[part 1 of 2: packages /VehicleProject to /Cluster]
AUTOSAR XML (schema 00048)
package /VehicleProject
  system System
package /NM
  nm config NmConfig: can-nm-cluster-coupling=coupled-cluster=[ATOM_CANFD_Matrix_CH_V600_202502_CAN, TC37X_VCU_CAN00_CAN, TC37X_VCU_CAN01_CAN, TC37X_VCU_CAN03_CAN, TC37X_VCU_CAN12_CAN]
    5 x can nm cluster, all with nm-msg-cycle-time=0.5, nm-network-timeout=2, nm-repeat-message-time=1.5, nm-user-data-length=6, nm-wait-bus-sleep-time=2:
      ATOM_CANFD_Matrix_CH_V600_202502_CAN: communication-cluster=ATOM_CANFD_Matrix_CH_V600_202502, nm-channel-id=4
        7 x can nm node, all with nm-node-id=28, nm-msg-cycle-offset=0, nm-msg-reduced-time=0.32, nm-range-config={lower-can-id=1280, upper-can-id=1407}:
          ACU: nm-if-ecu=ACU_CAN, nm-passive-mode-enabled=true
          ADCU_CH: nm-if-ecu=ADCU_CH_CAN, nm-passive-mode-enabled=true, rx-nm-pdu=NM_VCU_oATOM_CANFD_Matrix_CH_V600_202502
          AVAS: nm-if-ecu=AVAS_CAN, nm-passive-mode-enabled=true
          CGW_CH: nm-if-ecu=CGW_CH_CAN, rx-nm-pdu=NM_VCU_oATOM_CANFD_Matrix_CH_V600_202502, tx-nm-pdu=NM_CGW_oATOM_CANFD_Matrix_CH_V600_202502
          EPS: nm-if-ecu=EPS_CAN, nm-passive-mode-enabled=true
          IBS_CH: nm-if-ecu=IBS_CH_CAN, nm-passive-mode-enabled=true
          VCU: controller=CT_ATOM_CANFD_Matrix_CH_V600_202502, nm-if-ecu=VCU_CAN, rx-nm-pdu=NM_CGW_oATOM_CANFD_Matrix_CH_V600_202502, tx-nm-pdu=NM_VCU_oATOM_CANFD_Matrix_CH_V600_202502
      TC37X_VCU_CAN00_CAN: communication-cluster=TC37X_VCU_CAN00, nm-channel-id=0
        can nm node GWM: nm-if-ecu=GWM_CAN, nm-node-id=28, rx-nm-pdu=VCU_Tx_51Ch_NM_oTC37X_VCU_CAN00, tx-nm-pdu=VCU_Rx_500h_NM_oTC37X_VCU_CAN00, nm-msg-cycle-offset=0, nm-msg-reduced-time=0.32, nm-range-config={lower-can-id=1024, upper-can-id=1151}
        can nm node Tester: nm-if-ecu=Tester_CAN, nm-node-id=28, nm-passive-mode-enabled=true, nm-msg-cycle-offset=0, nm-msg-reduced-time=0.32, nm-range-config={lower-can-id=1024, upper-can-id=1151}
        can nm node VCU: controller=CT_TC37X_VCU_CAN00, nm-if-ecu=VCU_CAN, nm-node-id=28, rx-nm-pdu=VCU_Rx_500h_NM_oTC37X_VCU_CAN00, tx-nm-pdu=VCU_Tx_51Ch_NM_oTC37X_VCU_CAN00, nm-msg-cycle-offset=0, nm-msg-reduced-time=0.32, nm-range-config={lower-can-id=1024, upper-can-id=1151}
      TC37X_VCU_CAN01_CAN: communication-cluster=TC37X_VCU_CAN01, nm-channel-id=1
        can nm node GWM: nm-if-ecu=GWM_CAN, nm-node-id=28, rx-nm-pdu=VCU_Tx_51Ch_NM_oTC37X_VCU_CAN01, tx-nm-pdu=VCU_Rx_500h_NM_oTC37X_VCU_CAN01, nm-msg-cycle-offset=0, nm-msg-reduced-time=0.32, nm-range-config={lower-can-id=1024, upper-can-id=1151}
        can nm node Tester: nm-if-ecu=Tester_CAN, nm-node-id=28, nm-passive-mode-enabled=true, nm-msg-cycle-offset=0, nm-msg-reduced-time=0.32, nm-range-config={lower-can-id=1024, upper-can-id=1151}
        can nm node VCU: controller=CT_TC37X_VCU_CAN01, nm-if-ecu=VCU_CAN, nm-node-id=28, rx-nm-pdu=VCU_Rx_500h_NM_oTC37X_VCU_CAN01, tx-nm-pdu=VCU_Tx_51Ch_NM_oTC37X_VCU_CAN01, nm-msg-cycle-offset=0, nm-msg-reduced-time=0.32, nm-range-config={lower-can-id=1024, upper-can-id=1151}
      TC37X_VCU_CAN03_CAN: communication-cluster=TC37X_VCU_CAN03, nm-channel-id=3
        can nm node GWM: nm-if-ecu=GWM_CAN, nm-node-id=28, rx-nm-pdu=VCU_Tx_51Ch_NM_oTC37X_VCU_CAN03, tx-nm-pdu=VCU_Rx_500h_NM_oTC37X_VCU_CAN03, nm-msg-cycle-offset=0, nm-msg-reduced-time=0.32, nm-range-config={lower-can-id=1024, upper-can-id=1151}
        can nm node Tester: nm-if-ecu=Tester_CAN, nm-node-id=28, nm-passive-mode-enabled=true, nm-msg-cycle-offset=0, nm-msg-reduced-time=0.32, nm-range-config={lower-can-id=1024, upper-can-id=1151}
        can nm node VCU: controller=CT_TC37X_VCU_CAN03, nm-if-ecu=VCU_CAN, nm-node-id=28, rx-nm-pdu=VCU_Rx_500h_NM_oTC37X_VCU_CAN03, tx-nm-pdu=VCU_Tx_51Ch_NM_oTC37X_VCU_CAN03, nm-msg-cycle-offset=0, nm-msg-reduced-time=0.32, nm-range-config={lower-can-id=1024, upper-can-id=1151}
      TC37X_VCU_CAN12_CAN: communication-cluster=TC37X_VCU_CAN12, nm-channel-id=2
        can nm node GWM: nm-if-ecu=GWM_CAN, nm-node-id=28, rx-nm-pdu=VCU_Tx_51Ch_NM_oTC37X_VCU_CAN12, tx-nm-pdu=VCU_Rx_500h_NM_oTC37X_VCU_CAN12, nm-msg-cycle-offset=0, nm-msg-reduced-time=0.32, nm-range-config={lower-can-id=1024, upper-can-id=1151}
        can nm node Tester: nm-if-ecu=Tester_CAN, nm-node-id=28, nm-passive-mode-enabled=true, nm-msg-cycle-offset=0, nm-msg-reduced-time=0.32, nm-range-config={lower-can-id=1024, upper-can-id=1151}
        can nm node VCU: controller=CT_TC37X_VCU_CAN12, nm-if-ecu=VCU_CAN, nm-node-id=28, rx-nm-pdu=VCU_Rx_500h_NM_oTC37X_VCU_CAN12, tx-nm-pdu=VCU_Tx_51Ch_NM_oTC37X_VCU_CAN12, nm-msg-cycle-offset=0, nm-msg-reduced-time=0.32, nm-range-config={lower-can-id=1024, upper-can-id=1151}
    nm-if-ecus:
      9 x nm ecu, all with nm-node-id-enabled=true, nm-user-data-enabled=true:
        ACU_CAN: nm-passive-mode-enabled=true
        ADCU_CH_CAN: nm-passive-mode-enabled=true
        AVAS_CAN: nm-passive-mode-enabled=true
        CGW_CH_CAN
        EPS_CAN: nm-passive-mode-enabled=true
        GWM_CAN
        IBS_CH_CAN: nm-passive-mode-enabled=true
        Tester_CAN: nm-passive-mode-enabled=true
        VCU_CAN: ecu-instance=VCU
package /TP
  can tp config ATOM_CANFD_Matrix_CH_V600_202502_CAN: communication-cluster=ATOM_CANFD_Matrix_CH_V600_202502, can-tp-ecu{cycle-time-main-function=0.005, ecu-instance=VCU}
    can tp node TN_VCU: connector=CN_ATOM_CANFD_Matrix_CH_V600_202502
  can tp config TC37X_VCU_CAN00_CAN: communication-cluster=TC37X_VCU_CAN00, can-tp-ecu{cycle-time-main-function=0.005, ecu-instance=VCU}
    can tp channel TPCH: channel-id=0, channel-mode=FULL-DUPLEX-MODE
    can-tp-connection addressing-format=STANDARD, can-tp-channel=TPCH, data-pdu=Vcu_Uds_Func_Request_Tp_oTC37X_VCU_CAN00, receiver=TC37X_VCU_CAN00_CAN/TN_VCU, ta-type=FUNCTIONAL, tp-sdu=Vcu_Uds_Func_Request_oTC37X_VCU_CAN00, transmitter=TN_Tester:
      ident Vcu_Uds_Func_Request_oTN_Tester
    can-tp-connection addressing-format=STANDARD, can-tp-channel=TPCH, data-pdu=Vcu_Uds_Phy_Request_Tp_oTC37X_VCU_CAN00, flow-control-pdu=Vcu_Uds_Response_Tp_oTC37X_VCU_CAN00, receiver=TC37X_VCU_CAN00_CAN/TN_VCU, ta-type=PHYSICAL, tp-sdu=Vcu_Uds_Phy_Request_oTC37X_VCU_CAN00, transmitter=TN_Tester:
      ident Vcu_Uds_Phy_Request_oTN_VCU
    can-tp-connection addressing-format=STANDARD, can-tp-channel=TPCH, data-pdu=Vcu_Uds_Response_Tp_oTC37X_VCU_CAN00, flow-control-pdu=Vcu_Uds_Phy_Request_Tp_oTC37X_VCU_CAN00, receiver=TN_Tester, ta-type=PHYSICAL, tp-sdu=Vcu_Uds_Response_oTC37X_VCU_CAN00, transmitter=TC37X_VCU_CAN00_CAN/TN_VCU:
      ident Vcu_Uds_Response_oTN_VCU
    can tp node TN_Tester
    can tp node TN_VCU: connector=CN_TC37X_VCU_CAN00
  lin tp config LIN00: communication-cluster=LIN00
    8 x tp address:
      TA_0x005B: tp-address=91
      TA_0x0062: tp-address=98
      TA_0x0063: tp-address=99
      TA_0x0064: tp-address=100
      TA_0x0065: tp-address=101
      TA_0x0074: tp-address=116
      TA_0x0075: tp-address=117
      TA_0x007E: tp-address=126
    tp-connections:
      data-pdu=MasterReq_Tp_oLIN00, lin-tp-n-sdu=MasterReq_oLIN00, multicast=LIN00/TA_0x007E, receiver=[TN_0x005B_HVCH, TN_0x0062_ERV, TN_0x0063_EXV_1, TN_0x0064_EXV_2, TN_0x0065_SVA, TN_0x0074_PMP_1, TN_0x0075_PMP_2], transmitter=LIN00/TN_Master
      data-pdu=SlaveResp_Tp_oLIN00, flow-control=MasterReq_Tp_oLIN00, lin-tp-n-sdu=SlaveResp_HVCH_oLIN00, receiver=LIN00/TN_Master, transmitter=TN_0x005B_HVCH
      data-pdu=SlaveResp_Tp_oLIN00, flow-control=MasterReq_Tp_oLIN00, lin-tp-n-sdu=SlaveResp_ERV_oLIN00, receiver=LIN00/TN_Master, transmitter=TN_0x0062_ERV
      data-pdu=SlaveResp_Tp_oLIN00, flow-control=MasterReq_Tp_oLIN00, lin-tp-n-sdu=SlaveResp_EXV_1_oLIN00, receiver=LIN00/TN_Master, transmitter=TN_0x0063_EXV_1
      data-pdu=SlaveResp_Tp_oLIN00, flow-control=MasterReq_Tp_oLIN00, lin-tp-n-sdu=SlaveResp_EXV_2_oLIN00, receiver=LIN00/TN_Master, transmitter=TN_0x0064_EXV_2
      data-pdu=SlaveResp_Tp_oLIN00, flow-control=MasterReq_Tp_oLIN00, lin-tp-n-sdu=SlaveResp_SVA_oLIN00, receiver=LIN00/TN_Master, transmitter=TN_0x0065_SVA
      data-pdu=SlaveResp_Tp_oLIN00, flow-control=MasterReq_Tp_oLIN00, lin-tp-n-sdu=SlaveResp_PMP_1_oLIN00, receiver=LIN00/TN_Master, transmitter=TN_0x0074_PMP_1
      data-pdu=SlaveResp_Tp_oLIN00, flow-control=MasterReq_Tp_oLIN00, lin-tp-n-sdu=SlaveResp_PMP_2_oLIN00, receiver=LIN00/TN_Master, transmitter=TN_0x0075_PMP_2
      data-pdu=MasterReq_Tp_oLIN00, flow-control=SlaveResp_Tp_oLIN00, lin-tp-n-sdu=MasterReq_HVCH_oLIN00, receiver=TN_0x005B_HVCH, transmitter=LIN00/TN_Master
      data-pdu=MasterReq_Tp_oLIN00, flow-control=SlaveResp_Tp_oLIN00, lin-tp-n-sdu=MasterReq_ERV_oLIN00, receiver=TN_0x0062_ERV, transmitter=LIN00/TN_Master
      data-pdu=MasterReq_Tp_oLIN00, flow-control=SlaveResp_Tp_oLIN00, lin-tp-n-sdu=MasterReq_EXV_1_oLIN00, receiver=TN_0x0063_EXV_1, transmitter=LIN00/TN_Master
      data-pdu=MasterReq_Tp_oLIN00, flow-control=SlaveResp_Tp_oLIN00, lin-tp-n-sdu=MasterReq_EXV_2_oLIN00, receiver=TN_0x0064_EXV_2, transmitter=LIN00/TN_Master
      data-pdu=MasterReq_Tp_oLIN00, flow-control=SlaveResp_Tp_oLIN00, lin-tp-n-sdu=MasterReq_SVA_oLIN00, receiver=TN_0x0065_SVA, transmitter=LIN00/TN_Master
      data-pdu=MasterReq_Tp_oLIN00, flow-control=SlaveResp_Tp_oLIN00, lin-tp-n-sdu=MasterReq_PMP_1_oLIN00, receiver=TN_0x0074_PMP_1, transmitter=LIN00/TN_Master
      data-pdu=MasterReq_Tp_oLIN00, flow-control=SlaveResp_Tp_oLIN00, lin-tp-n-sdu=MasterReq_PMP_2_oLIN00, receiver=TN_0x0075_PMP_2, transmitter=LIN00/TN_Master
    8 x lin tp node:
      TN_0x005B_HVCH: tp-address=TA_0x005B
      TN_0x0062_ERV: tp-address=TA_0x0062
      TN_0x0063_EXV_1: tp-address=TA_0x0063
      TN_0x0064_EXV_2: tp-address=TA_0x0064
      TN_0x0065_SVA: tp-address=TA_0x0065
      TN_0x0074_PMP_1: tp-address=TA_0x0074
      TN_0x0075_PMP_2: tp-address=TA_0x0075
      TN_Master: connector=CN_LIN00
  lin tp config LIN01: communication-cluster=LIN01
    tp address TA_0x0052: tp-address=82
    tp address TA_0x007E: tp-address=126
    tp-connections:
      data-pdu=MasterReq_Tp_oLIN01, lin-tp-n-sdu=MasterReq_oLIN01, multicast=LIN01/TA_0x007E, receiver=TN_0x0052_GWM, transmitter=LIN01/TN_Master
      data-pdu=SlaveResp_Tp_oLIN01, flow-control=MasterReq_Tp_oLIN01, lin-tp-n-sdu=SlaveResp_GWM_oLIN01, receiver=LIN01/TN_Master, transmitter=TN_0x0052_GWM
      data-pdu=MasterReq_Tp_oLIN01, flow-control=SlaveResp_Tp_oLIN01, lin-tp-n-sdu=MasterReq_GWM_oLIN01, receiver=TN_0x0052_GWM, transmitter=LIN01/TN_Master
    lin tp node TN_0x0052_GWM: tp-address=TA_0x0052
    lin tp node TN_Master: connector=CN_LIN01
package /Cluster
  5 x can cluster, all with protocol-name=CAN:
    ATOM_CANFD_Matrix_CH_V600_202502  # ATOM_CANFD_Matrix_CH_V6.0.0_20250507 | Revision:V1.0, Revision:V1.0.1, Revision:V1.0.1, Revision:V1.0.1, Revision:V1.0.1, Revision:V1.0.2, Revision:V1.0.2, Revision:V1.0.2, Revision:V1.0.2, Revision:V1.0.2, Revision:V1.0.2, Revision:V1.0.2, Revision:V1.0.2, Revision:V1.0.2, Revision:V1.0.2, Revision:V1.0.2, Revision:V1.0.2, Revision:V1.0.2, Revision:V1.0.2, Revision:V1.0.2, Revision:V1.0.2, Revision:V1.0.2, Revision:V1.0.2, Revision:V1.0.2, Revision:V1.1, Revision:V1.1, Revision:V1.1, Revision:V1.1, Revision:V1.1, Revision:V1.1, Revision:V1.1, Revision:V1.1, Revision:V1.1, Revision:V1.1, Revision:V1.1, Revision:V1.1, Revision:V1.1, Revision:V1.1, Revision:V1.1, Revision:V1.1, Revision:V1.1, Revision:V1.1, Revision:V1.1, Revision:V1.1, Revision:V1.1, Revision:V1.1, Revision:V1.2, Revision:V0.1.3, Revision:V0.1.3, Revision:V0.1.3, Revision:V0.1.3, Revision:V0.1.3, Revision:V0.1.3, Revision:V0.1.3, Revision:V0.1.3, Revision:V0.1.3, Revision:V0.1.3, Revision:V0.1.3, Revision:V0.1.3, Revision:
      can physical channel CHNL: comm-connectors=CN_ATOM_CANFD_Matrix_CH_V600_202502
        frame ACU_01_oATOM_CANFD_Matrix_CH_V600_202502: id 0xF5, to VCU, frame-length=8, can-addressing-mode=STANDARD, can-frame-rx-behavior=ANY, can-frame-tx-behavior=CAN-FD
          pdu ACU_01_oATOM_CANFD_Matrix_CH_V600_202502: length=8, minimum-delay=0, transmission-mode-false-timing=cyclic-timing={time-offset=0, time-period=0.02}, transmission-mode-true-timing=cyclic-timing={time-offset=0, time-period=0.02}, unused-bit-pattern=0
            signal Checksum_0F5_oACU_01_oATOM_CANFD_Matrix_CH_V600_202502: start 7, 8 bit, big-endian, i-signal-type=PRIMITIVE, init-value=0, base-type=uint8, compu-method=CM_Checksum_0F5, data-constr=DC_Checksum_0F5, transfer-property=PENDING, to VCU  # Checksum signal for frame
            signal MessageCounter_0F5_oACU_01_oATOM_CANFD_Matrix_CH_V600_202502: start 11, 4 bit, big-endian, i-signal-type=PRIMITIVE, init-value=0, base-type=uint8, compu-method=CM_MessageCounter_0F5, data-constr=DC_MessageCounter_0F5, transfer-property=PENDING, to VCU  # Message counter signal for frame
            signal ACU_YawRate_oACU_01_oATOM_CANFD_Matrix_CH_V600_202502: start 23, 16 bit, big-endian, i-signal-type=PRIMITIVE, init-value=30000, base-type=uint16, compu-method=CM_ACU_YawRate, data-constr=DC_ACU_YawRate, unit=U_degreesYs, transfer-property=PENDING, to VCU  # Yaw rate (clockwise is negative, counterclockwise is positive)
            signal ACU_YawRateStatus_oACU_01_oATOM_CANFD_Matrix_CH_V600_202502: start 39, 2 bit, big-endian, i-signal-type=PRIMITIVE, init-value=0, base-type=uint8, compu-method=CM_ACU_YawRateStatus, data-constr=DC_ACU_YawRateStatus, transfer-property=PENDING, to VCU  # Yaw rate status
            mapping SG_ACU_01_SigGroup: i-signal-group=SG_ACU_01_SigGroup_oACU_01_oATOM_CANFD_Matrix_CH_V600_202502, transfer-property=PENDING
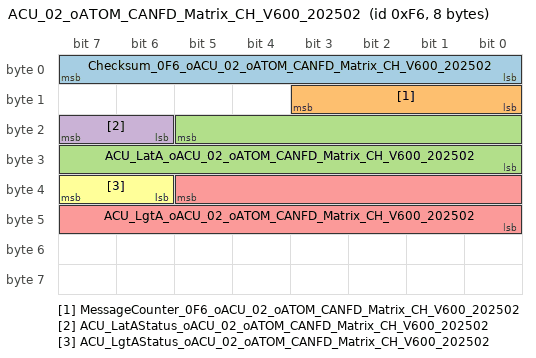
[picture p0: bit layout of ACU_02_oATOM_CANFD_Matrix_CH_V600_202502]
        frame ACU_02_oATOM_CANFD_Matrix_CH_V600_202502: id 0xF6, to VCU, frame-length=8, can-addressing-mode=STANDARD, can-frame-rx-behavior=ANY, can-frame-tx-behavior=CAN-FD
          pdu ACU_02_oATOM_CANFD_Matrix_CH_V600_202502: length=8, minimum-delay=0, transmission-mode-false-timing=cyclic-timing={time-offset=0, time-period=0.02}, transmission-mode-true-timing=cyclic-timing={time-offset=0, time-period=0.02}, unused-bit-pattern=0
            signal Checksum_0F6_oACU_02_oATOM_CANFD_Matrix_CH_V600_202502: start 7, 8 bit, big-endian, i-signal-type=PRIMITIVE, init-value=0, base-type=uint8, compu-method=CM_Checksum_0F6, data-constr=DC_Checksum_0F6, transfer-property=PENDING, to VCU  # Checksum signal for frame
            signal MessageCounter_0F6_oACU_02_oATOM_CANFD_Matrix_CH_V600_202502: start 11, 4 bit, big-endian, i-signal-type=PRIMITIVE, init-value=0, base-type=uint8, compu-method=CM_MessageCounter_0F6, data-constr=DC_MessageCounter_0F6, transfer-property=PENDING, to VCU  # Message counter signal for frame
            signal ACU_LatA_oACU_02_oATOM_CANFD_Matrix_CH_V600_202502: start 21, 14 bit, big-endian, i-signal-type=PRIMITIVE, init-value=4905, base-type=uint16, compu-method=CM_ACU_LatA, data-constr=DC_ACU_LatA, unit=U_mYsX2, transfer-property=PENDING, to VCU  # Lateral acceleration(From the driver's perspective, from left to right is the positive direction of lateral acceleration)
            signal ACU_LatAStatus_oACU_02_oATOM_CANFD_Matrix_CH_V600_202502: start 23, 2 bit, big-endian, i-signal-type=PRIMITIVE, init-value=0, base-type=uint8, compu-method=CM_ACU_LatAStatus, data-constr=DC_ACU_LatAStatus, transfer-property=PENDING, to VCU  # Lateral acceleration status
            signal ACU_LgtA_oACU_02_oATOM_CANFD_Matrix_CH_V600_202502: start 37, 14 bit, big-endian, i-signal-type=PRIMITIVE, init-value=4905, base-type=uint16, compu-method=CM_ACU_LgtA, data-constr=DC_ACU_LgtA, unit=U_mYsX2, transfer-property=PENDING, to VCU  # Longitudinal acceleration(The forward direction of the vehicle is the positive direction of the longitudinal acceleration)
            signal ACU_LgtAStatus_oACU_02_oATOM_CANFD_Matrix_CH_V600_202502: start 39, 2 bit, big-endian, i-signal-type=PRIMITIVE, init-value=0, base-type=uint8, compu-method=CM_ACU_LgtAStatus, data-constr=DC_ACU_LgtAStatus, transfer-property=PENDING, to VCU  # Longitudinal acceleration status
            mapping SG_ACU_02_SigGroup: i-signal-group=SG_ACU_02_SigGroup_oACU_02_oATOM_CANFD_Matrix_CH_V600_202502, transfer-property=PENDING
        frame ACU_info_oATOM_CANFD_Matrix_CH_V600_202502: id 0x97, to VCU, frame-length=8, can-addressing-mode=STANDARD, can-frame-rx-behavior=ANY, can-frame-tx-behavior=CAN-FD
          pdu ACU_info_oATOM_CANFD_Matrix_CH_V600_202502: length=8, minimum-delay=0, transmission-mode-false-timing=cyclic-timing={time-offset=0, time-period=0.02}, transmission-mode-true-timing=cyclic-timing={time-offset=0, time-period=0.02}, unused-bit-pattern=0
            signal Checksum_097_oACU_info_oATOM_CANFD_Matrix_CH_V600_202502: start 7, 8 bit, big-endian, i-signal-type=PRIMITIVE, init-value=0, base-type=uint8, compu-method=CM_Checksum_097, data-constr=DC_Checksum_097, transfer-property=PENDING, to VCU  # Checksum signal for frame
            signal MessageCounter_097_oACU_info_oATOM_CANFD_Matrix_CH_V600_202502: start 11, 4 bit, big-endian, i-signal-type=PRIMITIVE, init-value=0, base-type=uint8, compu-method=CM_MessageCounter_097, data-constr=DC_MessageCounter_097, transfer-property=PENDING, to VCU  # Message counter signal for frame
            signal ACU_CrashOutputStsValid_oACU_info_oATOM_CANFD_Matrix_CH_V600_202502: start 16, 1 bit, big-endian, i-signal-type=PRIMITIVE, init-value=1, base-type=boolean, compu-method=CM_ACU_CrashOutputStsValid, data-constr=DC_ACU_CrashOutputStsValid, transfer-property=PENDING, to VCU  # Collision signal effective indication
            signal ACU_CrashOutputSts_oACU_info_oATOM_CANFD_Matrix_CH_V600_202502: start 23, 5 bit, big-endian, i-signal-type=PRIMITIVE, init-value=0, base-type=uint8, compu-method=CM_ACU_CrashOutputSts, data-constr=DC_ACU_CrashOutputSts, transfer-property=PENDING, to VCU  # Crash Output Status
            signal ACU_PassengerSts_oACU_info_oATOM_CANFD_Matrix_CH_V600_202502: start 25, 1 bit, big-endian, i-signal-type=PRIMITIVE, init-value=0, base-type=boolean, compu-method=CM_ACU_PassengerSts, data-constr=DC_ACU_PassengerSts, transfer-property=PENDING, to VCU  # Passenger seat occupied state
            signal ACU_PassengerSeatBeltStsValid_oACU_info_oATOM_CANFD_Matrix_CH_V600_202502: start 26, 1 bit, big-endian, i-signal-type=PRIMITIVE, init-value=0, base-type=boolean, compu-method=CM_ACU_PassengerSeatBeltStsValid, data-constr=DC_ACU_PassengerSeatBeltStsValid, transfer-property=PENDING, to VCU  # Passenger seat belt status invalid signal
            signal ACU_PassengerSeatBeltSts_oACU_info_oATOM_CANFD_Matrix_CH_V600_202502: start 27, 1 bit, big-endian, i-signal-type=PRIMITIVE, init-value=0, base-type=boolean, compu-method=CM_ACU_PassengerSeatBeltSts, data-constr=DC_ACU_PassengerSeatBeltSts, transfer-property=PENDING, to VCU  # Passenger seat belt status
            signal ACU_DriverSeatBeltStsValid_oACU_info_oATOM_CANFD_Matrix_CH_V600_202502: start 30, 1 bit, big-endian, i-signal-type=PRIMITIVE, init-value=0, base-type=boolean, compu-method=CM_ACU_DriverSeatBeltStsValid, data-constr=DC_ACU_DriverSeatBeltStsValid, transfer-property=PENDING, to VCU  # Driver seat belt state invalid
            signal ACU_DriverSeatBeltSts_oACU_info_oATOM_CANFD_Matrix_CH_V600_202502: start 31, 1 bit, big-endian, i-signal-type=PRIMITIVE, init-value=0, base-type=boolean, compu-method=CM_ACU_DriverSeatBeltSts, data-constr=DC_ACU_DriverSeatBeltSts, transfer-property=PENDING, to VCU  # Driver seat belt status
            signal ACU_SecondLeftSts_oACU_info_oATOM_CANFD_Matrix_CH_V600_202502: start 37, 1 bit, big-endian, i-signal-type=PRIMITIVE, init-value=0, base-type=boolean, compu-method=CM_ACU_SecondLeftSts, data-constr=DC_ACU_SecondLeftSts, transfer-property=PENDING, to VCU  # The left seat of the second row is occupied
            signal ACU_RLSeatBeltStatusValid_oACU_info_oATOM_CANFD_Matrix_CH_V600_202502: start 38, 1 bit, big-endian, i-signal-type=PRIMITIVE, init-value=0, base-type=boolean, compu-method=CM_ACU_RLSeatBeltStatusValid, data-constr=DC_ACU_RLSeatBeltStatusValid, transfer-property=PENDING, to VCU  # Second row seat belt status on the left is valid
            signal ACU_SecondLeftSeatBeltSts_oACU_info_oATOM_CANFD_Matrix_CH_V600_202502: start 39, 1 bit, big-endian, i-signal-type=PRIMITIVE, init-value=0, base-type=boolean, compu-method=CM_ACU_SecondLeftSeatBeltSts, data-constr=DC_ACU_SecondLeftSeatBeltSts, transfer-property=PENDING, to VCU  # Second row left seat belt condition
            signal ACU_SecondRightSts_oACU_info_oATOM_CANFD_Matrix_CH_V600_202502: start 53, 1 bit, big-endian, i-signal-type=PRIMITIVE, init-value=0, base-type=boolean, compu-method=CM_ACU_SecondRightSts, data-constr=DC_ACU_SecondRightSts, transfer-property=PENDING, to VCU  # The right seat of the second row is occupied
            signal ACU_RRSeatBeltStatusValid_oACU_info_oATOM_CANFD_Matrix_CH_V600_202502: start 54, 1 bit, big-endian, i-signal-type=PRIMITIVE, init-value=0, base-type=boolean, compu-method=CM_ACU_RRSeatBeltStatusValid, data-constr=DC_ACU_RRSeatBeltStatusValid, transfer-property=PENDING, to VCU  # Second row seat belt status on the lright is valid
            signal ACU_SecondRightSeatBeltSts_oACU_info_oATOM_CANFD_Matrix_CH_V600_202502: start 55, 1 bit, big-endian, i-signal-type=PRIMITIVE, init-value=0, base-type=boolean, compu-method=CM_ACU_SecondRightSeatBeltSts, data-constr=DC_ACU_SecondRightSeatBeltSts, transfer-property=PENDING, to VCU  # Second row right seat belt status
            signal ACU_WarningLampSts_oACU_info_oATOM_CANFD_Matrix_CH_V600_202502: start 57, 2 bit, big-endian, i-signal-type=PRIMITIVE, init-value=0, base-type=uint8, compu-method=CM_ACU_WarningLampSts, data-constr=DC_ACU_WarningLampSts, transfer-property=PENDING, to VCU  # WarningLampStatus
            signal ACU_PassengerWarningLampSts_oACU_info_oATOM_CANFD_Matrix_CH_V600_202502: start 59, 2 bit, big-endian, i-signal-type=PRIMITIVE, init-value=0, base-type=uint8, compu-method=CM_ACU_PassengerWarningLampSts, data-constr=DC_ACU_PassengerWarningLampSts, transfer-property=PENDING, to VCU  # Passenger Warning Lamp Status
            signal ACU_DriverWarningLampSts_oACU_info_oATOM_CANFD_Matrix_CH_V600_202502: start 61, 2 bit, big-endian, i-signal-type=PRIMITIVE, init-value=0, base-type=uint8, compu-method=CM_ACU_DriverWarningLampSts, data-constr=DC_ACU_DriverWarningLampSts, transfer-property=PENDING, to VCU  # Driver Warning Lamp Status
            signal ACU_PassengerAirbagSts_oACU_info_oATOM_CANFD_Matrix_CH_V600_202502: start 63, 2 bit, big-endian, i-signal-type=PRIMITIVE, init-value=0, base-type=uint8, compu-method=CM_ACU_PassengerAirbagSts, data-constr=DC_ACU_PassengerAirbagSts, transfer-property=PENDING, to VCU  # Passenger Airbag Status, closed or not
            mapping SG_ACU_info_SigGroup: i-signal-group=SG_ACU_info_SigGroup_oACU_info_oATOM_CANFD_Matrix_CH_V600_202502, transfer-property=PENDING
        frame ADCU_ACC_02_oATOM_CANFD_Matrix_CH_V600_202502: id 0xE0, to VCU, frame-length=8, can-addressing-mode=STANDARD, can-frame-rx-behavior=ANY, can-frame-tx-behavior=CAN-FD
          pdu ADCU_ACC_02_oATOM_CANFD_Matrix_CH_V600_202502: length=8, minimum-delay=0, transmission-mode-false-timing=cyclic-timing={time-offset=0, time-period=0.02}, transmission-mode-true-timing=cyclic-timing={time-offset=0, time-period=0.02}, unused-bit-pattern=0
            signal Checksum_0E0_oADCU_ACC_02_oATOM_CANFD_Matrix_CH_V600_202502: start 7, 8 bit, big-endian, i-signal-type=PRIMITIVE, init-value=0, base-type=uint8, compu-method=CM_Checksum_0E0, data-constr=DC_Checksum_0E0, transfer-property=PENDING, to VCU  # Checksum signal for frame
            signal MessageCounter_0E0_oADCU_ACC_02_oATOM_CANFD_Matrix_CH_V600_202502: start 11, 4 bit, big-endian, i-signal-type=PRIMITIVE, init-value=0, base-type=uint8, compu-method=CM_MessageCounter_0E0, data-constr=DC_MessageCounter_0E0, transfer-property=PENDING, to VCU  # Message counter signal for frame
            signal ADCU_ACCDA_HandsOFF_Warning_oADCU_ACC_02_oATOM_CANFD_Matrix_CH_V600_202502: start 18, 3 bit, big-endian, i-signal-type=PRIMITIVE, init-value=0, base-type=uint8, compu-method=CM_ADCU_ACCDA_HandsOFF_Warning, data-constr=DC_ADCU_ACCDA_HandsOFF_Warning, transfer-property=PENDING, to VCU  # ACC/DA Hands off warning
            signal ADCU_ACC_Mode_oADCU_ACC_02_oATOM_CANFD_Matrix_CH_V600_202502: start 21, 3 bit, big-endian, i-signal-type=PRIMITIVE, init-value=0, base-type=uint8, compu-method=CM_ADCU_ACC_Mode, data-constr=DC_ADCU_ACC_Mode, transfer-property=PENDING, to VCU  # ACC mode for system state
            signal ADCU_ACCDA_SYS_Failure_oADCU_ACC_02_oATOM_CANFD_Matrix_CH_V600_202502: start 23, 2 bit, big-endian, i-signal-type=PRIMITIVE, init-value=0, base-type=uint8, compu-method=CM_ADCU_ACCDA_SYS_Failure, data-constr=DC_ADCU_ACCDA_SYS_Failure, transfer-property=PENDING, to VCU  # ACC/DA system failure state If this signal is set to anything other than 0, the IBS shall ignore any requests from ACC
            mapping SG_ADCU_ACC_02_SigGroup: i-signal-group=SG_ADCU_ACC_02_SigGroup_oADCU_ACC_02_oATOM_CANFD_Matrix_CH_V600_202502, transfer-property=PENDING
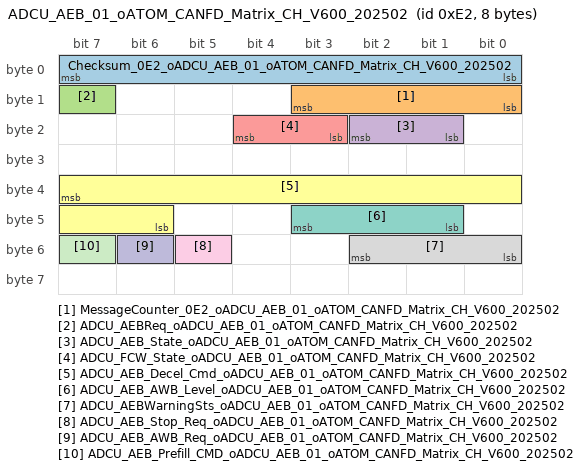
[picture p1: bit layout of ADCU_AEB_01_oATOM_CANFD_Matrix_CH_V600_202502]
        frame ADCU_AEB_01_oATOM_CANFD_Matrix_CH_V600_202502: id 0xE2, to VCU, frame-length=8, can-addressing-mode=STANDARD, can-frame-rx-behavior=ANY, can-frame-tx-behavior=CAN-FD
          pdu ADCU_AEB_01_oATOM_CANFD_Matrix_CH_V600_202502: length=8, minimum-delay=0, transmission-mode-false-timing=cyclic-timing={time-offset=0, time-period=0.02}, transmission-mode-true-timing=cyclic-timing={time-offset=0, time-period=0.02}, unused-bit-pattern=0
            signal Checksum_0E2_oADCU_AEB_01_oATOM_CANFD_Matrix_CH_V600_202502: start 7, 8 bit, big-endian, i-signal-type=PRIMITIVE, init-value=0, base-type=uint8, compu-method=CM_Checksum_0E2, data-constr=DC_Checksum_0E2, transfer-property=PENDING, to VCU  # Checksum signal for frame
            signal MessageCounter_0E2_oADCU_AEB_01_oATOM_CANFD_Matrix_CH_V600_202502: start 11, 4 bit, big-endian, i-signal-type=PRIMITIVE, init-value=0, base-type=uint8, compu-method=CM_MessageCounter_0E2, data-constr=DC_MessageCounter_0E2, transfer-property=PENDING, to VCU  # Message counter signal for frame
            signal ADCU_AEBReq_oADCU_AEB_01_oATOM_CANFD_Matrix_CH_V600_202502: start 15, 1 bit, big-endian, i-signal-type=PRIMITIVE, init-value=0, base-type=boolean, compu-method=CM_ADCU_AEBReq, data-constr=DC_ADCU_AEBReq, transfer-property=PENDING, to VCU  # A control requeset flag for AEB
            signal ADCU_AEB_State_oADCU_AEB_01_oATOM_CANFD_Matrix_CH_V600_202502: start 18, 2 bit, big-endian, i-signal-type=PRIMITIVE, init-value=0, base-type=uint8, compu-method=CM_ADCU_AEB_State, data-constr=DC_ADCU_AEB_State, transfer-property=PENDING, to VCU  # This signal describes the state AEB Function.
            signal ADCU_FCW_State_oADCU_AEB_01_oATOM_CANFD_Matrix_CH_V600_202502: start 20, 2 bit, big-endian, i-signal-type=PRIMITIVE, init-value=0, base-type=uint8, compu-method=CM_ADCU_FCW_State, data-constr=DC_ADCU_FCW_State, transfer-property=PENDING, to VCU  # This signal describes the state FCW Function.
            signal ADCU_AEB_Decel_Cmd_oADCU_AEB_01_oATOM_CANFD_Matrix_CH_V600_202502: start 39, 10 bit, big-endian, i-signal-type=PRIMITIVE, init-value=0, base-type=sint16, compu-method=CM_ADCU_AEB_Decel_Cmd, data-constr=DC_ADCU_AEB_Decel_Cmd, unit=U_mYsX2, transfer-property=PENDING, to VCU  # Depending on the driving situation, ADCU gives IBS the AEB deceleration command. IBS maintains the deceleration.
            signal ADCU_AEB_AWB_Level_oADCU_AEB_01_oATOM_CANFD_Matrix_CH_V600_202502: start 43, 3 bit, big-endian, i-signal-type=PRIMITIVE, init-value=0, base-type=uint8, compu-method=CM_ADCU_AEB_AWB_Level, data-constr=DC_ADCU_AEB_AWB_Level, transfer-property=PENDING, to VCU  # AWB level
            signal ADCU_AEBWarningSts_oADCU_AEB_01_oATOM_CANFD_Matrix_CH_V600_202502: start 50, 3 bit, big-endian, i-signal-type=PRIMITIVE, init-value=0, base-type=uint8, compu-method=CM_ADCU_AEBWarningSts, data-constr=DC_ADCU_AEBWarningSts, transfer-property=PENDING, to VCU  # PEBSWarning,include PreWarning and emergency Warning.
            signal ADCU_AEB_Stop_Req_oADCU_AEB_01_oATOM_CANFD_Matrix_CH_V600_202502: start 53, 1 bit, big-endian, i-signal-type=PRIMITIVE, init-value=0, base-type=boolean, compu-method=CM_ADCU_AEB_Stop_Req, data-constr=DC_ADCU_AEB_Stop_Req, transfer-property=PENDING, to VCU  # A control request flag for vehicle stop. AEB expects vehicle to be controlled to a complete stop and hold its state by ESC.
            signal ADCU_AEB_AWB_Req_oADCU_AEB_01_oATOM_CANFD_Matrix_CH_V600_202502: start 54, 1 bit, big-endian, i-signal-type=PRIMITIVE, init-value=0, base-type=boolean, compu-method=CM_ADCU_AEB_AWB_Req, data-constr=DC_ADCU_AEB_AWB_Req, transfer-property=PENDING, to VCU  # This signal means command to activate AWB
            signal ADCU_AEB_Prefill_CMD_oADCU_AEB_01_oATOM_CANFD_Matrix_CH_V600_202502: start 55, 1 bit, big-endian, i-signal-type=PRIMITIVE, init-value=0, base-type=boolean, compu-method=CM_ADCU_AEB_Prefill_CMD, data-constr=DC_ADCU_AEB_Prefill_CMD, transfer-property=PENDING, to VCU  # This signal means command to activate pre-fill
            mapping SG_ADCU_AEB_01_SigGroup: i-signal-group=SG_ADCU_AEB_01_SigGroup_oADCU_AEB_01_oATOM_CANFD_Matrix_CH_V600_202502, transfer-property=PENDING
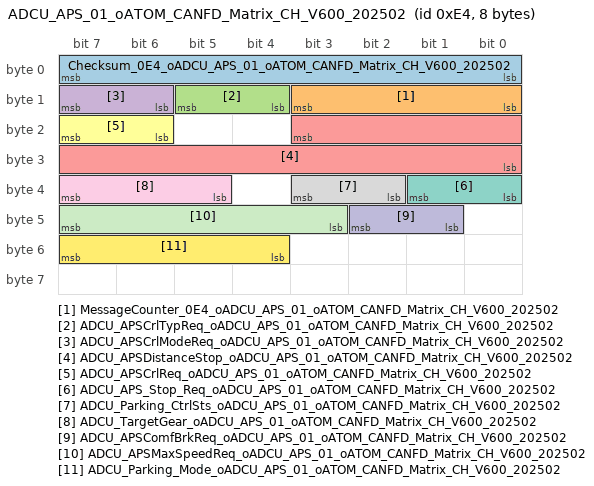
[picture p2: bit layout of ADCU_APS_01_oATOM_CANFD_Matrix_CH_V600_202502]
        frame ADCU_APS_01_oATOM_CANFD_Matrix_CH_V600_202502: id 0xE4, to VCU, frame-length=8, can-addressing-mode=STANDARD, can-frame-rx-behavior=ANY, can-frame-tx-behavior=CAN-FD
          pdu ADCU_APS_01_oATOM_CANFD_Matrix_CH_V600_202502: length=8, minimum-delay=0, transmission-mode-false-timing=cyclic-timing={time-offset=0, time-period=0.02}, transmission-mode-true-timing=cyclic-timing={time-offset=0, time-period=0.02}, unused-bit-pattern=0
            signal Checksum_0E4_oADCU_APS_01_oATOM_CANFD_Matrix_CH_V600_202502: start 7, 8 bit, big-endian, i-signal-type=PRIMITIVE, init-value=0, base-type=uint8, compu-method=CM_Checksum_0E4, data-constr=DC_Checksum_0E4, transfer-property=PENDING, to VCU  # Checksum signal for frame
            signal MessageCounter_0E4_oADCU_APS_01_oATOM_CANFD_Matrix_CH_V600_202502: start 11, 4 bit, big-endian, i-signal-type=PRIMITIVE, init-value=0, base-type=uint8, compu-method=CM_MessageCounter_0E4, data-constr=DC_MessageCounter_0E4, transfer-property=PENDING, to VCU  # Message counter signal for frame
            signal ADCU_APSCrlTypReq_oADCU_APS_01_oATOM_CANFD_Matrix_CH_V600_202502: start 13, 2 bit, big-endian, i-signal-type=PRIMITIVE, init-value=0, base-type=uint8, compu-method=CM_ADCU_APSCrlTypReq, data-constr=DC_ADCU_APSCrlTypReq, transfer-property=PENDING, to VCU  # Request comfort or emergency brake
            signal ADCU_APSCrlModeReq_oADCU_APS_01_oATOM_CANFD_Matrix_CH_V600_202502: start 15, 2 bit, big-endian, i-signal-type=PRIMITIVE, init-value=0, base-type=uint8, compu-method=CM_ADCU_APSCrlModeReq, data-constr=DC_ADCU_APSCrlModeReq, transfer-property=PENDING, to VCU  # Request Low Speed Maneuvering Control Mode (PAS (full/semi auto) or RC)
            signal ADCU_APSDistanceStop_oADCU_APS_01_oATOM_CANFD_Matrix_CH_V600_202502: start 19, 12 bit, big-endian, i-signal-type=PRIMITIVE, init-value=0, base-type=uint16, compu-method=CM_ADCU_APSDistanceStop, data-constr=DC_ADCU_APSDistanceStop, unit=U_cm, transfer-property=PENDING, to VCU  # Stopdistance request
            signal ADCU_APSCrlReq_oADCU_APS_01_oATOM_CANFD_Matrix_CH_V600_202502: start 23, 2 bit, big-endian, i-signal-type=PRIMITIVE, init-value=0, base-type=uint8, compu-method=CM_ADCU_APSCrlReq, data-constr=DC_ADCU_APSCrlReq, transfer-property=PENDING, to VCU  # Request Maneuvering dynamic control function (Driving or Low Speed Maneuvering)
            signal ADCU_APS_Stop_Req_oADCU_APS_01_oATOM_CANFD_Matrix_CH_V600_202502: start 33, 2 bit, big-endian, i-signal-type=PRIMITIVE, init-value=0, base-type=uint8, compu-method=CM_ADCU_APS_Stop_Req, data-constr=DC_ADCU_APS_Stop_Req, transfer-property=PENDING, to VCU  # Request complete stop and hold its state by IBS
            signal ADCU_Parking_CtrlSts_oADCU_APS_01_oATOM_CANFD_Matrix_CH_V600_202502: start 35, 2 bit, big-endian, i-signal-type=PRIMITIVE, init-value=0, base-type=uint8, compu-method=CM_ADCU_Parking_CtrlSts, data-constr=DC_ADCU_Parking_CtrlSts, transfer-property=PENDING, to VCU  # Parking indicator light status
            signal ADCU_TargetGear_oADCU_APS_01_oATOM_CANFD_Matrix_CH_V600_202502: start 39, 3 bit, big-endian, i-signal-type=PRIMITIVE, init-value=0, base-type=uint8, compu-method=CM_ADCU_TargetGear, data-constr=DC_ADCU_TargetGear, transfer-property=PENDING, to VCU  # Shift request signal
            signal ADCU_APSComfBrkReq_oADCU_APS_01_oATOM_CANFD_Matrix_CH_V600_202502: start 42, 2 bit, big-endian, i-signal-type=PRIMITIVE, init-value=0, base-type=uint8, compu-method=CM_ADCU_APSComfBrkReq, data-constr=DC_ADCU_APSComfBrkReq, transfer-property=PENDING, to VCU  # BrakeMode Request
            signal ADCU_APSMaxSpeedReq_oADCU_APS_01_oATOM_CANFD_Matrix_CH_V600_202502: start 47, 5 bit, big-endian, i-signal-type=PRIMITIVE, init-value=0, base-type=uint8, compu-method=CM_ADCU_APSMaxSpeedReq, data-constr=DC_ADCU_APSMaxSpeedReq, unit=U_kmYh, transfer-property=PENDING, to VCU  # V Max request
            signal ADCU_Parking_Mode_oADCU_APS_01_oATOM_CANFD_Matrix_CH_V600_202502: start 55, 4 bit, big-endian, i-signal-type=PRIMITIVE, init-value=0, base-type=uint8, compu-method=CM_ADCU_Parking_Mode, data-constr=DC_ADCU_Parking_Mode, transfer-property=PENDING, to VCU  # APS function status.
            mapping SG_ADCU_APS_01_SigGroup: i-signal-group=SG_ADCU_APS_01_SigGroup_oADCU_APS_01_oATOM_CANFD_Matrix_CH_V600_202502, transfer-property=PENDING
        frame ADCU_APS_02_oATOM_CANFD_Matrix_CH_V600_202502: id 0x20D, to VCU, frame-length=8, can-addressing-mode=STANDARD, can-frame-rx-behavior=ANY, can-frame-tx-behavior=CAN-FD
          pdu ADCU_APS_02_oATOM_CANFD_Matrix_CH_V600_202502: length=8, minimum-delay=0, transmission-mode-false-timing=cyclic-timing={time-offset=0, time-period=0.1}, transmission-mode-true-timing=cyclic-timing={time-offset=0, time-period=0.1}, unused-bit-pattern=0
            signal ADCU_RemoteParkingMode_oADCU_APS_02_oATOM_CANFD_Matrix_CH_V600_202502: start 23, 4 bit, big-endian, i-signal-type=PRIMITIVE, init-value=0, base-type=uint8, compu-method=CM_ADCU_RemoteParkingMode, data-constr=DC_ADCU_RemoteParkingMode, transfer-property=PENDING, to VCU  # Remote parking function status
            mapping SG_ADCU_APS_02_SigGroup: i-signal-group=SG_ADCU_APS_02_SigGroup_oADCU_APS_02_oATOM_CANFD_Matrix_CH_V600_202502, transfer-property=PENDING
        frame ADCU_DA_oATOM_CANFD_Matrix_CH_V600_202502: id 0xE6, to VCU, frame-length=8, can-addressing-mode=STANDARD, can-frame-rx-behavior=ANY, can-frame-tx-behavior=CAN-FD
          pdu ADCU_DA_oATOM_CANFD_Matrix_CH_V600_202502: length=8, minimum-delay=0, transmission-mode-false-timing=cyclic-timing={time-offset=0, time-period=0.1}, transmission-mode-true-timing=cyclic-timing={time-offset=0, time-period=0.1}, unused-bit-pattern=0
            signal Checksum_0E6_oADCU_DA_oATOM_CANFD_Matrix_CH_V600_202502: start 7, 8 bit, big-endian, i-signal-type=PRIMITIVE, init-value=0, base-type=uint8, compu-method=CM_Checksum_0E6, data-constr=DC_Checksum_0E6, transfer-property=PENDING, to VCU  # Checksum signal for frame
            signal MessageCounter_0E6_oADCU_DA_oATOM_CANFD_Matrix_CH_V600_202502: start 11, 4 bit, big-endian, i-signal-type=PRIMITIVE, init-value=0, base-type=uint8, compu-method=CM_MessageCounter_0E6, data-constr=DC_MessageCounter_0E6, transfer-property=PENDING, to VCU  # Message counter signal for frame
            signal ADCU_DA_Mode_oADCU_DA_oATOM_CANFD_Matrix_CH_V600_202502: start 23, 3 bit, big-endian, i-signal-type=PRIMITIVE, init-value=0, base-type=uint8, compu-method=CM_ADCU_DA_Mode, data-constr=DC_ADCU_DA_Mode, transfer-property=PENDING, to VCU  # DA mode for system state
            mapping SG_ADCU_DA_SigGroup: i-signal-group=SG_ADCU_DA_SigGroup_oADCU_DA_oATOM_CANFD_Matrix_CH_V600_202502, transfer-property=PENDING
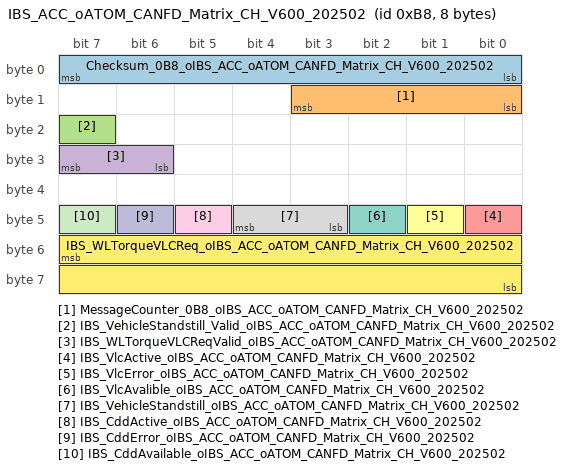
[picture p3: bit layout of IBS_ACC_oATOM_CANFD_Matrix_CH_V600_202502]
        frame IBS_ACC_oATOM_CANFD_Matrix_CH_V600_202502: id 0xB8, to VCU, frame-length=8, can-addressing-mode=STANDARD, can-frame-rx-behavior=ANY, can-frame-tx-behavior=CAN-FD
          pdu IBS_ACC_oATOM_CANFD_Matrix_CH_V600_202502: length=8, minimum-delay=0, transmission-mode-false-timing=cyclic-timing={time-offset=0, time-period=0.02}, transmission-mode-true-timing=cyclic-timing={time-offset=0, time-period=0.02}, unused-bit-pattern=0
            signal Checksum_0B8_oIBS_ACC_oATOM_CANFD_Matrix_CH_V600_202502: start 7, 8 bit, big-endian, i-signal-type=PRIMITIVE, init-value=0, base-type=uint8, compu-method=CM_Checksum_0B8, data-constr=DC_Checksum_0B8, transfer-property=PENDING, to VCU  # Checksum signal for frame
            signal MessageCounter_0B8_oIBS_ACC_oATOM_CANFD_Matrix_CH_V600_202502: start 11, 4 bit, big-endian, i-signal-type=PRIMITIVE, init-value=0, base-type=uint8, compu-method=CM_MessageCounter_0B8, data-constr=DC_MessageCounter_0B8, transfer-property=PENDING, to VCU  # Message counter signal for frame
            signal IBS_VehicleStandstill_Valid_oIBS_ACC_oATOM_CANFD_Matrix_CH_V600_202502: start 23, 1 bit, big-endian, i-signal-type=PRIMITIVE, init-value=0, base-type=boolean, compu-method=CM_IBS_VehicleStandstill_Valid, data-constr=DC_IBS_VehicleStandstill_Valid, transfer-property=PENDING, to VCU  # Validity of indicating signal IBS_vehiclestill
            signal IBS_WLTorqueVLCReqValid_oIBS_ACC_oATOM_CANFD_Matrix_CH_V600_202502: start 31, 2 bit, big-endian, i-signal-type=PRIMITIVE, init-value=0, base-type=uint8, compu-method=CM_IBS_WLTorqueVLCReqValid, data-constr=DC_IBS_WLTorqueVLCReqValid, transfer-property=PENDING, to VCU  # VLC Wheel Torque Request Valid
            signal IBS_VlcActive_oIBS_ACC_oATOM_CANFD_Matrix_CH_V600_202502: start 40, 1 bit, big-endian, i-signal-type=PRIMITIVE, init-value=0, base-type=boolean, compu-method=CM_IBS_VlcActive, data-constr=DC_IBS_VlcActive, transfer-property=PENDING, to VCU  # Indicates VLC is active or not.
            signal IBS_VlcError_oIBS_ACC_oATOM_CANFD_Matrix_CH_V600_202502: start 41, 1 bit, big-endian, i-signal-type=PRIMITIVE, init-value=0, base-type=boolean, compu-method=CM_IBS_VlcError, data-constr=DC_IBS_VlcError, transfer-property=PENDING, to VCU  # Indicate the failure status of VLC.
            signal IBS_VlcAvalible_oIBS_ACC_oATOM_CANFD_Matrix_CH_V600_202502: start 42, 1 bit, big-endian, i-signal-type=PRIMITIVE, init-value=0, base-type=boolean, compu-method=CM_IBS_VlcAvalible, data-constr=DC_IBS_VlcAvalible, transfer-property=PENDING, to VCU  # Indicating whether VLC is basically ready for activation or not. It could be combined with VLCFail.
            signal IBS_VehicleStandstill_oIBS_ACC_oATOM_CANFD_Matrix_CH_V600_202502: start 44, 2 bit, big-endian, i-signal-type=PRIMITIVE, init-value=0, base-type=uint8, compu-method=CM_IBS_VehicleStandstill, data-constr=DC_IBS_VehicleStandstill, transfer-property=PENDING, to VCU  # Indicating whether the vehicle is standstill or not Cannot be set until standstill is surely reached.
            signal IBS_CddActive_oIBS_ACC_oATOM_CANFD_Matrix_CH_V600_202502: start 45, 1 bit, big-endian, i-signal-type=PRIMITIVE, init-value=0, base-type=boolean, compu-method=CM_IBS_CddActive, data-constr=DC_IBS_CddActive, transfer-property=PENDING, to VCU  # Indicate CDD is active or not.
            signal IBS_CddError_oIBS_ACC_oATOM_CANFD_Matrix_CH_V600_202502: start 46, 1 bit, big-endian, i-signal-type=PRIMITIVE, init-value=0, base-type=boolean, compu-method=CM_IBS_CddError, data-constr=DC_IBS_CddError, transfer-property=PENDING, to VCU  # Indicate the failure status of CDD
            signal IBS_CddAvailable_oIBS_ACC_oATOM_CANFD_Matrix_CH_V600_202502: start 47, 1 bit, big-endian, i-signal-type=PRIMITIVE, init-value=0, base-type=boolean, compu-method=CM_IBS_CddAvailable, data-constr=DC_IBS_CddAvailable, transfer-property=PENDING, to VCU  # Indicate CDD is available or not.
            signal IBS_WLTorqueVLCReq_oIBS_ACC_oATOM_CANFD_Matrix_CH_V600_202502: start 55, 16 bit, big-endian, i-signal-type=PRIMITIVE, init-value=0, base-type=sint16, compu-method=CM_IBS_WLTorqueVLCReq, data-constr=DC_IBS_WLTorqueVLCReq, unit=U_Nm, transfer-property=PENDING, to VCU  # VLC Wheel Torque Request
            mapping SG_IBS_ACC_SigGroup: i-signal-group=SG_IBS_ACC_SigGroup_oIBS_ACC_oATOM_CANFD_Matrix_CH_V600_202502, transfer-property=PENDING
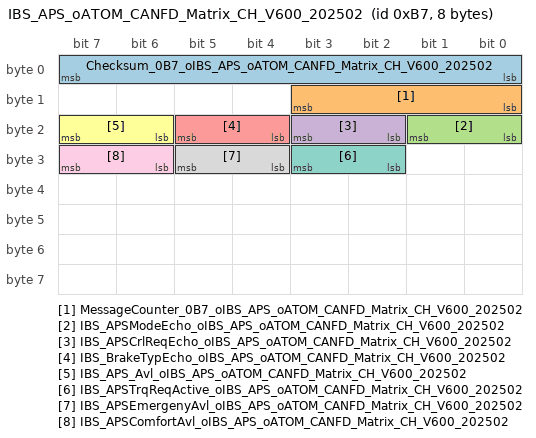
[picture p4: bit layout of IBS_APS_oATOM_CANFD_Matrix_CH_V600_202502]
        frame IBS_APS_oATOM_CANFD_Matrix_CH_V600_202502: id 0xB7, to VCU, frame-length=8, can-addressing-mode=STANDARD, can-frame-rx-behavior=ANY, can-frame-tx-behavior=CAN-FD
          pdu IBS_APS_oATOM_CANFD_Matrix_CH_V600_202502: length=8, minimum-delay=0, transmission-mode-false-timing=cyclic-timing={time-offset=0, time-period=0.02}, transmission-mode-true-timing=cyclic-timing={time-offset=0, time-period=0.02}, unused-bit-pattern=0
            signal Checksum_0B7_oIBS_APS_oATOM_CANFD_Matrix_CH_V600_202502: start 7, 8 bit, big-endian, i-signal-type=PRIMITIVE, init-value=0, base-type=uint8, compu-method=CM_Checksum_0B7, data-constr=DC_Checksum_0B7, transfer-property=PENDING, to VCU  # Checksum signal for frame
            signal MessageCounter_0B7_oIBS_APS_oATOM_CANFD_Matrix_CH_V600_202502: start 11, 4 bit, big-endian, i-signal-type=PRIMITIVE, init-value=0, base-type=uint8, compu-method=CM_MessageCounter_0B7, data-constr=DC_MessageCounter_0B7, transfer-property=PENDING, to VCU  # Message counter signal for frame
            signal IBS_APSModeEcho_oIBS_APS_oATOM_CANFD_Matrix_CH_V600_202502: start 17, 2 bit, big-endian, i-signal-type=PRIMITIVE, init-value=0, base-type=uint8, compu-method=CM_IBS_APSModeEcho, data-constr=DC_IBS_APSModeEcho, transfer-property=PENDING, to VCU  # FeedbackÂ to upper system
            signal IBS_APSCrlReqEcho_oIBS_APS_oATOM_CANFD_Matrix_CH_V600_202502: start 19, 2 bit, big-endian, i-signal-type=PRIMITIVE, init-value=0, base-type=uint8, compu-method=CM_IBS_APSCrlReqEcho, data-constr=DC_IBS_APSCrlReqEcho, transfer-property=PENDING, to VCU  # Feedback control status to upper system
            signal IBS_BrakeTypEcho_oIBS_APS_oATOM_CANFD_Matrix_CH_V600_202502: start 21, 2 bit, big-endian, i-signal-type=PRIMITIVE, init-value=0, base-type=uint8, compu-method=CM_IBS_BrakeTypEcho, data-constr=DC_IBS_BrakeTypEcho, transfer-property=PENDING, to VCU  # Feedback Comfort or emergency to upper system
            signal IBS_APS_Avl_oIBS_APS_oATOM_CANFD_Matrix_CH_V600_202502: start 23, 2 bit, big-endian, i-signal-type=PRIMITIVE, init-value=0, base-type=uint8, compu-method=CM_IBS_APS_Avl, data-constr=DC_IBS_APS_Avl, transfer-property=PENDING, to VCU  # Indicate the function availability
            signal IBS_APSTrqReqActive_oIBS_APS_oATOM_CANFD_Matrix_CH_V600_202502: start 27, 2 bit, big-endian, i-signal-type=PRIMITIVE, init-value=0, base-type=uint8, compu-method=CM_IBS_APSTrqReqActive, data-constr=DC_IBS_APSTrqReqActive, transfer-property=PENDING, to VCU  # APS function activation flag bit
            signal IBS_APSEmergenyAvl_oIBS_APS_oATOM_CANFD_Matrix_CH_V600_202502: start 29, 2 bit, big-endian, i-signal-type=PRIMITIVE, init-value=0, base-type=uint8, compu-method=CM_IBS_APSEmergenyAvl, data-constr=DC_IBS_APSEmergenyAvl, transfer-property=PENDING, to VCU  # Feedback ofÂ APS Emergency Availability
            signal IBS_APSComfortAvl_oIBS_APS_oATOM_CANFD_Matrix_CH_V600_202502: start 31, 2 bit, big-endian, i-signal-type=PRIMITIVE, init-value=0, base-type=uint8, compu-method=CM_IBS_APSComfortAvl, data-constr=DC_IBS_APSComfortAvl, transfer-property=PENDING, to VCU  # Feedback of APS Comfort Availability
            mapping SG_IBS_APS_SigGroup: i-signal-group=SG_IBS_APS_SigGroup_oIBS_APS_oATOM_CANFD_Matrix_CH_V600_202502, transfer-property=PENDING
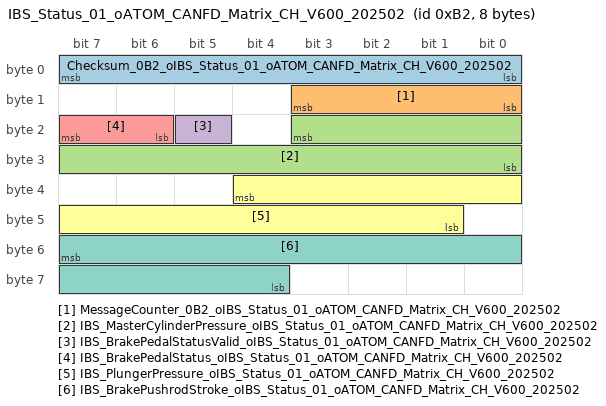
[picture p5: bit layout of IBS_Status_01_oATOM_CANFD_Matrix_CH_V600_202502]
        frame IBS_Status_01_oATOM_CANFD_Matrix_CH_V600_202502: id 0xB2, to VCU, frame-length=8, can-addressing-mode=STANDARD, can-frame-rx-behavior=ANY, can-frame-tx-behavior=CAN-FD
          pdu IBS_Status_01_oATOM_CANFD_Matrix_CH_V600_202502: length=8, minimum-delay=0, transmission-mode-false-timing=cyclic-timing={time-offset=0, time-period=0.02}, transmission-mode-true-timing=cyclic-timing={time-offset=0, time-period=0.02}, unused-bit-pattern=0
            signal Checksum_0B2_oIBS_Status_01_oATOM_CANFD_Matrix_CH_V600_202502: start 7, 8 bit, big-endian, i-signal-type=PRIMITIVE, init-value=0, base-type=uint8, compu-method=CM_Checksum_0B2, data-constr=DC_Checksum_0B2, transfer-property=PENDING, to VCU  # Checksum signal for frame
            signal MessageCounter_0B2_oIBS_Status_01_oATOM_CANFD_Matrix_CH_V600_202502: start 11, 4 bit, big-endian, i-signal-type=PRIMITIVE, init-value=0, base-type=uint8, compu-method=CM_MessageCounter_0B2, data-constr=DC_MessageCounter_0B2, transfer-property=PENDING, to VCU  # Message counter signal for frame
            signal IBS_MasterCylinderPressure_oIBS_Status_01_oATOM_CANFD_Matrix_CH_V600_202502: start 19, 12 bit, big-endian, i-signal-type=PRIMITIVE, init-value=0, base-type=uint16, compu-method=CM_IBS_MasterCylinderPressure, data-constr=DC_IBS_MasterCylinderPressure, unit=U_BAR, transfer-property=PENDING, to VCU  # EN: Master Cylinder Pressure signal
            signal IBS_BrakePedalStatusValid_oIBS_Status_01_oATOM_CANFD_Matrix_CH_V600_202502: start 21, 1 bit, big-endian, i-signal-type=PRIMITIVE, init-value=1, base-type=boolean, compu-method=CM_IBS_BrakePedalStatusValid, data-constr=DC_IBS_BrakePedalStatusValid, transfer-property=PENDING, to VCU  # Brake Pedal Status Valid
            signal IBS_BrakePedalStatus_oIBS_Status_01_oATOM_CANFD_Matrix_CH_V600_202502: start 23, 2 bit, big-endian, i-signal-type=PRIMITIVE, init-value=0, base-type=uint8, compu-method=CM_IBS_BrakePedalStatus, data-constr=DC_IBS_BrakePedalStatus, transfer-property=PENDING, to VCU  # Brake Pedal Status
            signal IBS_PlungerPressure_oIBS_Status_01_oATOM_CANFD_Matrix_CH_V600_202502: start 36, 12 bit, big-endian, i-signal-type=PRIMITIVE, init-value=0, base-type=sint16, compu-method=CM_IBS_PlungerPressure, data-constr=DC_IBS_PlungerPressure, unit=U_BAR, transfer-property=PENDING, to VCU  # pressure of PSU
            signal IBS_BrakePushrodStroke_oIBS_Status_01_oATOM_CANFD_Matrix_CH_V600_202502: start 55, 12 bit, big-endian, i-signal-type=PRIMITIVE, init-value=0, base-type=sint16, compu-method=CM_IBS_BrakePushrodStroke, data-constr=DC_IBS_BrakePushrodStroke, unit=U_mm, transfer-property=PENDING, to VCU  # IBS pushrod stroke
            mapping SG_IBS_Status_01_SigGroup: i-signal-group=SG_IBS_Status_01_SigGroup_oIBS_Status_01_oATOM_CANFD_Matrix_CH_V600_202502, transfer-property=PENDING
        frame IBS_Status_02_oATOM_CANFD_Matrix_CH_V600_202502: id 0xB3, to VCU, frame-length=8, can-addressing-mode=STANDARD, can-frame-rx-behavior=ANY, can-frame-tx-behavior=CAN-FD
          pdu IBS_Status_02_oATOM_CANFD_Matrix_CH_V600_202502: length=8, minimum-delay=0, transmission-mode-false-timing=cyclic-timing={time-offset=0, time-period=0.02}, transmission-mode-true-timing=cyclic-timing={time-offset=0, time-period=0.02}, unused-bit-pattern=0
            signal Checksum_0B3_oIBS_Status_02_oATOM_CANFD_Matrix_CH_V600_202502: start 7, 8 bit, big-endian, i-signal-type=PRIMITIVE, init-value=0, base-type=uint8, compu-method=CM_Checksum_0B3, data-constr=DC_Checksum_0B3, transfer-property=PENDING, to VCU  # Checksum signal for frame
            signal MessageCounter_0B3_oIBS_Status_02_oATOM_CANFD_Matrix_CH_V600_202502: start 11, 4 bit, big-endian, i-signal-type=PRIMITIVE, init-value=0, base-type=uint8, compu-method=CM_MessageCounter_0B3, data-constr=DC_MessageCounter_0B3, transfer-property=PENDING, to VCU  # Message counter signal for frame
            signal IBS_EPBworkingSts_oIBS_Status_02_oATOM_CANFD_Matrix_CH_V600_202502: start 19, 3 bit, big-endian, i-signal-type=PRIMITIVE, init-value=0, base-type=uint8, compu-method=CM_IBS_EPBworkingSts, data-constr=DC_IBS_EPBworkingSts, transfer-property=PENDING, to VCU  # EN: EPB Status
            signal IBS_BrakeLightRequest_oIBS_Status_02_oATOM_CANFD_Matrix_CH_V600_202502: start 21, 2 bit, big-endian, i-signal-type=PRIMITIVE, init-value=0, base-type=uint8, compu-method=CM_IBS_BrakeLightRequest, data-constr=DC_IBS_BrakeLightRequest, transfer-property=PENDING, to VCU  # EN: IBS request to turn on the stop lamp when the active braking is triggered
            signal IBS_EPBFailureLamp_oIBS_Status_02_oATOM_CANFD_Matrix_CH_V600_202502: start 23, 2 bit, big-endian, i-signal-type=PRIMITIVE, init-value=0, base-type=uint8, compu-method=CM_IBS_EPBFailureLamp, data-constr=DC_IBS_EPBFailureLamp, transfer-property=PENDING, to VCU  # EN: EPB Failure Lamp
            signal IBS_HHCAvailable_oIBS_Status_02_oATOM_CANFD_Matrix_CH_V600_202502: start 24, 1 bit, big-endian, i-signal-type=PRIMITIVE, init-value=0, base-type=boolean, compu-method=CM_IBS_HHCAvailable, data-constr=DC_IBS_HHCAvailable, transfer-property=PENDING, to VCU  # EN: HHC Function Available
            signal IBS_HHCActive_oIBS_Status_02_oATOM_CANFD_Matrix_CH_V600_202502: start 25, 1 bit, big-endian, i-signal-type=PRIMITIVE, init-value=0, base-type=boolean, compu-method=CM_IBS_HHCActive, data-constr=DC_IBS_HHCActive, transfer-property=PENDING, to VCU  # EN: HHC Function Active
            signal IBS_AEBActive_oIBS_Status_02_oATOM_CANFD_Matrix_CH_V600_202502: start 26, 1 bit, big-endian, i-signal-type=PRIMITIVE, init-value=0, base-type=boolean, compu-method=CM_IBS_AEBActive, data-constr=DC_IBS_AEBActive, transfer-property=PENDING, to VCU  # EN: AEB Function Active
            signal IBS_HDCAvailable_oIBS_Status_02_oATOM_CANFD_Matrix_CH_V600_202502: start 27, 1 bit, big-endian, i-signal-type=PRIMITIVE, init-value=0, base-type=boolean, compu-method=CM_IBS_HDCAvailable, data-constr=DC_IBS_HDCAvailable, transfer-property=PENDING, to VCU  # EN: HDC Function Available
            signal IBS_VDCActive_oIBS_Status_02_oATOM_CANFD_Matrix_CH_V600_202502: start 30, 1 bit, big-endian, i-signal-type=PRIMITIVE, init-value=0, base-type=boolean, compu-method=CM_IBS_VDCActive, data-constr=DC_IBS_VDCActive, transfer-property=PENDING, to VCU  # EN: indicates VDC intervention active, ESP will detect other vehicle slip/slide situations, and brake individual wheels to counteract the vehicle slid
            signal IBS_TCSActive_oIBS_Status_02_oATOM_CANFD_Matrix_CH_V600_202502: start 31, 1 bit, big-endian, i-signal-type=PRIMITIVE, init-value=0, base-type=boolean, compu-method=CM_IBS_TCSActive, data-constr=DC_IBS_TCSActive, transfer-property=PENDING, to VCU  # EN: Tindicates TCS intervention active,TCS will detect spinning wheels and request torque reduction/limitation
            signal IBS_AWBAvailable_oIBS_Status_02_oATOM_CANFD_Matrix_CH_V600_202502: start 32, 1 bit, big-endian, i-signal-type=PRIMITIVE, init-value=0, base-type=boolean, compu-method=CM_IBS_AWBAvailable, data-constr=DC_IBS_AWBAvailable, transfer-property=PENDING, to VCU  # AWB is available or not
            signal IBS_AEBAvailable_oIBS_Status_02_oATOM_CANFD_Matrix_CH_V600_202502: start 33, 1 bit, big-endian, i-signal-type=PRIMITIVE, init-value=0, base-type=boolean, compu-method=CM_IBS_AEBAvailable, data-constr=DC_IBS_AEBAvailable, transfer-property=PENDING, to VCU  # Information indicating whether braking control for AEB is possible or not
            signal IBS_EPBFunctionLamp_oIBS_Status_02_oATOM_CANFD_Matrix_CH_V600_202502: start 35, 2 bit, big-endian, i-signal-type=PRIMITIVE, init-value=0, base-type=uint8, compu-method=CM_IBS_EPBFunctionLamp, data-constr=DC_IBS_EPBFunctionLamp, transfer-property=PENDING, to VCU  # EN: EPB Function Lamp
            signal IBS_AWBActive_oIBS_Status_02_oATOM_CANFD_Matrix_CH_V600_202502: start 36, 1 bit, big-endian, i-signal-type=PRIMITIVE, init-value=0, base-type=boolean, compu-method=CM_IBS_AWBActive, data-constr=DC_IBS_AWBActive, transfer-property=PENDING, to VCU  # AWB is active or not
            signal IBS_HazWarnReq_oIBS_Status_02_oATOM_CANFD_Matrix_CH_V600_202502: start 38, 2 bit, big-endian, i-signal-type=PRIMITIVE, init-value=0, base-type=uint8, compu-method=CM_IBS_HazWarnReq, data-constr=DC_IBS_HazWarnReq, transfer-property=PENDING, to VCU  # EN: Hazard warning Lamps
            signal IBS_AVHAvailable_oIBS_Status_02_oATOM_CANFD_Matrix_CH_V600_202502: start 39, 1 bit, big-endian, i-signal-type=PRIMITIVE, init-value=0, base-type=boolean, compu-method=CM_IBS_AVHAvailable, data-constr=DC_IBS_AVHAvailable, transfer-property=PENDING, to VCU  # EN: AVH Function Available
            signal IBS_EPBControllerSts_oIBS_Status_02_oATOM_CANFD_Matrix_CH_V600_202502: start 47, 2 bit, big-endian, i-signal-type=PRIMITIVE, init-value=0, base-type=uint8, compu-method=CM_IBS_EPBControllerSts, data-constr=DC_IBS_EPBControllerSts, transfer-property=PENDING, to VCU  # Primary controller switchover status of an EPB
            mapping SG_IBS_Status_02_SigGroup: i-signal-group=SG_IBS_Status_02_SigGroup_oIBS_Status_02_oATOM_CANFD_Matrix_CH_V600_202502, transfer-property=PENDING
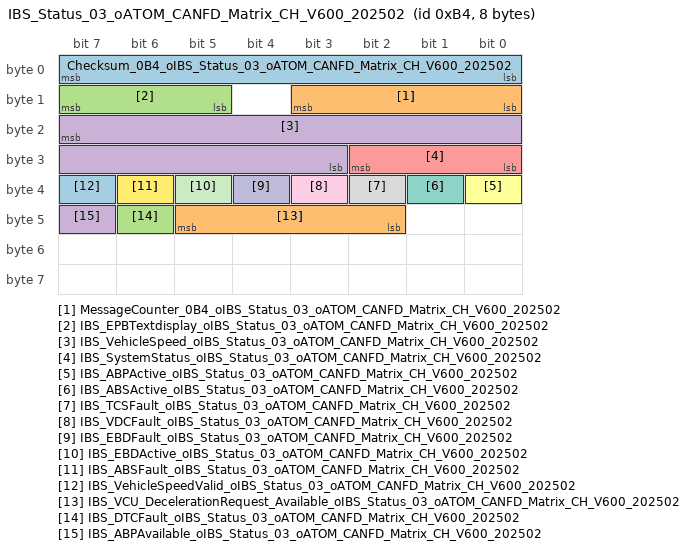
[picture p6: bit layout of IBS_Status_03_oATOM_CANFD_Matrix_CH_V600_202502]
        frame IBS_Status_03_oATOM_CANFD_Matrix_CH_V600_202502: id 0xB4, to VCU, frame-length=8, can-addressing-mode=STANDARD, can-frame-rx-behavior=ANY, can-frame-tx-behavior=CAN-FD
          pdu IBS_Status_03_oATOM_CANFD_Matrix_CH_V600_202502: length=8, minimum-delay=0, transmission-mode-false-timing=cyclic-timing={time-offset=0, time-period=0.02}, transmission-mode-true-timing=cyclic-timing={time-offset=0, time-period=0.02}, unused-bit-pattern=0
            signal Checksum_0B4_oIBS_Status_03_oATOM_CANFD_Matrix_CH_V600_202502: start 7, 8 bit, big-endian, i-signal-type=PRIMITIVE, init-value=0, base-type=uint8, compu-method=CM_Checksum_0B4, data-constr=DC_Checksum_0B4, transfer-property=PENDING, to VCU  # Checksum signal for frame
            signal MessageCounter_0B4_oIBS_Status_03_oATOM_CANFD_Matrix_CH_V600_202502: start 11, 4 bit, big-endian, i-signal-type=PRIMITIVE, init-value=0, base-type=uint8, compu-method=CM_MessageCounter_0B4, data-constr=DC_MessageCounter_0B4, transfer-property=PENDING, to VCU  # Message counter signal for frame
            signal IBS_EPBTextdisplay_oIBS_Status_03_oATOM_CANFD_Matrix_CH_V600_202502: start 15, 3 bit, big-endian, i-signal-type=PRIMITIVE, init-value=0, base-type=uint8, compu-method=CM_IBS_EPBTextdisplay, data-constr=DC_IBS_EPBTextdisplay, transfer-property=PENDING, to VCU  # EN: EPB Text display
            signal IBS_VehicleSpeed_oIBS_Status_03_oATOM_CANFD_Matrix_CH_V600_202502: start 23, 13 bit, big-endian, i-signal-type=PRIMITIVE, init-value=0, base-type=uint16, compu-method=CM_IBS_VehicleSpeed, data-constr=DC_IBS_VehicleSpeed, unit=U_kmYh, transfer-property=PENDING, to VCU  # EN: Vehicle speed
            signal IBS_SystemStatus_oIBS_Status_03_oATOM_CANFD_Matrix_CH_V600_202502: start 26, 3 bit, big-endian, i-signal-type=PRIMITIVE, init-value=0, base-type=uint8, compu-method=CM_IBS_SystemStatus, data-constr=DC_IBS_SystemStatus, transfer-property=PENDING, to VCU  # IBS System Status
            signal IBS_ABPActive_oIBS_Status_03_oATOM_CANFD_Matrix_CH_V600_202502: start 32, 1 bit, big-endian, i-signal-type=PRIMITIVE, init-value=0, base-type=boolean, compu-method=CM_IBS_ABPActive, data-constr=DC_IBS_ABPActive, transfer-property=PENDING, to VCU  # Prefill(ABP) is active or not.
            signal IBS_ABSActive_oIBS_Status_03_oATOM_CANFD_Matrix_CH_V600_202502: start 33, 1 bit, big-endian, i-signal-type=PRIMITIVE, init-value=0, base-type=boolean, compu-method=CM_IBS_ABSActive, data-constr=DC_IBS_ABSActive, transfer-property=PENDING, to VCU  # indicates ABS intervention active.
            signal IBS_TCSFault_oIBS_Status_03_oATOM_CANFD_Matrix_CH_V600_202502: start 34, 1 bit, big-endian, i-signal-type=PRIMITIVE, init-value=0, base-type=boolean, compu-method=CM_IBS_TCSFault, data-constr=DC_IBS_TCSFault, transfer-property=PENDING, to VCU  # EN: TCS status valid
            signal IBS_VDCFault_oIBS_Status_03_oATOM_CANFD_Matrix_CH_V600_202502: start 35, 1 bit, big-endian, i-signal-type=PRIMITIVE, init-value=0, base-type=boolean, compu-method=CM_IBS_VDCFault, data-constr=DC_IBS_VDCFault, transfer-property=PENDING, to VCU  # EN: VDC status valid
            signal IBS_EBDFault_oIBS_Status_03_oATOM_CANFD_Matrix_CH_V600_202502: start 36, 1 bit, big-endian, i-signal-type=PRIMITIVE, init-value=0, base-type=boolean, compu-method=CM_IBS_EBDFault, data-constr=DC_IBS_EBDFault, transfer-property=PENDING, to VCU  # ABS system has detected a heavy fault, which does not even allow a reliable electronic brake distribution and is therefore completely shut down.
            signal IBS_EBDActive_oIBS_Status_03_oATOM_CANFD_Matrix_CH_V600_202502: start 37, 1 bit, big-endian, i-signal-type=PRIMITIVE, init-value=0, base-type=boolean, compu-method=CM_IBS_EBDActive, data-constr=DC_IBS_EBDActive, transfer-property=PENDING, to VCU  # EBD Active Status
            signal IBS_ABSFault_oIBS_Status_03_oATOM_CANFD_Matrix_CH_V600_202502: start 38, 1 bit, big-endian, i-signal-type=PRIMITIVE, init-value=0, base-type=boolean, compu-method=CM_IBS_ABSFault, data-constr=DC_IBS_ABSFault, transfer-property=PENDING, to VCU  # ABS system has detected a failure which does not allow a reliable ABS regulation and is therefore switched off.
            signal IBS_VehicleSpeedValid_oIBS_Status_03_oATOM_CANFD_Matrix_CH_V600_202502: start 39, 1 bit, big-endian, i-signal-type=PRIMITIVE, init-value=0, base-type=boolean, compu-method=CM_IBS_VehicleSpeedValid, data-constr=DC_IBS_VehicleSpeedValid, transfer-property=PENDING, to VCU  # EN: Vehicle speed valid
            signal IBS_VCU_DecelerationRequest_Available_oIBS_Status_03_oATOM_CANFD_Matrix_CH_V600_202502: start 45, 4 bit, big-endian, i-signal-type=PRIMITIVE, init-value=0, base-type=uint8, compu-method=CM_IBS_VCU_DecelerationRequest_Available, data-constr=DC_IBS_VCU_DecelerationRequest_Available, transfer-property=PENDING, to VCU  # Indicates whether the VCU-related deceleration request function is available
            signal IBS_DTCFault_oIBS_Status_03_oATOM_CANFD_Matrix_CH_V600_202502: start 46, 1 bit, big-endian, i-signal-type=PRIMITIVE, init-value=0, base-type=boolean, compu-method=CM_IBS_DTCFault, data-constr=DC_IBS_DTCFault, transfer-property=PENDING, to VCU  # Drag Torque Control fault
            signal IBS_ABPAvailable_oIBS_Status_03_oATOM_CANFD_Matrix_CH_V600_202502: start 47, 1 bit, big-endian, i-signal-type=PRIMITIVE, init-value=0, base-type=boolean, compu-method=CM_IBS_ABPAvailable, data-constr=DC_IBS_ABPAvailable, transfer-property=PENDING, to VCU  # Prefill(ABP) is available or not.
            mapping SG_IBS_Status_03_SigGroup: i-signal-group=SG_IBS_Status_03_SigGroup_oIBS_Status_03_oATOM_CANFD_Matrix_CH_V600_202502, transfer-property=PENDING
        frame IBS_Status_04_oATOM_CANFD_Matrix_CH_V600_202502: id 0xBA, to VCU, frame-length=8, can-addressing-mode=STANDARD, can-frame-rx-behavior=ANY, can-frame-tx-behavior=CAN-FD
          pdu IBS_Status_04_oATOM_CANFD_Matrix_CH_V600_202502: length=8, minimum-delay=0, transmission-mode-false-timing=cyclic-timing={time-offset=0, time-period=0.02}, transmission-mode-true-timing=cyclic-timing={time-offset=0, time-period=0.02}, unused-bit-pattern=0
            signal Checksum_0BA_oIBS_Status_04_oATOM_CANFD_Matrix_CH_V600_202502: start 7, 8 bit, big-endian, i-signal-type=PRIMITIVE, init-value=0, base-type=uint8, compu-method=CM_Checksum_0BA, data-constr=DC_Checksum_0BA, transfer-property=PENDING, to VCU  # Checksum signal for frame
            signal MessageCounter_0BA_oIBS_Status_04_oATOM_CANFD_Matrix_CH_V600_202502: start 11, 4 bit, big-endian, i-signal-type=PRIMITIVE, init-value=0, base-type=uint8, compu-method=CM_MessageCounter_0BA, data-constr=DC_MessageCounter_0BA, transfer-property=PENDING, to VCU  # Message counter signal for frame
            signal IBS_DTCActive_oIBS_Status_04_oATOM_CANFD_Matrix_CH_V600_202502: start 21, 1 bit, big-endian, i-signal-type=PRIMITIVE, init-value=0, base-type=boolean, compu-method=CM_IBS_DTCActive, data-constr=DC_IBS_DTCActive, transfer-property=PENDING, to VCU  # Drag Torque Control
            signal IBS_CDPAvailable_oIBS_Status_04_oATOM_CANFD_Matrix_CH_V600_202502: start 22, 1 bit, big-endian, i-signal-type=PRIMITIVE, init-value=0, base-type=boolean, compu-method=CM_IBS_CDPAvailable, data-constr=DC_IBS_CDPAvailable, transfer-property=PENDING, to VCU  # EN: CDP Function Available
            signal IBS_CDPActive_oIBS_Status_04_oATOM_CANFD_Matrix_CH_V600_202502: start 23, 1 bit, big-endian, i-signal-type=PRIMITIVE, init-value=0, base-type=boolean, compu-method=CM_IBS_CDPActive, data-constr=DC_IBS_CDPActive, transfer-property=PENDING, to VCU  # Indicate CDP Control Active
            mapping SG_IBS_Status_04_SigGroup: i-signal-group=SG_IBS_Status_04_SigGroup_oIBS_Status_04_oATOM_CANFD_Matrix_CH_V600_202502, transfer-property=PENDING
        frame IBS_Status_06_oATOM_CANFD_Matrix_CH_V600_202502: id 0xBC, to VCU, frame-length=8, can-addressing-mode=STANDARD, can-frame-rx-behavior=ANY, can-frame-tx-behavior=CAN-FD
          pdu IBS_Status_06_oATOM_CANFD_Matrix_CH_V600_202502: length=8, minimum-delay=0, transmission-mode-false-timing=cyclic-timing={time-offset=0, time-period=0.02}, transmission-mode-true-timing=cyclic-timing={time-offset=0, time-period=0.02}, unused-bit-pattern=0
            signal Checksum_0BC_oIBS_Status_06_oATOM_CANFD_Matrix_CH_V600_202502: start 7, 8 bit, big-endian, i-signal-type=PRIMITIVE, init-value=0, base-type=uint8, compu-method=CM_Checksum_0BC, data-constr=DC_Checksum_0BC, transfer-property=PENDING, to VCU  # Checksum signal for frame
            signal MessageCounter_0BC_oIBS_Status_06_oATOM_CANFD_Matrix_CH_V600_202502: start 11, 4 bit, big-endian, i-signal-type=PRIMITIVE, init-value=0, base-type=uint8, compu-method=CM_MessageCounter_0BC, data-constr=DC_MessageCounter_0BC, transfer-property=PENDING, to VCU  # Message counter signal for frame
            signal IBS_FactoryMode_oIBS_Status_06_oATOM_CANFD_Matrix_CH_V600_202502: start 40, 1 bit, big-endian, i-signal-type=PRIMITIVE, init-value=0, base-type=boolean, compu-method=CM_IBS_FactoryMode, data-constr=DC_IBS_FactoryMode, transfer-property=PENDING, to VCU  # Factory Mode Status
            signal IBS_RollerbenchMode_oIBS_Status_06_oATOM_CANFD_Matrix_CH_V600_202502: start 41, 1 bit, big-endian, i-signal-type=PRIMITIVE, init-value=0, base-type=boolean, compu-method=CM_IBS_RollerbenchMode, data-constr=DC_IBS_RollerbenchMode, transfer-property=PENDING, to VCU  # Rollerbench Mode Status
            signal IBS_MaintenaceMode_oIBS_Status_06_oATOM_CANFD_Matrix_CH_V600_202502: start 42, 1 bit, big-endian, i-signal-type=PRIMITIVE, init-value=0, base-type=boolean, compu-method=CM_IBS_MaintenaceMode, data-constr=DC_IBS_MaintenaceMode, transfer-property=PENDING, to VCU  # Maintenace Mode Status
            signal IBS_RWUAvailable_oIBS_Status_06_oATOM_CANFD_Matrix_CH_V600_202502: start 43, 1 bit, big-endian, i-signal-type=PRIMITIVE, init-value=0, base-type=boolean, compu-method=CM_IBS_RWUAvailable, data-constr=DC_IBS_RWUAvailable, transfer-property=PENDING, to VCU  # EN: RWU Function Available
            signal IBS_RWUActive_oIBS_Status_06_oATOM_CANFD_Matrix_CH_V600_202502: start 44, 1 bit, big-endian, i-signal-type=PRIMITIVE, init-value=0, base-type=boolean, compu-method=CM_IBS_RWUActive, data-constr=DC_IBS_RWUActive, transfer-property=PENDING, to VCU  # Indicate RWU Control Active
            signal IBS_ESCOffSts_oIBS_Status_06_oATOM_CANFD_Matrix_CH_V600_202502: start 45, 1 bit, big-endian, i-signal-type=PRIMITIVE, init-value=1, base-type=boolean, compu-method=CM_IBS_ESCOffSts, data-constr=DC_IBS_ESCOffSts, transfer-property=PENDING, to VCU  # ESC OFF Status
            signal IBS_HBAActive_oIBS_Status_06_oATOM_CANFD_Matrix_CH_V600_202502: start 46, 1 bit, big-endian, i-signal-type=PRIMITIVE, init-value=0, base-type=boolean, compu-method=CM_IBS_HBAActive, data-constr=DC_IBS_HBAActive, transfer-property=PENDING, to VCU  # HBA Active Status
            signal IBS_BrakeFluidWarning_oIBS_Status_06_oATOM_CANFD_Matrix_CH_V600_202502: start 49, 2 bit, big-endian, i-signal-type=PRIMITIVE, init-value=0, base-type=uint8, compu-method=CM_IBS_BrakeFluidWarning, data-constr=DC_IBS_BrakeFluidWarning, transfer-property=PENDING, to VCU  # Brake Fluid Warning
            signal IBS_HDCSts_oIBS_Status_06_oATOM_CANFD_Matrix_CH_V600_202502: start 51, 2 bit, big-endian, i-signal-type=PRIMITIVE, init-value=0, base-type=uint8, compu-method=CM_IBS_HDCSts, data-constr=DC_IBS_HDCSts, transfer-property=PENDING, to VCU  # Indicates HDC in Active or Off
            signal IBS_ESClampdisplay_oIBS_Status_06_oATOM_CANFD_Matrix_CH_V600_202502: start 53, 2 bit, big-endian, i-signal-type=PRIMITIVE, init-value=0, base-type=uint8, compu-method=CM_IBS_ESClampdisplay, data-constr=DC_IBS_ESClampdisplay, transfer-property=PENDING, to VCU  # ESC function lamp display for IVI
            signal IBS_AVHSts_oIBS_Status_06_oATOM_CANFD_Matrix_CH_V600_202502: start 55, 2 bit, big-endian, i-signal-type=PRIMITIVE, init-value=0, base-type=uint8, compu-method=CM_IBS_AVHSts, data-constr=DC_IBS_AVHSts, transfer-property=PENDING, to VCU  # Indicates AVH in Active or Standby or Off
            signal IBS_TireWarnFrntRi_oIBS_Status_06_oATOM_CANFD_Matrix_CH_V600_202502: start 56, 1 bit, big-endian, i-signal-type=PRIMITIVE, init-value=0, base-type=boolean, compu-method=CM_IBS_TireWarnFrntRi, data-constr=DC_IBS_TireWarnFrntRi, transfer-property=PENDING, to VCU  # Alarm status at right rear
            signal IBS_TireWarnFrntLe_oIBS_Status_06_oATOM_CANFD_Matrix_CH_V600_202502: start 57, 1 bit, big-endian, i-signal-type=PRIMITIVE, init-value=0, base-type=boolean, compu-method=CM_IBS_TireWarnFrntLe, data-constr=DC_IBS_TireWarnFrntLe, transfer-property=PENDING, to VCU  # Alarm status at left front
            signal IBS_TireWarnReRi_oIBS_Status_06_oATOM_CANFD_Matrix_CH_V600_202502: start 58, 1 bit, big-endian, i-signal-type=PRIMITIVE, init-value=0, base-type=boolean, compu-method=CM_IBS_TireWarnReRi, data-constr=DC_IBS_TireWarnReRi, transfer-property=PENDING, to VCU  # Alarm status at right rear
            signal IBS_TireWarnReLe_oIBS_Status_06_oATOM_CANFD_Matrix_CH_V600_202502: start 59, 1 bit, big-endian, i-signal-type=PRIMITIVE, init-value=0, base-type=boolean, compu-method=CM_IBS_TireWarnReLe, data-constr=DC_IBS_TireWarnReLe, transfer-property=PENDING, to VCU  # Alarm status at left rear
            signal IBS_TPMS_ResetSts_oIBS_Status_06_oATOM_CANFD_Matrix_CH_V600_202502: start 60, 1 bit, big-endian, i-signal-type=PRIMITIVE, init-value=0, base-type=boolean, compu-method=CM_IBS_TPMS_ResetSts, data-constr=DC_IBS_TPMS_ResetSts, transfer-property=PENDING, to VCU  # Reset TPMS status
            signal IBS_TireMonSysSts_oIBS_Status_06_oATOM_CANFD_Matrix_CH_V600_202502: start 61, 1 bit, big-endian, i-signal-type=PRIMITIVE, init-value=1, base-type=boolean, compu-method=CM_IBS_TireMonSysSts, data-constr=DC_IBS_TireMonSysSts, transfer-property=PENDING, to VCU  # TMPS system status
            signal IBS_EPBFailureStatus_oIBS_Status_06_oATOM_CANFD_Matrix_CH_V600_202502: start 63, 2 bit, big-endian, i-signal-type=PRIMITIVE, init-value=0, base-type=uint8, compu-method=CM_IBS_EPBFailureStatus, data-constr=DC_IBS_EPBFailureStatus, transfer-property=PENDING, to VCU  # EPB failure status
            mapping SG_IBS_Status_06_SigGroup: i-signal-group=SG_IBS_Status_06_SigGroup_oIBS_Status_06_oATOM_CANFD_Matrix_CH_V600_202502, transfer-property=PENDING
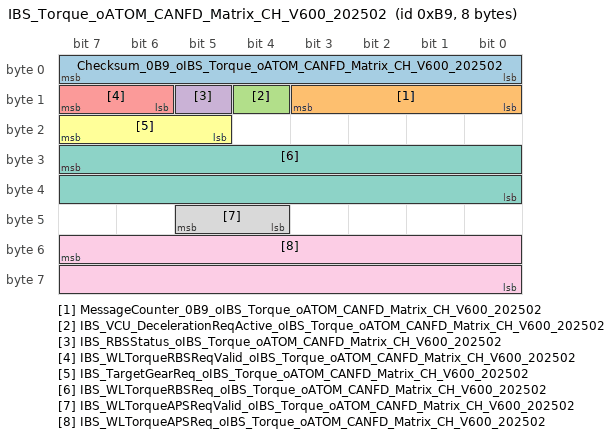
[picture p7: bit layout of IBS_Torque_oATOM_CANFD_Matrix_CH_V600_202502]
        frame IBS_Torque_oATOM_CANFD_Matrix_CH_V600_202502: id 0xB9, to VCU, frame-length=8, can-addressing-mode=STANDARD, can-frame-rx-behavior=ANY, can-frame-tx-behavior=CAN-FD
          pdu IBS_Torque_oATOM_CANFD_Matrix_CH_V600_202502: length=8, minimum-delay=0, transmission-mode-false-timing=cyclic-timing={time-offset=0, time-period=0.02}, transmission-mode-true-timing=cyclic-timing={time-offset=0, time-period=0.02}, unused-bit-pattern=0
            signal Checksum_0B9_oIBS_Torque_oATOM_CANFD_Matrix_CH_V600_202502: start 7, 8 bit, big-endian, i-signal-type=PRIMITIVE, init-value=0, base-type=uint8, compu-method=CM_Checksum_0B9, data-constr=DC_Checksum_0B9, transfer-property=PENDING, to VCU  # Checksum signal for frame
            signal MessageCounter_0B9_oIBS_Torque_oATOM_CANFD_Matrix_CH_V600_202502: start 11, 4 bit, big-endian, i-signal-type=PRIMITIVE, init-value=0, base-type=uint8, compu-method=CM_MessageCounter_0B9, data-constr=DC_MessageCounter_0B9, transfer-property=PENDING, to VCU  # Message counter signal for frame
            signal IBS_VCU_DecelerationReqActive_oIBS_Torque_oATOM_CANFD_Matrix_CH_V600_202502: start 12, 1 bit, big-endian, i-signal-type=PRIMITIVE, init-value=0, base-type=boolean, compu-method=CM_IBS_VCU_DecelerationReqActive, data-constr=DC_IBS_VCU_DecelerationReqActive, transfer-property=PENDING, to VCU  # IBS activation signal in response to VCU deceleration request
            signal IBS_RBSStatus_oIBS_Torque_oATOM_CANFD_Matrix_CH_V600_202502: start 13, 1 bit, big-endian, i-signal-type=PRIMITIVE, init-value=0, base-type=boolean, compu-method=CM_IBS_RBSStatus, data-constr=DC_IBS_RBSStatus, transfer-property=PENDING, to VCU  # EN: Energy recovery status
            signal IBS_WLTorqueRBSReqValid_oIBS_Torque_oATOM_CANFD_Matrix_CH_V600_202502: start 15, 2 bit, big-endian, i-signal-type=PRIMITIVE, init-value=0, base-type=uint8, compu-method=CM_IBS_WLTorqueRBSReqValid, data-constr=DC_IBS_WLTorqueRBSReqValid, transfer-property=PENDING, to VCU  # EN: CRBS wheel torque request valid
            signal IBS_TargetGearReq_oIBS_Torque_oATOM_CANFD_Matrix_CH_V600_202502: start 23, 3 bit, big-endian, i-signal-type=PRIMITIVE, init-value=0, base-type=uint8, compu-method=CM_IBS_TargetGearReq, data-constr=DC_IBS_TargetGearReq, transfer-property=PENDING, to VCU  # IBS fotwarded APS Gear request
            signal IBS_WLTorqueRBSReq_oIBS_Torque_oATOM_CANFD_Matrix_CH_V600_202502: start 31, 16 bit, big-endian, i-signal-type=PRIMITIVE, init-value=0, base-type=uint16, compu-method=CM_IBS_WLTorqueRBSReq, data-constr=DC_IBS_WLTorqueRBSReq, unit=U_Nm, transfer-property=PENDING, to VCU  # EN: CRBS wheel torque request
            signal IBS_WLTorqueAPSReqValid_oIBS_Torque_oATOM_CANFD_Matrix_CH_V600_202502: start 45, 2 bit, big-endian, i-signal-type=PRIMITIVE, init-value=0, base-type=uint8, compu-method=CM_IBS_WLTorqueAPSReqValid, data-constr=DC_IBS_WLTorqueAPSReqValid, transfer-property=PENDING, to VCU  # APS wheel torque request valid
            signal IBS_WLTorqueAPSReq_oIBS_Torque_oATOM_CANFD_Matrix_CH_V600_202502: start 55, 16 bit, big-endian, i-signal-type=PRIMITIVE, init-value=0, base-type=uint16, compu-method=CM_IBS_WLTorqueAPSReq, data-constr=DC_IBS_WLTorqueAPSReq, unit=U_Nm, transfer-property=PENDING, to VCU  # APS wheel torque request
            mapping SG_IBS_Torque_SigGroup: i-signal-group=SG_IBS_Torque_SigGroup_oIBS_Torque_oATOM_CANFD_Matrix_CH_V600_202502, transfer-property=PENDING
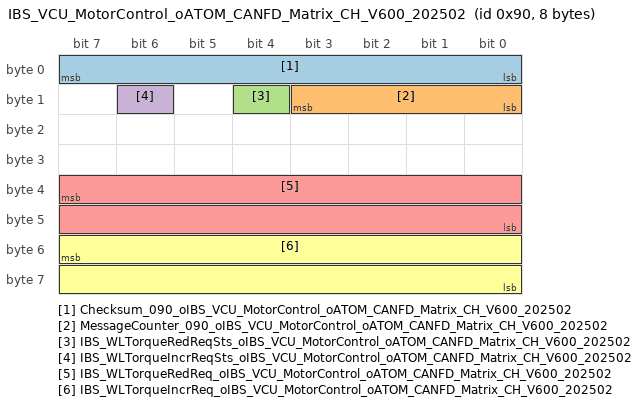
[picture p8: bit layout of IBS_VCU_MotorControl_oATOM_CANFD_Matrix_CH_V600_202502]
        frame IBS_VCU_MotorControl_oATOM_CANFD_Matrix_CH_V600_202502: id 0x90, to VCU, frame-length=8, can-addressing-mode=STANDARD, can-frame-rx-behavior=ANY, can-frame-tx-behavior=CAN-FD
          pdu IBS_VCU_MotorControl_oATOM_CANFD_Matrix_CH_V600_202502: length=8, minimum-delay=0, transmission-mode-false-timing=cyclic-timing={time-offset=0, time-period=0.01}, transmission-mode-true-timing=cyclic-timing={time-offset=0, time-period=0.01}, unused-bit-pattern=0
            signal Checksum_090_oIBS_VCU_MotorControl_oATOM_CANFD_Matrix_CH_V600_202502: start 7, 8 bit, big-endian, i-signal-type=PRIMITIVE, init-value=0, base-type=uint8, compu-method=CM_Checksum_090, data-constr=DC_Checksum_090, transfer-property=PENDING, to VCU  # Checksum signal for frame
            signal MessageCounter_090_oIBS_VCU_MotorControl_oATOM_CANFD_Matrix_CH_V600_202502: start 11, 4 bit, big-endian, i-signal-type=PRIMITIVE, init-value=0, base-type=uint8, compu-method=CM_MessageCounter_090, data-constr=DC_MessageCounter_090, transfer-property=PENDING, to VCU  # Message counter signal for frame
            signal IBS_WLTorqueRedReqSts_oIBS_VCU_MotorControl_oATOM_CANFD_Matrix_CH_V600_202502: start 12, 1 bit, big-endian, i-signal-type=PRIMITIVE, init-value=0, base-type=boolean, compu-method=CM_IBS_WLTorqueRedReqSts, data-constr=DC_IBS_WLTorqueRedReqSts, transfer-property=PENDING, to VCU  # Wheel torque reduction request status.
            signal IBS_WLTorqueIncrReqSts_oIBS_VCU_MotorControl_oATOM_CANFD_Matrix_CH_V600_202502: start 14, 1 bit, big-endian, i-signal-type=PRIMITIVE, init-value=0, base-type=boolean, compu-method=CM_IBS_WLTorqueIncrReqSts, data-constr=DC_IBS_WLTorqueIncrReqSts, transfer-property=PENDING, to VCU  # Wheel torque increase request status.
            signal IBS_WLTorqueRedReq_oIBS_VCU_MotorControl_oATOM_CANFD_Matrix_CH_V600_202502: start 39, 16 bit, big-endian, i-signal-type=PRIMITIVE, init-value=0, base-type=uint16, compu-method=CM_IBS_WLTorqueRedReq, data-constr=DC_IBS_WLTorqueRedReq, unit=U_Nm, transfer-property=PENDING, to VCU  # Wheel torque reduction request.
            signal IBS_WLTorqueIncrReq_oIBS_VCU_MotorControl_oATOM_CANFD_Matrix_CH_V600_202502: start 55, 16 bit, big-endian, i-signal-type=PRIMITIVE, init-value=0, base-type=uint16, compu-method=CM_IBS_WLTorqueIncrReq, data-constr=DC_IBS_WLTorqueIncrReq, unit=U_Nm, transfer-property=PENDING, to VCU  # Wheel torque increase request
            mapping SG_IBS_VCU_MotorControl_SigGroup: i-signal-group=SG_IBS_VCU_MotorControl_SigGroup_oIBS_VCU_MotorControl_oATOM_CANFD_Matrix_CH_V600_202502, transfer-property=PENDING
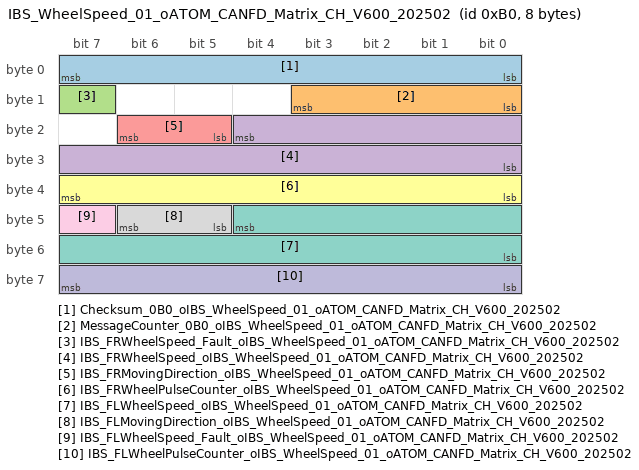
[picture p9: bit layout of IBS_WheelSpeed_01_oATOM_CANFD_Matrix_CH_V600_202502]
        frame IBS_WheelSpeed_01_oATOM_CANFD_Matrix_CH_V600_202502: id 0xB0, to VCU, frame-length=8, can-addressing-mode=STANDARD, can-frame-rx-behavior=ANY, can-frame-tx-behavior=CAN-FD
          pdu IBS_WheelSpeed_01_oATOM_CANFD_Matrix_CH_V600_202502: length=8, minimum-delay=0, transmission-mode-false-timing=cyclic-timing={time-offset=0, time-period=0.02}, transmission-mode-true-timing=cyclic-timing={time-offset=0, time-period=0.02}, unused-bit-pattern=0
            signal Checksum_0B0_oIBS_WheelSpeed_01_oATOM_CANFD_Matrix_CH_V600_202502: start 7, 8 bit, big-endian, i-signal-type=PRIMITIVE, init-value=0, base-type=uint8, compu-method=CM_Checksum_0B0, data-constr=DC_Checksum_0B0, transfer-property=PENDING, to VCU  # Checksum signal for frame
            signal MessageCounter_0B0_oIBS_WheelSpeed_01_oATOM_CANFD_Matrix_CH_V600_202502: start 11, 4 bit, big-endian, i-signal-type=PRIMITIVE, init-value=0, base-type=uint8, compu-method=CM_MessageCounter_0B0, data-constr=DC_MessageCounter_0B0, transfer-property=PENDING, to VCU  # Message counter signal for frame
            signal IBS_FRWheelSpeed_Fault_oIBS_WheelSpeed_01_oATOM_CANFD_Matrix_CH_V600_202502: start 15, 1 bit, big-endian, i-signal-type=PRIMITIVE, init-value=0, base-type=boolean, compu-method=CM_IBS_FRWheelSpeed_Fault, data-constr=DC_IBS_FRWheelSpeed_Fault, transfer-property=PENDING, to VCU  # EN: Front right wheel speed signal valid
            signal IBS_FRWheelSpeed_oIBS_WheelSpeed_01_oATOM_CANFD_Matrix_CH_V600_202502: start 20, 13 bit, big-endian, i-signal-type=PRIMITIVE, init-value=0, base-type=uint16, compu-method=CM_IBS_FRWheelSpeed, data-constr=DC_IBS_FRWheelSpeed, unit=U_kmYh, transfer-property=PENDING, to VCU  # EN: Front right wheel speed
            signal IBS_FRMovingDirection_oIBS_WheelSpeed_01_oATOM_CANFD_Matrix_CH_V600_202502: start 22, 2 bit, big-endian, i-signal-type=PRIMITIVE, init-value=0, base-type=uint8, compu-method=CM_IBS_FRMovingDirection, data-constr=DC_IBS_FRMovingDirection, transfer-property=PENDING, to VCU  # EN: Front right wheel direction
            signal IBS_FRWheelPulseCounter_oIBS_WheelSpeed_01_oATOM_CANFD_Matrix_CH_V600_202502: start 39, 8 bit, big-endian, i-signal-type=PRIMITIVE, init-value=0, base-type=uint8, compu-method=CM_IBS_FRWheelPulseCounter, data-constr=DC_IBS_FRWheelPulseCounter, transfer-property=PENDING, to VCU  # EN: Front right wheel speed pulse
            signal IBS_FLWheelSpeed_oIBS_WheelSpeed_01_oATOM_CANFD_Matrix_CH_V600_202502: start 44, 13 bit, big-endian, i-signal-type=PRIMITIVE, init-value=0, base-type=uint16, compu-method=CM_IBS_FLWheelSpeed, data-constr=DC_IBS_FLWheelSpeed, unit=U_kmYh, transfer-property=PENDING, to VCU  # EN: Front left wheel speed
            signal IBS_FLMovingDirection_oIBS_WheelSpeed_01_oATOM_CANFD_Matrix_CH_V600_202502: start 46, 2 bit, big-endian, i-signal-type=PRIMITIVE, init-value=0, base-type=uint8, compu-method=CM_IBS_FLMovingDirection, data-constr=DC_IBS_FLMovingDirection, transfer-property=PENDING, to VCU  # EN: Front left wheel direction
            signal IBS_FLWheelSpeed_Fault_oIBS_WheelSpeed_01_oATOM_CANFD_Matrix_CH_V600_202502: start 47, 1 bit, big-endian, i-signal-type=PRIMITIVE, init-value=0, base-type=boolean, compu-method=CM_IBS_FLWheelSpeed_Fault, data-constr=DC_IBS_FLWheelSpeed_Fault, transfer-property=PENDING, to VCU  # EN: Front left wheel speed signal valid
            signal IBS_FLWheelPulseCounter_oIBS_WheelSpeed_01_oATOM_CANFD_Matrix_CH_V600_202502: start 63, 8 bit, big-endian, i-signal-type=PRIMITIVE, init-value=0, base-type=uint8, compu-method=CM_IBS_FLWheelPulseCounter, data-constr=DC_IBS_FLWheelPulseCounter, transfer-property=PENDING, to VCU  # EN: Front left wheel speed pulse
            mapping SG_IBS_WheelSpeed_01_SigGroup: i-signal-group=SG_IBS_WheelSpeed_01_SigGroup_oIBS_WheelSpeed_01_oATOM_CANFD_Matrix_CH_V600_202502, transfer-property=PENDING
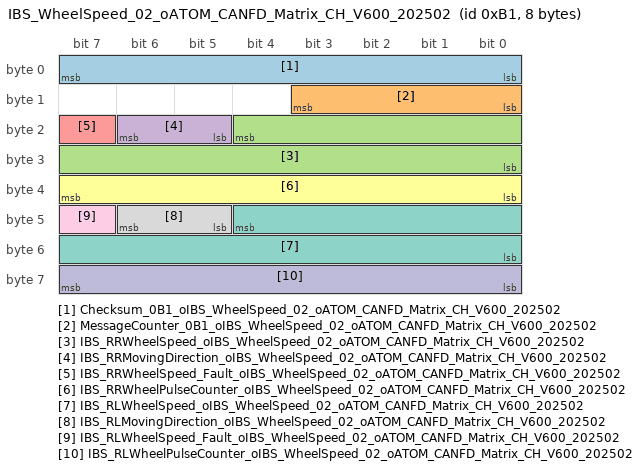
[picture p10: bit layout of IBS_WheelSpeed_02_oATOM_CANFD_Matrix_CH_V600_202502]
        frame IBS_WheelSpeed_02_oATOM_CANFD_Matrix_CH_V600_202502: id 0xB1, to VCU, frame-length=8, can-addressing-mode=STANDARD, can-frame-rx-behavior=ANY, can-frame-tx-behavior=CAN-FD
          pdu IBS_WheelSpeed_02_oATOM_CANFD_Matrix_CH_V600_202502: length=8, minimum-delay=0, transmission-mode-false-timing=cyclic-timing={time-offset=0, time-period=0.02}, transmission-mode-true-timing=cyclic-timing={time-offset=0, time-period=0.02}, unused-bit-pattern=0
            signal Checksum_0B1_oIBS_WheelSpeed_02_oATOM_CANFD_Matrix_CH_V600_202502: start 7, 8 bit, big-endian, i-signal-type=PRIMITIVE, init-value=0, base-type=uint8, compu-method=CM_Checksum_0B1, data-constr=DC_Checksum_0B1, transfer-property=PENDING, to VCU  # Checksum signal for frame
            signal MessageCounter_0B1_oIBS_WheelSpeed_02_oATOM_CANFD_Matrix_CH_V600_202502: start 11, 4 bit, big-endian, i-signal-type=PRIMITIVE, init-value=0, base-type=uint8, compu-method=CM_MessageCounter_0B1, data-constr=DC_MessageCounter_0B1, transfer-property=PENDING, to VCU  # Message counter signal for frame
            signal IBS_RRWheelSpeed_oIBS_WheelSpeed_02_oATOM_CANFD_Matrix_CH_V600_202502: start 20, 13 bit, big-endian, i-signal-type=PRIMITIVE, init-value=0, base-type=uint16, compu-method=CM_IBS_RRWheelSpeed, data-constr=DC_IBS_RRWheelSpeed, unit=U_kmYh, transfer-property=PENDING, to VCU  # EN: Rear right wheel speed
            signal IBS_RRMovingDirection_oIBS_WheelSpeed_02_oATOM_CANFD_Matrix_CH_V600_202502: start 22, 2 bit, big-endian, i-signal-type=PRIMITIVE, init-value=0, base-type=uint8, compu-method=CM_IBS_RRMovingDirection, data-constr=DC_IBS_RRMovingDirection, transfer-property=PENDING, to VCU  # EN: Rear right wheel direction
            signal IBS_RRWheelSpeed_Fault_oIBS_WheelSpeed_02_oATOM_CANFD_Matrix_CH_V600_202502: start 23, 1 bit, big-endian, i-signal-type=PRIMITIVE, init-value=0, base-type=boolean, compu-method=CM_IBS_RRWheelSpeed_Fault, data-constr=DC_IBS_RRWheelSpeed_Fault, transfer-property=PENDING, to VCU  # EN: Rear right wheel speed signal valid
            signal IBS_RRWheelPulseCounter_oIBS_WheelSpeed_02_oATOM_CANFD_Matrix_CH_V600_202502: start 39, 8 bit, big-endian, i-signal-type=PRIMITIVE, init-value=0, base-type=uint8, compu-method=CM_IBS_RRWheelPulseCounter, data-constr=DC_IBS_RRWheelPulseCounter, transfer-property=PENDING, to VCU  # EN: Rear right wheel speed pulse
            signal IBS_RLWheelSpeed_oIBS_WheelSpeed_02_oATOM_CANFD_Matrix_CH_V600_202502: start 44, 13 bit, big-endian, i-signal-type=PRIMITIVE, init-value=0, base-type=uint16, compu-method=CM_IBS_RLWheelSpeed, data-constr=DC_IBS_RLWheelSpeed, unit=U_kmYh, transfer-property=PENDING, to VCU  # EN: Rear left wheel speed
            signal IBS_RLMovingDirection_oIBS_WheelSpeed_02_oATOM_CANFD_Matrix_CH_V600_202502: start 46, 2 bit, big-endian, i-signal-type=PRIMITIVE, init-value=0, base-type=uint8, compu-method=CM_IBS_RLMovingDirection, data-constr=DC_IBS_RLMovingDirection, transfer-property=PENDING, to VCU  # EN: Rear left wheel direction
            signal IBS_RLWheelSpeed_Fault_oIBS_WheelSpeed_02_oATOM_CANFD_Matrix_CH_V600_202502: start 47, 1 bit, big-endian, i-signal-type=PRIMITIVE, init-value=0, base-type=boolean, compu-method=CM_IBS_RLWheelSpeed_Fault, data-constr=DC_IBS_RLWheelSpeed_Fault, transfer-property=PENDING, to VCU  # EN: Rear left wheel speed signal valid
            signal IBS_RLWheelPulseCounter_oIBS_WheelSpeed_02_oATOM_CANFD_Matrix_CH_V600_202502: start 63, 8 bit, big-endian, i-signal-type=PRIMITIVE, init-value=0, base-type=uint8, compu-method=CM_IBS_RLWheelPulseCounter, data-constr=DC_IBS_RLWheelPulseCounter, transfer-property=PENDING, to VCU  # EN: Rear left wheel speed pulse
            mapping SG_IBS_WheelSpeed_02_SigGroup: i-signal-group=SG_IBS_WheelSpeed_02_SigGroup_oIBS_WheelSpeed_02_oATOM_CANFD_Matrix_CH_V600_202502, transfer-property=PENDING
        frame NM_CGW_oATOM_CANFD_Matrix_CH_V600_202502: id 0x502, to VCU, frame-length=8, can-addressing-mode=STANDARD, can-frame-rx-behavior=ANY, can-frame-tx-behavior=CAN-20
          nm pdu NM_CGW_oATOM_CANFD_Matrix_CH_V600_202502: length=8, unused-bit-pattern=0
        frame NM_VCU_oATOM_CANFD_Matrix_CH_V600_202502: id 0x52C, from VCU, frame-length=8, can-addressing-mode=STANDARD, can-frame-rx-behavior=ANY, can-frame-tx-behavior=CAN-20
          nm pdu NM_VCU_oATOM_CANFD_Matrix_CH_V600_202502: length=8, unused-bit-pattern=0
        frame SGW_17_oATOM_CANFD_Matrix_CH_V600_202502: id 0x352, to VCU, frame-length=8, can-addressing-mode=STANDARD, can-frame-rx-behavior=ANY, can-frame-tx-behavior=CAN-FD
          pdu SGW_17_oATOM_CANFD_Matrix_CH_V600_202502: length=8, minimum-delay=0.02, transmission-mode-false-timing={cyclic-timing={time-offset=0, time-period=0.2}, event-controlled-timing={number-of-repetitions=3, repetition-period=0.02}}, transmission-mode-true-timing={cyclic-timing={time-offset=0, time-period=0.2}, event-controlled-timing={number-of-repetitions=3, repetition-period=0.02}}, unused-bit-pattern=0
            signal SGW_BLESystemReadyReq_oSGW_17_oATOM_CANFD_Matrix_CH_V600_202502: start 3, 2 bit, big-endian, i-signal-type=PRIMITIVE, init-value=0, base-type=uint8, compu-method=CM_SGW_BLESystemReadyReq, data-constr=DC_SGW_BLESystemReadyReq, transfer-property=TRIGGERED-ON-CHANGE, to VCU  # CBM request ready
            mapping SG_SGW_17_SigGroup: i-signal-group=SG_SGW_17_SigGroup_oSGW_17_oATOM_CANFD_Matrix_CH_V600_202502, transfer-property=PENDING
        frame VCU_02_oATOM_CANFD_Matrix_CH_V600_202502: id 0x319, from VCU, frame-length=8, can-addressing-mode=STANDARD, can-frame-rx-behavior=ANY, can-frame-tx-behavior=CAN-FD
          pdu VCU_02_oATOM_CANFD_Matrix_CH_V600_202502: length=8, minimum-delay=0, transmission-mode-false-timing=cyclic-timing={time-offset=0, time-period=0.2}, transmission-mode-true-timing=cyclic-timing={time-offset=0, time-period=0.2}, unused-bit-pattern=0
            signal VCU_BS_IBSBatSOC_oVCU_02_oATOM_CANFD_Matrix_CH_V600_202502: start 7, 8 bit, big-endian, i-signal-type=PRIMITIVE, init-value=80, base-type=uint8, compu-method=CM_VCU_BS_IBSBatSOC, data-constr=DC_VCU_BS_IBSBatSOC, unit=U_percent, transfer-property=PENDING  # LV Battery SOC
            signal VCU_BS_Current_oVCU_02_oATOM_CANFD_Matrix_CH_V600_202502: start 15, 14 bit, big-endian, i-signal-type=PRIMITIVE, init-value=0, base-type=uint16, compu-method=CM_VCU_BS_Current, data-constr=DC_VCU_BS_Current, transfer-property=PENDING  # LV Battery current(Route Lin signal ' BS_BatCrntRawVal')
            signal VCU_BS_IndicatorSts_oVCU_02_oATOM_CANFD_Matrix_CH_V600_202502: start 31, 1 bit, big-endian, i-signal-type=PRIMITIVE, init-value=0, base-type=boolean, compu-method=CM_VCU_BS_IndicatorSts, data-constr=DC_VCU_BS_IndicatorSts, transfer-property=PENDING  # Battery failure
            signal VCU_BS_LV_Batt_oVCU_02_oATOM_CANFD_Matrix_CH_V600_202502: start 47, 15 bit, big-endian, i-signal-type=PRIMITIVE, init-value=0, base-type=uint16, compu-method=CM_VCU_BS_LV_Batt, data-constr=DC_VCU_BS_LV_Batt, unit=U_V, transfer-property=PENDING  # LV Battery voltage(Route Lin signal 'BS_BatVltHIRes')
            signal VCU_WakeUpStatus_oVCU_02_oATOM_CANFD_Matrix_CH_V600_202502: start 63, 8 bit, big-endian, i-signal-type=PRIMITIVE, init-value=0, base-type=uint8, compu-method=CM_VCU_WakeUpStatus, data-constr=DC_VCU_WakeUpStatus, transfer-property=PENDING  # VCU Wake Up Status
            mapping SG_VCU_02_SigGroup: i-signal-group=SG_VCU_02_SigGroup_oVCU_02_oATOM_CANFD_Matrix_CH_V600_202502, transfer-property=PENDING
        frame VCU_03_oATOM_CANFD_Matrix_CH_V600_202502: id 0x222, from VCU, frame-length=8, can-addressing-mode=STANDARD, can-frame-rx-behavior=ANY, can-frame-tx-behavior=CAN-FD
          pdu VCU_03_oATOM_CANFD_Matrix_CH_V600_202502: length=8, minimum-delay=0, transmission-mode-false-timing=cyclic-timing={time-offset=0, time-period=0.1}, transmission-mode-true-timing=cyclic-timing={time-offset=0, time-period=0.1}, unused-bit-pattern=0
            signal VCU_DCFCCurrent_oVCU_03_oATOM_CANFD_Matrix_CH_V600_202502: start 23, 10 bit, big-endian, i-signal-type=PRIMITIVE, init-value=0, base-type=uint16, compu-method=CM_VCU_DCFCCurrent, data-constr=DC_VCU_DCFCCurrent, unit=U_A, transfer-property=PENDING  # DC charging current calculated by VCU
            signal VCU_ChargeProcessComment_oVCU_03_oATOM_CANFD_Matrix_CH_V600_202502: start 25, 2 bit, big-endian, i-signal-type=PRIMITIVE, init-value=0, base-type=uint8, compu-method=CM_VCU_ChargeProcessComment, data-constr=DC_VCU_ChargeProcessComment, transfer-property=PENDING  # Abnormal prompt in charging stage
            signal VCU_BrakeCompensateStatus_oVCU_03_oATOM_CANFD_Matrix_CH_V600_202502: start 27, 2 bit, big-endian, i-signal-type=PRIMITIVE, init-value=0, base-type=uint8, compu-method=CM_VCU_BrakeCompensateStatus, data-constr=DC_VCU_BrakeCompensateStatus, transfer-property=PENDING  # Brake compensation open state
            signal VCU_EnergyV2L_oVCU_03_oATOM_CANFD_Matrix_CH_V600_202502: start 55, 12 bit, big-endian, i-signal-type=PRIMITIVE, init-value=0, base-type=uint16, compu-method=CM_VCU_EnergyV2L, data-constr=DC_VCU_EnergyV2L, unit=U_kWh, transfer-property=PENDING  # VCU feedback discharge quantity signal
            signal VCU_MemoryChargeFault_oVCU_03_oATOM_CANFD_Matrix_CH_V600_202502: start 59, 1 bit, big-endian, i-signal-type=PRIMITIVE, init-value=0, base-type=boolean, compu-method=CM_VCU_MemoryChargeFault, data-constr=DC_VCU_MemoryChargeFault, transfer-property=PENDING  # Charging fault status of VCU memory
            mapping SG_VCU_03_SigGroup: i-signal-group=SG_VCU_03_SigGroup_oVCU_03_oATOM_CANFD_Matrix_CH_V600_202502, transfer-property=PENDING
        frame VCU_04_oATOM_CANFD_Matrix_CH_V600_202502: id 0x223, from VCU, frame-length=8, can-addressing-mode=STANDARD, can-frame-rx-behavior=ANY, can-frame-tx-behavior=CAN-FD
          pdu VCU_04_oATOM_CANFD_Matrix_CH_V600_202502: length=8, minimum-delay=0, transmission-mode-false-timing=cyclic-timing={time-offset=0, time-period=0.1}, transmission-mode-true-timing=cyclic-timing={time-offset=0, time-period=0.1}, unused-bit-pattern=0
            signal VCU_ManuallyUnlockComment_oVCU_04_oATOM_CANFD_Matrix_CH_V600_202502: start 14, 1 bit, big-endian, i-signal-type=PRIMITIVE, init-value=0, base-type=boolean, compu-method=CM_VCU_ManuallyUnlockComment, data-constr=DC_VCU_ManuallyUnlockComment, transfer-property=PENDING  # Manual unlock electronic lock reminder signal
            signal VCU_ForwardVmaxlimitStatus_oVCU_04_oATOM_CANFD_Matrix_CH_V600_202502: start 15, 1 bit, big-endian, i-signal-type=PRIMITIVE, init-value=0, base-type=boolean, compu-method=CM_VCU_ForwardVmaxlimitStatus, data-constr=DC_VCU_ForwardVmaxlimitStatus, transfer-property=PENDING  # maximum speed limit status in D gear
            mapping SG_VCU_04_SigGroup: i-signal-group=SG_VCU_04_SigGroup_oVCU_04_oATOM_CANFD_Matrix_CH_V600_202502, transfer-property=PENDING
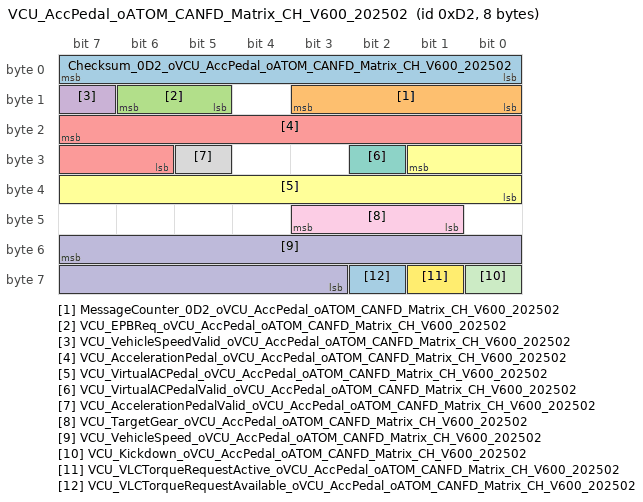
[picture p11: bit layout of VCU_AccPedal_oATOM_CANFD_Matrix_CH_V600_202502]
        frame VCU_AccPedal_oATOM_CANFD_Matrix_CH_V600_202502: id 0xD2, from VCU, frame-length=8, can-addressing-mode=STANDARD, can-frame-rx-behavior=ANY, can-frame-tx-behavior=CAN-FD
          pdu VCU_AccPedal_oATOM_CANFD_Matrix_CH_V600_202502: length=8, minimum-delay=0, transmission-mode-false-timing=cyclic-timing={time-offset=0, time-period=0.02}, transmission-mode-true-timing=cyclic-timing={time-offset=0, time-period=0.02}, unused-bit-pattern=0
            signal Checksum_0D2_oVCU_AccPedal_oATOM_CANFD_Matrix_CH_V600_202502: start 7, 8 bit, big-endian, i-signal-type=PRIMITIVE, init-value=0, base-type=uint8, compu-method=CM_Checksum_0D2, data-constr=DC_Checksum_0D2, transfer-property=PENDING  # Checksum signal for frame
            signal MessageCounter_0D2_oVCU_AccPedal_oATOM_CANFD_Matrix_CH_V600_202502: start 11, 4 bit, big-endian, i-signal-type=PRIMITIVE, init-value=0, base-type=uint8, compu-method=CM_MessageCounter_0D2, data-constr=DC_MessageCounter_0D2, transfer-property=PENDING  # Message counter signal for frame
            signal VCU_EPBReq_oVCU_AccPedal_oATOM_CANFD_Matrix_CH_V600_202502: start 14, 2 bit, big-endian, i-signal-type=PRIMITIVE, init-value=0, base-type=uint8, compu-method=CM_VCU_EPBReq, data-constr=DC_VCU_EPBReq, transfer-property=PENDING  # VCU request EPB
            signal VCU_VehicleSpeedValid_oVCU_AccPedal_oATOM_CANFD_Matrix_CH_V600_202502: start 15, 1 bit, big-endian, i-signal-type=PRIMITIVE, init-value=0, base-type=boolean, compu-method=CM_VCU_VehicleSpeedValid, data-constr=DC_VCU_VehicleSpeedValid, transfer-property=PENDING  # Speed Validity Flag
            signal VCU_AccelerationPedal_oVCU_AccPedal_oATOM_CANFD_Matrix_CH_V600_202502: start 23, 10 bit, big-endian, i-signal-type=PRIMITIVE, init-value=0, base-type=uint16, compu-method=CM_VCU_AccelerationPedal, data-constr=DC_VCU_AccelerationPedal, unit=U_percent, transfer-property=PENDING  # Acceleration Pedal percentage
            signal VCU_VirtualACPedal_oVCU_AccPedal_oATOM_CANFD_Matrix_CH_V600_202502: start 25, 10 bit, big-endian, i-signal-type=PRIMITIVE, init-value=0, base-type=uint16, compu-method=CM_VCU_VirtualACPedal, data-constr=DC_VCU_VirtualACPedal, unit=U_percent, transfer-property=PENDING  # Virtual acceleration Pedal percentage
            signal VCU_VirtualACPedalValid_oVCU_AccPedal_oATOM_CANFD_Matrix_CH_V600_202502: start 26, 1 bit, big-endian, i-signal-type=PRIMITIVE, init-value=0, base-type=boolean, compu-method=CM_VCU_VirtualACPedalValid, data-constr=DC_VCU_VirtualACPedalValid, transfer-property=PENDING  # Virtual acceleration Pedal percentage valid status
            signal VCU_AccelerationPedalValid_oVCU_AccPedal_oATOM_CANFD_Matrix_CH_V600_202502: start 29, 1 bit, big-endian, i-signal-type=PRIMITIVE, init-value=0, base-type=boolean, compu-method=CM_VCU_AccelerationPedalValid, data-constr=DC_VCU_AccelerationPedalValid, transfer-property=PENDING  # Acceleration Pedal percentage valid status
            signal VCU_TargetGear_oVCU_AccPedal_oATOM_CANFD_Matrix_CH_V600_202502: start 43, 3 bit, big-endian, i-signal-type=PRIMITIVE, init-value=0, base-type=uint8, compu-method=CM_VCU_TargetGear, data-constr=DC_VCU_TargetGear, transfer-property=PENDING  # Target Gear position
            signal VCU_VehicleSpeed_oVCU_AccPedal_oATOM_CANFD_Matrix_CH_V600_202502: start 55, 13 bit, big-endian, i-signal-type=PRIMITIVE, init-value=0, base-type=uint16, compu-method=CM_VCU_VehicleSpeed, data-constr=DC_VCU_VehicleSpeed, unit=U_kmYh, transfer-property=PENDING  # VCU calculates the output vehicle speed
            signal VCU_Kickdown_oVCU_AccPedal_oATOM_CANFD_Matrix_CH_V600_202502: start 56, 1 bit, big-endian, i-signal-type=PRIMITIVE, init-value=0, base-type=boolean, compu-method=CM_VCU_Kickdown, data-constr=DC_VCU_Kickdown, transfer-property=PENDING  # Kickdown
            signal VCU_VLCTorqueRequestActive_oVCU_AccPedal_oATOM_CANFD_Matrix_CH_V600_202502: start 57, 1 bit, big-endian, i-signal-type=PRIMITIVE, init-value=0, base-type=boolean, compu-method=CM_VCU_VLCTorqueRequestActive, data-constr=DC_VCU_VLCTorqueRequestActive, transfer-property=PENDING  # Is the VCU responding to VLC torque request function activated
            signal VCU_VLCTorqueRequestAvailable_oVCU_AccPedal_oATOM_CANFD_Matrix_CH_V600_202502: start 58, 1 bit, big-endian, i-signal-type=PRIMITIVE, init-value=0, base-type=boolean, compu-method=CM_VCU_VLCTorqueRequestAvailable, data-constr=DC_VCU_VLCTorqueRequestAvailable, transfer-property=PENDING  # Is VCU available to respond to VLC torque requests
            mapping SG_VCU_AccPedal_SigGroup: i-signal-group=SG_VCU_AccPedal_SigGroup_oVCU_AccPedal_oATOM_CANFD_Matrix_CH_V600_202502, transfer-property=PENDING
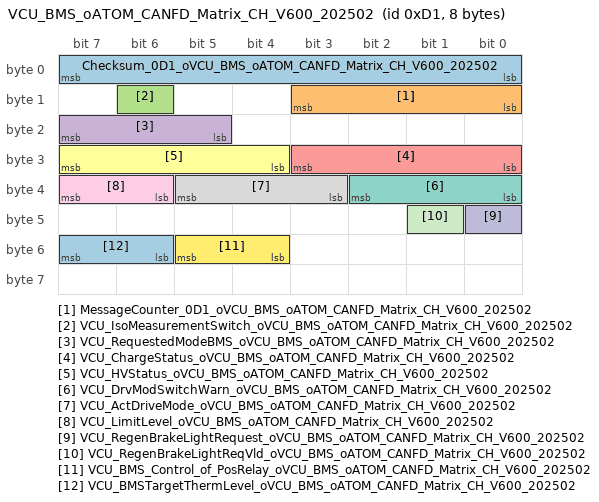
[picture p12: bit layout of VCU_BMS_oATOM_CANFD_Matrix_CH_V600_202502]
        frame VCU_BMS_oATOM_CANFD_Matrix_CH_V600_202502: id 0xD1, from VCU, frame-length=8, can-addressing-mode=STANDARD, can-frame-rx-behavior=ANY, can-frame-tx-behavior=CAN-FD
          pdu VCU_BMS_oATOM_CANFD_Matrix_CH_V600_202502: length=8, minimum-delay=0, transmission-mode-false-timing=cyclic-timing={time-offset=0, time-period=0.02}, transmission-mode-true-timing=cyclic-timing={time-offset=0, time-period=0.02}, unused-bit-pattern=0
            signal Checksum_0D1_oVCU_BMS_oATOM_CANFD_Matrix_CH_V600_202502: start 7, 8 bit, big-endian, i-signal-type=PRIMITIVE, init-value=0, base-type=uint8, compu-method=CM_Checksum_0D1, data-constr=DC_Checksum_0D1, transfer-property=PENDING  # Checksum signal for frame
            signal MessageCounter_0D1_oVCU_BMS_oATOM_CANFD_Matrix_CH_V600_202502: start 11, 4 bit, big-endian, i-signal-type=PRIMITIVE, init-value=0, base-type=uint8, compu-method=CM_MessageCounter_0D1, data-constr=DC_MessageCounter_0D1, transfer-property=PENDING  # Message counter signal for frame
            signal VCU_IsoMeasurementSwitch_oVCU_BMS_oATOM_CANFD_Matrix_CH_V600_202502: start 14, 1 bit, big-endian, i-signal-type=PRIMITIVE, init-value=1, base-type=boolean, compu-method=CM_VCU_IsoMeasurementSwitch, data-constr=DC_VCU_IsoMeasurementSwitch, transfer-property=PENDING  # Insulation detection enable instruction.
            signal VCU_RequestedModeBMS_oVCU_BMS_oATOM_CANFD_Matrix_CH_V600_202502: start 23, 3 bit, big-endian, i-signal-type=PRIMITIVE, init-value=0, base-type=uint8, compu-method=CM_VCU_RequestedModeBMS, data-constr=DC_VCU_RequestedModeBMS, transfer-property=PENDING  # Interface to request eletric energy storage target mode
            signal VCU_ChargeStatus_oVCU_BMS_oATOM_CANFD_Matrix_CH_V600_202502: start 27, 4 bit, big-endian, i-signal-type=PRIMITIVE, init-value=0, base-type=uint8, compu-method=CM_VCU_ChargeStatus, data-constr=DC_VCU_ChargeStatus, transfer-property=PENDING  # Charge state
            signal VCU_HVStatus_oVCU_BMS_oATOM_CANFD_Matrix_CH_V600_202502: start 31, 4 bit, big-endian, i-signal-type=PRIMITIVE, init-value=0, base-type=uint8, compu-method=CM_VCU_HVStatus, data-constr=DC_VCU_HVStatus, transfer-property=PENDING  # HV System state
            signal VCU_DrvModSwitchWarn_oVCU_BMS_oATOM_CANFD_Matrix_CH_V600_202502: start 34, 3 bit, big-endian, i-signal-type=PRIMITIVE, init-value=0, base-type=uint8, compu-method=CM_VCU_DrvModSwitchWarn, data-constr=DC_VCU_DrvModSwitchWarn, transfer-property=PENDING  # Warning dispaly when dirve mode swich
            signal VCU_ActDriveMode_oVCU_BMS_oATOM_CANFD_Matrix_CH_V600_202502: start 37, 3 bit, big-endian, i-signal-type=PRIMITIVE, init-value=0, base-type=uint8, compu-method=CM_VCU_ActDriveMode, data-constr=DC_VCU_ActDriveMode, transfer-property=PENDING  # Actual drive mode
            signal VCU_LimitLevel_oVCU_BMS_oATOM_CANFD_Matrix_CH_V600_202502: start 39, 2 bit, big-endian, i-signal-type=PRIMITIVE, init-value=0, base-type=uint8, compu-method=CM_VCU_LimitLevel, data-constr=DC_VCU_LimitLevel, transfer-property=PENDING  # Low-voltage energy management limit level
            signal VCU_RegenBrakeLightRequest_oVCU_BMS_oATOM_CANFD_Matrix_CH_V600_202502: start 40, 1 bit, big-endian, i-signal-type=PRIMITIVE, init-value=0, base-type=boolean, compu-method=CM_VCU_RegenBrakeLightRequest, data-constr=DC_VCU_RegenBrakeLightRequest, transfer-property=PENDING  # Request to illuminate the brake lights from the Powertrain if regen creates deceleration greater than 0.07g.
            signal VCU_RegenBrakeLightReqVld_oVCU_BMS_oATOM_CANFD_Matrix_CH_V600_202502: start 41, 1 bit, big-endian, i-signal-type=PRIMITIVE, init-value=0, base-type=boolean, compu-method=CM_VCU_RegenBrakeLightReqVld, data-constr=DC_VCU_RegenBrakeLightReqVld, transfer-property=PENDING  # Valid status of Request to illuminate the brake lights from the Powertrain
            signal VCU_BMS_Control_of_PosRelay_oVCU_BMS_oATOM_CANFD_Matrix_CH_V600_202502: start 53, 2 bit, big-endian, i-signal-type=PRIMITIVE, init-value=0, base-type=uint8, compu-method=CM_VCU_BMS_Control_of_PosRelay, data-constr=DC_VCU_BMS_Control_of_PosRelay, transfer-property=PENDING  # Request for closing positive relay
            signal VCU_BMSTargetThermLevel_oVCU_BMS_oATOM_CANFD_Matrix_CH_V600_202502: start 55, 2 bit, big-endian, i-signal-type=PRIMITIVE, init-value=0, base-type=uint8, compu-method=CM_VCU_BMSTargetThermLevel, data-constr=DC_VCU_BMSTargetThermLevel, transfer-property=PENDING  # BMS target temperature level
            mapping SG_VCU_BMS_SigGroup: i-signal-group=SG_VCU_BMS_SigGroup_oVCU_BMS_oATOM_CANFD_Matrix_CH_V600_202502, transfer-property=PENDING
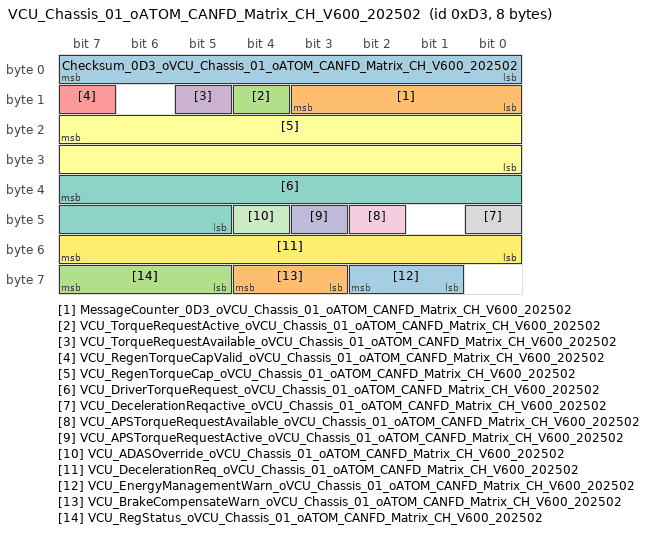
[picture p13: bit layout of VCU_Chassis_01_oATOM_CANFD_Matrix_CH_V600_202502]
        frame VCU_Chassis_01_oATOM_CANFD_Matrix_CH_V600_202502: id 0xD3, from VCU, frame-length=8, can-addressing-mode=STANDARD, can-frame-rx-behavior=ANY, can-frame-tx-behavior=CAN-FD
          pdu VCU_Chassis_01_oATOM_CANFD_Matrix_CH_V600_202502: length=8, minimum-delay=0, transmission-mode-false-timing=cyclic-timing={time-offset=0, time-period=0.02}, transmission-mode-true-timing=cyclic-timing={time-offset=0, time-period=0.02}, unused-bit-pattern=0
            signal Checksum_0D3_oVCU_Chassis_01_oATOM_CANFD_Matrix_CH_V600_202502: start 7, 8 bit, big-endian, i-signal-type=PRIMITIVE, init-value=0, base-type=uint8, compu-method=CM_Checksum_0D3, data-constr=DC_Checksum_0D3, transfer-property=PENDING  # Checksum signal for frame
            signal MessageCounter_0D3_oVCU_Chassis_01_oATOM_CANFD_Matrix_CH_V600_202502: start 11, 4 bit, big-endian, i-signal-type=PRIMITIVE, init-value=0, base-type=uint8, compu-method=CM_MessageCounter_0D3, data-constr=DC_MessageCounter_0D3, transfer-property=PENDING  # Message counter signal for frame
            signal VCU_TorqueRequestActive_oVCU_Chassis_01_oATOM_CANFD_Matrix_CH_V600_202502: start 12, 1 bit, big-endian, i-signal-type=PRIMITIVE, init-value=0, base-type=boolean, compu-method=CM_VCU_TorqueRequestActive, data-constr=DC_VCU_TorqueRequestActive, transfer-property=PENDING  # Active status of VCU in response to the external torque request
            signal VCU_TorqueRequestAvailable_oVCU_Chassis_01_oATOM_CANFD_Matrix_CH_V600_202502: start 13, 1 bit, big-endian, i-signal-type=PRIMITIVE, init-value=0, base-type=boolean, compu-method=CM_VCU_TorqueRequestAvailable, data-constr=DC_VCU_TorqueRequestAvailable, transfer-property=PENDING  # Available status of VCU in response to the external torque request
            signal VCU_RegenTorqueCapValid_oVCU_Chassis_01_oATOM_CANFD_Matrix_CH_V600_202502: start 15, 1 bit, big-endian, i-signal-type=PRIMITIVE, init-value=0, base-type=boolean, compu-method=CM_VCU_RegenTorqueCapValid, data-constr=DC_VCU_RegenTorqueCapValid, transfer-property=PENDING  # brake recovery torque cap valid
            signal VCU_RegenTorqueCap_oVCU_Chassis_01_oATOM_CANFD_Matrix_CH_V600_202502: start 23, 16 bit, big-endian, i-signal-type=PRIMITIVE, init-value=0, base-type=uint16, compu-method=CM_VCU_RegenTorqueCap, data-constr=DC_VCU_RegenTorqueCap, transfer-property=PENDING  # Maximum brake recovery torque of motor
            signal VCU_DriverTorqueRequest_oVCU_Chassis_01_oATOM_CANFD_Matrix_CH_V600_202502: start 39, 11 bit, big-endian, i-signal-type=PRIMITIVE, init-value=0, base-type=uint16, compu-method=CM_VCU_DriverTorqueRequest, data-constr=DC_VCU_DriverTorqueRequest, transfer-property=PENDING  # Driver torque request
            signal VCU_DecelerationReqactive_oVCU_Chassis_01_oATOM_CANFD_Matrix_CH_V600_202502: start 40, 1 bit, big-endian, i-signal-type=PRIMITIVE, init-value=0, base-type=boolean, compu-method=CM_VCU_DecelerationReqactive, data-constr=DC_VCU_DecelerationReqactive, transfer-property=PENDING  # Request deceleration from IBS
            signal VCU_APSTorqueRequestAvailable_oVCU_Chassis_01_oATOM_CANFD_Matrix_CH_V600_202502: start 42, 1 bit, big-endian, i-signal-type=PRIMITIVE, init-value=0, base-type=boolean, compu-method=CM_VCU_APSTorqueRequestAvailable, data-constr=DC_VCU_APSTorqueRequestAvailable, transfer-property=PENDING  # Is VCU available to respond to VLC torque requests
            signal VCU_APSTorqueRequestActive_oVCU_Chassis_01_oATOM_CANFD_Matrix_CH_V600_202502: start 43, 1 bit, big-endian, i-signal-type=PRIMITIVE, init-value=0, base-type=boolean, compu-method=CM_VCU_APSTorqueRequestActive, data-constr=DC_VCU_APSTorqueRequestActive, transfer-property=PENDING  # Is the VCU responding to VLC torque request function activated
            signal VCU_ADASOverride_oVCU_Chassis_01_oATOM_CANFD_Matrix_CH_V600_202502: start 44, 1 bit, big-endian, i-signal-type=PRIMITIVE, init-value=0, base-type=boolean, compu-method=CM_VCU_ADASOverride, data-constr=DC_VCU_ADASOverride, transfer-property=PENDING  # Override signal
            signal VCU_DecelerationReq_oVCU_Chassis_01_oATOM_CANFD_Matrix_CH_V600_202502: start 55, 8 bit, big-endian, i-signal-type=PRIMITIVE, init-value=0, base-type=uint8, compu-method=CM_VCU_DecelerationReq, data-constr=DC_VCU_DecelerationReq, unit=U_mYsX2, transfer-property=PENDING  # One-pedal VCU deceleration request
            signal VCU_EnergyManagementWarn_oVCU_Chassis_01_oATOM_CANFD_Matrix_CH_V600_202502: start 58, 2 bit, big-endian, i-signal-type=PRIMITIVE, init-value=0, base-type=uint8, compu-method=CM_VCU_EnergyManagementWarn, data-constr=DC_VCU_EnergyManagementWarn, transfer-property=PENDING  # The warning of energy management
            signal VCU_BrakeCompensateWarn_oVCU_Chassis_01_oATOM_CANFD_Matrix_CH_V600_202502: start 60, 2 bit, big-endian, i-signal-type=PRIMITIVE, init-value=0, base-type=uint8, compu-method=CM_VCU_BrakeCompensateWarn, data-constr=DC_VCU_BrakeCompensateWarn, transfer-property=PENDING  # The warning of brake compensation failure.
            signal VCU_RegStatus_oVCU_Chassis_01_oATOM_CANFD_Matrix_CH_V600_202502: start 63, 3 bit, big-endian, i-signal-type=PRIMITIVE, init-value=0, base-type=uint8, compu-method=CM_VCU_RegStatus, data-constr=DC_VCU_RegStatus, transfer-property=PENDING  # The energy recovery level
            mapping SG_VCU_Chassis_01_SigGroup: i-signal-group=SG_VCU_Chassis_01_SigGroup_oVCU_Chassis_01_oATOM_CANFD_Matrix_CH_V600_202502, transfer-property=PENDING
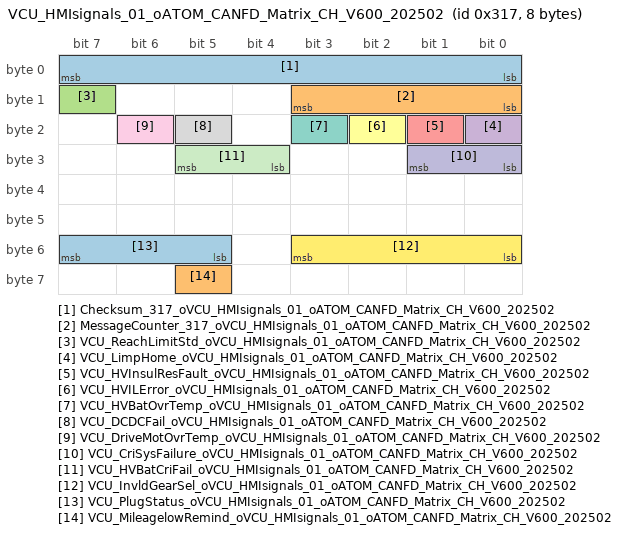
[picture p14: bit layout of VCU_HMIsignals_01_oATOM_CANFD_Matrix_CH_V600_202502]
        frame VCU_HMIsignals_01_oATOM_CANFD_Matrix_CH_V600_202502: id 0x317, from VCU, frame-length=8, can-addressing-mode=STANDARD, can-frame-rx-behavior=ANY, can-frame-tx-behavior=CAN-FD
          pdu VCU_HMIsignals_01_oATOM_CANFD_Matrix_CH_V600_202502: length=8, minimum-delay=0, transmission-mode-false-timing=cyclic-timing={time-offset=0, time-period=0.2}, transmission-mode-true-timing=cyclic-timing={time-offset=0, time-period=0.2}, unused-bit-pattern=0
            signal Checksum_317_oVCU_HMIsignals_01_oATOM_CANFD_Matrix_CH_V600_202502: start 7, 8 bit, big-endian, i-signal-type=PRIMITIVE, init-value=0, base-type=uint8, compu-method=CM_Checksum_317, data-constr=DC_Checksum_317, transfer-property=PENDING  # Checksum signal for frame
            signal MessageCounter_317_oVCU_HMIsignals_01_oATOM_CANFD_Matrix_CH_V600_202502: start 11, 4 bit, big-endian, i-signal-type=PRIMITIVE, init-value=0, base-type=uint8, compu-method=CM_MessageCounter_317, data-constr=DC_MessageCounter_317, transfer-property=PENDING  # Message counter signal for frame
            signal VCU_ReachLimitStd_oVCU_HMIsignals_01_oATOM_CANFD_Matrix_CH_V600_202502: start 15, 1 bit, big-endian, i-signal-type=PRIMITIVE, init-value=0, base-type=boolean, compu-method=CM_VCU_ReachLimitStd, data-constr=DC_VCU_ReachLimitStd, transfer-property=PENDING  # SOC reaches the limit level prompt
            signal VCU_LimpHome_oVCU_HMIsignals_01_oATOM_CANFD_Matrix_CH_V600_202502: start 16, 1 bit, big-endian, i-signal-type=PRIMITIVE, init-value=0, base-type=boolean, compu-method=CM_VCU_LimpHome, data-constr=DC_VCU_LimpHome, transfer-property=PENDING  # Limp home: GB/T 4094.2, Table 1, No. 3
            signal VCU_HVInsulResFault_oVCU_HMIsignals_01_oATOM_CANFD_Matrix_CH_V600_202502: start 17, 1 bit, big-endian, i-signal-type=PRIMITIVE, init-value=0, base-type=boolean, compu-method=CM_VCU_HVInsulResFault, data-constr=DC_VCU_HVInsulResFault, transfer-property=PENDING  # Insulation resistance/creepage distance indication: rrequired via GB/T 19836
            signal VCU_HVILError_oVCU_HMIsignals_01_oATOM_CANFD_Matrix_CH_V600_202502: start 18, 1 bit, big-endian, i-signal-type=PRIMITIVE, init-value=0, base-type=boolean, compu-method=CM_VCU_HVILError, data-constr=DC_VCU_HVILError, transfer-property=PENDING  # HVIL error (Interlock monitoring device): required via GB/T 19836
            signal VCU_HVBatOvrTemp_oVCU_HMIsignals_01_oATOM_CANFD_Matrix_CH_V600_202502: start 19, 1 bit, big-endian, i-signal-type=PRIMITIVE, init-value=0, base-type=boolean, compu-method=CM_VCU_HVBatOvrTemp, data-constr=DC_VCU_HVBatOvrTemp, transfer-property=PENDING  # HV battery over temperature indicator
            signal VCU_DCDCFail_oVCU_HMIsignals_01_oATOM_CANFD_Matrix_CH_V600_202502: start 21, 1 bit, big-endian, i-signal-type=PRIMITIVE, init-value=0, base-type=boolean, compu-method=CM_VCU_DCDCFail, data-constr=DC_VCU_DCDCFail, transfer-property=PENDING  # DCDC failure status indicator
            signal VCU_DriveMotOvrTemp_oVCU_HMIsignals_01_oATOM_CANFD_Matrix_CH_V600_202502: start 22, 1 bit, big-endian, i-signal-type=PRIMITIVE, init-value=0, base-type=boolean, compu-method=CM_VCU_DriveMotOvrTemp, data-constr=DC_VCU_DriveMotOvrTemp, transfer-property=PENDING  # Over-temp required via GB/T 19836. Additional components may be needed.
            signal VCU_CriSysFailure_oVCU_HMIsignals_01_oATOM_CANFD_Matrix_CH_V600_202502: start 25, 2 bit, big-endian, i-signal-type=PRIMITIVE, init-value=0, base-type=uint8, compu-method=CM_VCU_CriSysFailure, data-constr=DC_VCU_CriSysFailure, transfer-property=PENDING  # System failure tell-tale: GB/T 4094.2, Table 2, No. 3
            signal VCU_HVBatCriFail_oVCU_HMIsignals_01_oATOM_CANFD_Matrix_CH_V600_202502: start 29, 2 bit, big-endian, i-signal-type=PRIMITIVE, init-value=0, base-type=uint8, compu-method=CM_VCU_HVBatCriFail, data-constr=DC_VCU_HVBatCriFail, transfer-property=PENDING  # Traction battery failure: GB/T 4094.2, Table 2, No. 1
            signal VCU_InvldGearSel_oVCU_HMIsignals_01_oATOM_CANFD_Matrix_CH_V600_202502: start 51, 4 bit, big-endian, i-signal-type=PRIMITIVE, init-value=0, base-type=uint8, compu-method=CM_VCU_InvldGearSel, data-constr=DC_VCU_InvldGearSel, transfer-property=PENDING  # Invalid Gear Selection Flag
            signal VCU_PlugStatus_oVCU_HMIsignals_01_oATOM_CANFD_Matrix_CH_V600_202502: start 55, 3 bit, big-endian, i-signal-type=PRIMITIVE, init-value=0, base-type=uint8, compu-method=CM_VCU_PlugStatus, data-constr=DC_VCU_PlugStatus, transfer-property=PENDING  # Charge and discharge gun connection state
            signal VCU_MileagelowRemind_oVCU_HMIsignals_01_oATOM_CANFD_Matrix_CH_V600_202502: start 61, 1 bit, big-endian, i-signal-type=PRIMITIVE, init-value=0, base-type=boolean, compu-method=CM_VCU_MileagelowRemind, data-constr=DC_VCU_MileagelowRemind, transfer-property=PENDING  # Mileage low Reminding
            mapping SG_VCU_HMIsignals_01_SigGroup: i-signal-group=SG_VCU_HMIsignals_01_SigGroup_oVCU_HMIsignals_01_oATOM_CANFD_Matrix_CH_V600_202502, transfer-property=PENDING
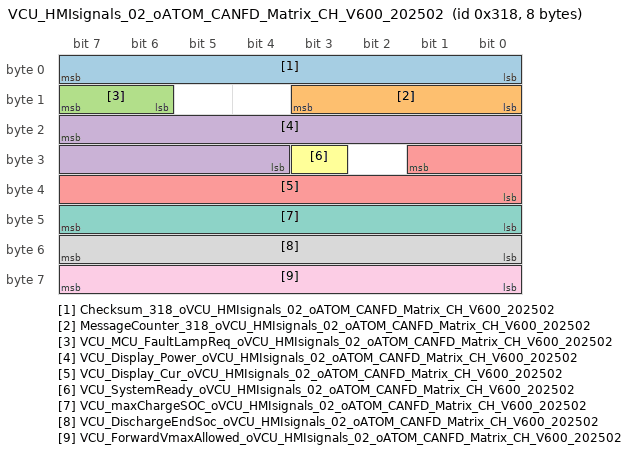
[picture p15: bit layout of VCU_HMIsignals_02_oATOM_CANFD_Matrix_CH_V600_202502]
        frame VCU_HMIsignals_02_oATOM_CANFD_Matrix_CH_V600_202502: id 0x318, from VCU, frame-length=8, can-addressing-mode=STANDARD, can-frame-rx-behavior=ANY, can-frame-tx-behavior=CAN-FD
          pdu VCU_HMIsignals_02_oATOM_CANFD_Matrix_CH_V600_202502: length=8, minimum-delay=0, transmission-mode-false-timing=cyclic-timing={time-offset=0, time-period=0.2}, transmission-mode-true-timing=cyclic-timing={time-offset=0, time-period=0.2}, unused-bit-pattern=0
            signal Checksum_318_oVCU_HMIsignals_02_oATOM_CANFD_Matrix_CH_V600_202502: start 7, 8 bit, big-endian, i-signal-type=PRIMITIVE, init-value=0, base-type=uint8, compu-method=CM_Checksum_318, data-constr=DC_Checksum_318, transfer-property=PENDING  # Checksum signal for frame
            signal MessageCounter_318_oVCU_HMIsignals_02_oATOM_CANFD_Matrix_CH_V600_202502: start 11, 4 bit, big-endian, i-signal-type=PRIMITIVE, init-value=0, base-type=uint8, compu-method=CM_MessageCounter_318, data-constr=DC_MessageCounter_318, transfer-property=PENDING  # Message counter signal for frame
            signal VCU_MCU_FaultLampReq_oVCU_HMIsignals_02_oATOM_CANFD_Matrix_CH_V600_202502: start 15, 2 bit, big-endian, i-signal-type=PRIMITIVE, init-value=0, base-type=uint8, compu-method=CM_VCU_MCU_FaultLampReq, data-constr=DC_VCU_MCU_FaultLampReq, transfer-property=PENDING  # MCU failure indicator
            signal VCU_Display_Power_oVCU_HMIsignals_02_oATOM_CANFD_Matrix_CH_V600_202502: start 23, 12 bit, big-endian, i-signal-type=PRIMITIVE, init-value=0, base-type=uint16, compu-method=CM_VCU_Display_Power, data-constr=DC_VCU_Display_Power, unit=U_kW, transfer-property=PENDING  # Charge and discharge power (display)
            signal VCU_Display_Cur_oVCU_HMIsignals_02_oATOM_CANFD_Matrix_CH_V600_202502: start 25, 10 bit, big-endian, i-signal-type=PRIMITIVE, init-value=0, base-type=uint16, compu-method=CM_VCU_Display_Cur, data-constr=DC_VCU_Display_Cur, unit=U_A, transfer-property=PENDING  # Charge and discharge current (display)
            signal VCU_SystemReady_oVCU_HMIsignals_02_oATOM_CANFD_Matrix_CH_V600_202502: start 27, 1 bit, big-endian, i-signal-type=PRIMITIVE, init-value=0, base-type=boolean, compu-method=CM_VCU_SystemReady, data-constr=DC_VCU_SystemReady, transfer-property=PENDING  # Ready lamp indicator
            signal VCU_maxChargeSOC_oVCU_HMIsignals_02_oATOM_CANFD_Matrix_CH_V600_202502: start 47, 8 bit, big-endian, i-signal-type=PRIMITIVE, init-value=255, base-type=uint8, compu-method=CM_VCU_maxChargeSOC, data-constr=DC_VCU_maxChargeSOC, transfer-property=PENDING  # Target charging level setting feedback signal
            signal VCU_DischargeEndSoc_oVCU_HMIsignals_02_oATOM_CANFD_Matrix_CH_V600_202502: start 55, 8 bit, big-endian, i-signal-type=PRIMITIVE, init-value=50, base-type=uint8, compu-method=CM_VCU_DischargeEndSoc, data-constr=DC_VCU_DischargeEndSoc, unit=U_percent, transfer-property=PENDING  # Discharge cutoff SOC
            signal VCU_ForwardVmaxAllowed_oVCU_HMIsignals_02_oATOM_CANFD_Matrix_CH_V600_202502: start 63, 8 bit, big-endian, i-signal-type=PRIMITIVE, init-value=0, base-type=uint8, compu-method=CM_VCU_ForwardVmaxAllowed, data-constr=DC_VCU_ForwardVmaxAllowed, transfer-property=PENDING  # Maximum speed setting state of D gear
            mapping SG_VCU_HMIsignals_02_SigGroup: i-signal-group=SG_VCU_HMIsignals_02_SigGroup_oVCU_HMIsignals_02_oATOM_CANFD_Matrix_CH_V600_202502, transfer-property=PENDING
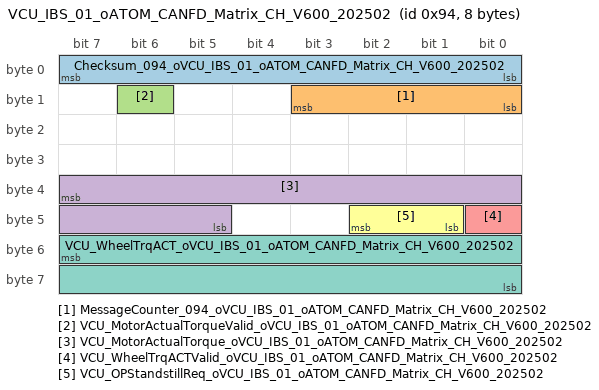
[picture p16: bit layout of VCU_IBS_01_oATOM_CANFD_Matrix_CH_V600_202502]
        frame VCU_IBS_01_oATOM_CANFD_Matrix_CH_V600_202502: id 0x94, from VCU, frame-length=8, can-addressing-mode=STANDARD, can-frame-rx-behavior=ANY, can-frame-tx-behavior=CAN-FD
          pdu VCU_IBS_01_oATOM_CANFD_Matrix_CH_V600_202502: length=8, minimum-delay=0, transmission-mode-false-timing=cyclic-timing={time-offset=0, time-period=0.01}, transmission-mode-true-timing=cyclic-timing={time-offset=0, time-period=0.01}, unused-bit-pattern=0
            signal Checksum_094_oVCU_IBS_01_oATOM_CANFD_Matrix_CH_V600_202502: start 7, 8 bit, big-endian, i-signal-type=PRIMITIVE, init-value=0, base-type=uint8, compu-method=CM_Checksum_094, data-constr=DC_Checksum_094, transfer-property=PENDING  # Checksum signal for frame
            signal MessageCounter_094_oVCU_IBS_01_oATOM_CANFD_Matrix_CH_V600_202502: start 11, 4 bit, big-endian, i-signal-type=PRIMITIVE, init-value=0, base-type=uint8, compu-method=CM_MessageCounter_094, data-constr=DC_MessageCounter_094, transfer-property=PENDING  # Message counter signal for frame
            signal VCU_MotorActualTorqueValid_oVCU_IBS_01_oATOM_CANFD_Matrix_CH_V600_202502: start 14, 1 bit, big-endian, i-signal-type=PRIMITIVE, init-value=0, base-type=boolean, compu-method=CM_VCU_MotorActualTorqueValid, data-constr=DC_VCU_MotorActualTorqueValid, transfer-property=PENDING  # the actual torque of motor valid
            signal VCU_MotorActualTorque_oVCU_IBS_01_oATOM_CANFD_Matrix_CH_V600_202502: start 39, 11 bit, big-endian, i-signal-type=PRIMITIVE, init-value=0, base-type=uint16, compu-method=CM_VCU_MotorActualTorque, data-constr=DC_VCU_MotorActualTorque, transfer-property=PENDING  # the actual torque of motor
            signal VCU_WheelTrqACTValid_oVCU_IBS_01_oATOM_CANFD_Matrix_CH_V600_202502: start 40, 1 bit, big-endian, i-signal-type=PRIMITIVE, init-value=0, base-type=boolean, compu-method=CM_VCU_WheelTrqACTValid, data-constr=DC_VCU_WheelTrqACTValid, transfer-property=PENDING  # Actual motor torque on wheel valid
            signal VCU_OPStandstillReq_oVCU_IBS_01_oATOM_CANFD_Matrix_CH_V600_202502: start 42, 2 bit, big-endian, i-signal-type=PRIMITIVE, init-value=0, base-type=uint8, compu-method=CM_VCU_OPStandstillReq, data-constr=DC_VCU_OPStandstillReq, transfer-property=PENDING  # the requirement of standstill
            signal VCU_WheelTrqACT_oVCU_IBS_01_oATOM_CANFD_Matrix_CH_V600_202502: start 55, 16 bit, big-endian, i-signal-type=PRIMITIVE, init-value=0, base-type=uint16, compu-method=CM_VCU_WheelTrqACT, data-constr=DC_VCU_WheelTrqACT, unit=U_Nm, transfer-property=PENDING  # Actual motor torque on wheel
            mapping SG_VCU_IBS_01_SigGroup: i-signal-group=SG_VCU_IBS_01_SigGroup_oVCU_IBS_01_oATOM_CANFD_Matrix_CH_V600_202502, transfer-property=PENDING
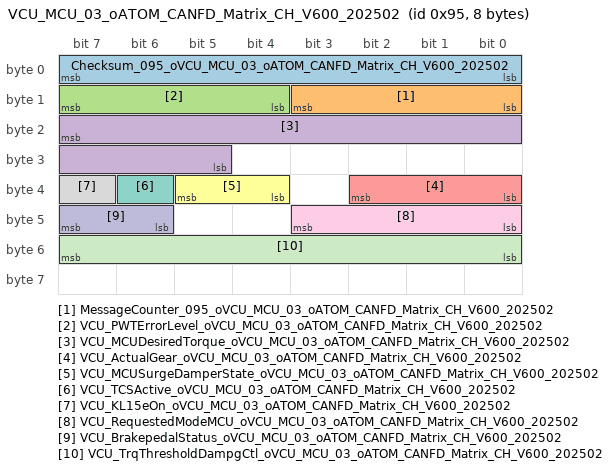
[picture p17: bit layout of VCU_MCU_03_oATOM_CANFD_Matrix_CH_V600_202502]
        frame VCU_MCU_03_oATOM_CANFD_Matrix_CH_V600_202502: id 0x95, from VCU, frame-length=8, can-addressing-mode=STANDARD, can-frame-rx-behavior=ANY, can-frame-tx-behavior=CAN-FD
          pdu VCU_MCU_03_oATOM_CANFD_Matrix_CH_V600_202502: length=8, minimum-delay=0, transmission-mode-false-timing=cyclic-timing={time-offset=0, time-period=0.01}, transmission-mode-true-timing=cyclic-timing={time-offset=0, time-period=0.01}, unused-bit-pattern=0
            signal Checksum_095_oVCU_MCU_03_oATOM_CANFD_Matrix_CH_V600_202502: start 7, 8 bit, big-endian, i-signal-type=PRIMITIVE, init-value=0, base-type=uint8, compu-method=CM_Checksum_095, data-constr=DC_Checksum_095, transfer-property=PENDING  # Checksum signal for frame
            signal MessageCounter_095_oVCU_MCU_03_oATOM_CANFD_Matrix_CH_V600_202502: start 11, 4 bit, big-endian, i-signal-type=PRIMITIVE, init-value=0, base-type=uint8, compu-method=CM_MessageCounter_095, data-constr=DC_MessageCounter_095, transfer-property=PENDING  # Message counter signal for frame
            signal VCU_PWTErrorLevel_oVCU_MCU_03_oATOM_CANFD_Matrix_CH_V600_202502: start 15, 4 bit, big-endian, i-signal-type=PRIMITIVE, init-value=0, base-type=uint8, compu-method=CM_VCU_PWTErrorLevel, data-constr=DC_VCU_PWTErrorLevel, transfer-property=PENDING  # Fault level of the power domain
            signal VCU_MCUDesiredTorque_oVCU_MCU_03_oATOM_CANFD_Matrix_CH_V600_202502: start 23, 11 bit, big-endian, i-signal-type=PRIMITIVE, init-value=0, base-type=uint16, compu-method=CM_VCU_MCUDesiredTorque, data-constr=DC_VCU_MCUDesiredTorque, unit=U_Nm, transfer-property=PENDING  # Desired torque electric machine
            signal VCU_ActualGear_oVCU_MCU_03_oATOM_CANFD_Matrix_CH_V600_202502: start 34, 3 bit, big-endian, i-signal-type=PRIMITIVE, init-value=0, base-type=uint8, compu-method=CM_VCU_ActualGear, data-constr=DC_VCU_ActualGear, transfer-property=PENDING  # The actual gear status
            signal VCU_MCUSurgeDamperState_oVCU_MCU_03_oATOM_CANFD_Matrix_CH_V600_202502: start 37, 2 bit, big-endian, i-signal-type=PRIMITIVE, init-value=0, base-type=uint8, compu-method=CM_VCU_MCUSurgeDamperState, data-constr=DC_VCU_MCUSurgeDamperState, unit=U_SED, transfer-property=PENDING  # Requested surge damper state
            signal VCU_TCSActive_oVCU_MCU_03_oATOM_CANFD_Matrix_CH_V600_202502: start 38, 1 bit, big-endian, i-signal-type=PRIMITIVE, init-value=0, base-type=boolean, compu-method=CM_VCU_TCSActive, data-constr=DC_VCU_TCSActive, transfer-property=PENDING  # EN: Tindicates TCS intervention active,TCS will detect spinning wheels and request torque reduction/limitation
            signal VCU_KL15eOn_oVCU_MCU_03_oATOM_CANFD_Matrix_CH_V600_202502: start 39, 1 bit, big-endian, i-signal-type=PRIMITIVE, init-value=0, base-type=boolean, compu-method=CM_VCU_KL15eOn, data-constr=DC_VCU_KL15eOn, transfer-property=PENDING  # the bit status of KL15e signal
            signal VCU_RequestedModeMCU_oVCU_MCU_03_oATOM_CANFD_Matrix_CH_V600_202502: start 43, 4 bit, big-endian, i-signal-type=PRIMITIVE, init-value=0, base-type=uint8, compu-method=CM_VCU_RequestedModeMCU, data-constr=DC_VCU_RequestedModeMCU, transfer-property=PENDING  # Request to the electric machine
            signal VCU_BrakepedalStatus_oVCU_MCU_03_oATOM_CANFD_Matrix_CH_V600_202502: start 47, 2 bit, big-endian, i-signal-type=PRIMITIVE, init-value=0, base-type=uint8, compu-method=CM_VCU_BrakepedalStatus, data-constr=DC_VCU_BrakepedalStatus, transfer-property=PENDING  # the break pedal status
            signal VCU_TrqThresholdDampgCtl_oVCU_MCU_03_oATOM_CANFD_Matrix_CH_V600_202502: start 55, 8 bit, big-endian, i-signal-type=PRIMITIVE, init-value=0, base-type=uint8, compu-method=CM_VCU_TrqThresholdDampgCtl, data-constr=DC_VCU_TrqThresholdDampgCtl, unit=U_Nm, transfer-property=PENDING  # Threshold torque for damping control
            mapping SG_VCU_MCU_03_SigGroup: i-signal-group=SG_VCU_MCU_03_SigGroup_oVCU_MCU_03_oATOM_CANFD_Matrix_CH_V600_202502, transfer-property=PENDING
        frame VCU_PlugInChrgInfo_oATOM_CANFD_Matrix_CH_V600_202502: id 0x391, from VCU, frame-length=8, can-addressing-mode=STANDARD, can-frame-rx-behavior=ANY, can-frame-tx-behavior=CAN-FD
          pdu VCU_PlugInChrgInfo_oATOM_CANFD_Matrix_CH_V600_202502: length=8, minimum-delay=0, transmission-mode-false-timing=cyclic-timing={time-offset=0, time-period=0.2}, transmission-mode-true-timing=cyclic-timing={time-offset=0, time-period=0.2}, unused-bit-pattern=0
            signal VCU_RemainChrgTime_oVCU_PlugInChrgInfo_oATOM_CANFD_Matrix_CH_V600_202502: start 7, 12 bit, big-endian, i-signal-type=PRIMITIVE, init-value=0, base-type=uint16, compu-method=CM_VCU_RemainChrgTime, data-constr=DC_VCU_RemainChrgTime, unit=U_min, transfer-property=PENDING  # Remaining charging time (displayed)
            signal VCU_DischargeEndReason_oVCU_PlugInChrgInfo_oATOM_CANFD_Matrix_CH_V600_202502: start 34, 2 bit, big-endian, i-signal-type=PRIMITIVE, init-value=0, base-type=uint8, compu-method=CM_VCU_DischargeEndReason, data-constr=DC_VCU_DischargeEndReason, transfer-property=PENDING  # Reason for stopping discharging
            signal VCU_ChargeEndReason_oVCU_PlugInChrgInfo_oATOM_CANFD_Matrix_CH_V600_202502: start 36, 2 bit, big-endian, i-signal-type=PRIMITIVE, init-value=0, base-type=uint8, compu-method=CM_VCU_ChargeEndReason, data-constr=DC_VCU_ChargeEndReason, transfer-property=PENDING  # Reason for stopping charging
            signal VCU_HVConnectFault_oVCU_PlugInChrgInfo_oATOM_CANFD_Matrix_CH_V600_202502: start 37, 1 bit, big-endian, i-signal-type=PRIMITIVE, init-value=0, base-type=boolean, compu-method=CM_VCU_HVConnectFault, data-constr=DC_VCU_HVConnectFault, transfer-property=PENDING  # Local high voltage failure prompt
            mapping SG_VCU_PlugInChrgInfo_SigGroup: i-signal-group=SG_VCU_PlugInChrgInfo_SigGroup_oVCU_PlugInChrgInfo_oATOM_CANFD_Matrix_CH_V600_202502, transfer-property=PENDING
    TC37X_VCU_CAN00: baudrate=500000  # VCU_CAN00
      can physical channel CHNL: comm-connectors=CN_TC37X_VCU_CAN00
        frame VCU_Rx_500h_NM_oTC37X_VCU_CAN00: id 0x500, to VCU, frame-length=8, can-addressing-mode=STANDARD
          nm pdu VCU_Rx_500h_NM_oTC37X_VCU_CAN00: length=8, unused-bit-pattern=0
        frame VCU_Tx_51Ch_NM_oTC37X_VCU_CAN00: id 0x51C, from VCU, frame-length=8, can-addressing-mode=STANDARD
          nm pdu VCU_Tx_51Ch_NM_oTC37X_VCU_CAN00: length=8, unused-bit-pattern=0
        frame Vcu_Uds_Func_Request_oTC37X_VCU_CAN00: id 0x700, to VCU, frame-length=8, can-addressing-mode=STANDARD
          n pdu Vcu_Uds_Func_Request_Tp_oTC37X_VCU_CAN00: length=8
        frame Vcu_Uds_Phy_Request_oTC37X_VCU_CAN00: id 0x701, to VCU, frame-length=8, can-addressing-mode=STANDARD
          n pdu Vcu_Uds_Phy_Request_Tp_oTC37X_VCU_CAN00: length=8
        frame Vcu_Uds_Response_oTC37X_VCU_CAN00: id 0x781, from VCU, frame-length=8, can-addressing-mode=STANDARD
          n pdu Vcu_Uds_Response_Tp_oTC37X_VCU_CAN00: length=8
        frame VcuRxMsg1_oTC37X_VCU_CAN00: id 0x200, to VCU, frame-length=8, can-addressing-mode=STANDARD
          pdu VcuRxMsg1_oTC37X_VCU_CAN00: length=8, minimum-delay=0, transmission-mode-false-timing=cyclic-timing={time-offset=0, time-period=0.5}, transmission-mode-true-timing=cyclic-timing={time-offset=0, time-period=0.5}, unused-bit-pattern=0
            signal VcuRxMsg1_Sig0_oVcuRxMsg1_oTC37X_VCU_CAN00: start 0, 16 bit, little-endian, i-signal-type=PRIMITIVE, init-value=0, base-type=sint16, compu-method=CM_VcuRxMsg1_Sig0, data-constr=DC_VcuRxMsg1_Sig0, transfer-property=PENDING, to VCU
            signal VcuRxMsg1_Sig1_oVcuRxMsg1_oTC37X_VCU_CAN00: start 16, 16 bit, little-endian, i-signal-type=PRIMITIVE, init-value=0, base-type=sint16, compu-method=CM_VcuRxMsg1_Sig1, data-constr=DC_VcuRxMsg1_Sig1, transfer-property=PENDING, to VCU
            signal VcuRxMsg1_Sig2_oVcuRxMsg1_oTC37X_VCU_CAN00: start 32, 16 bit, little-endian, i-signal-type=PRIMITIVE, init-value=0, base-type=sint16, compu-method=CM_VcuRxMsg1_Sig2, data-constr=DC_VcuRxMsg1_Sig2, transfer-property=PENDING, to VCU
            signal VcuRxMsg1_Sig3_oVcuRxMsg1_oTC37X_VCU_CAN00: start 48, 16 bit, little-endian, i-signal-type=PRIMITIVE, init-value=0, base-type=sint16, compu-method=CM_VcuRxMsg1_Sig3, data-constr=DC_VcuRxMsg1_Sig3, transfer-property=PENDING, to VCU
        frame VcuRxMsg2_oTC37X_VCU_CAN00: id 0x201, to VCU, frame-length=8, can-addressing-mode=STANDARD
          pdu VcuRxMsg2_oTC37X_VCU_CAN00: length=8, minimum-delay=0, transmission-mode-false-timing=cyclic-timing={time-offset=0, time-period=0.5}, transmission-mode-true-timing=cyclic-timing={time-offset=0, time-period=0.5}, unused-bit-pattern=0
            signal VcuRxMsg2_Sig0_oVcuRxMsg2_oTC37X_VCU_CAN00: start 0, 16 bit, little-endian, i-signal-type=PRIMITIVE, init-value=0, base-type=sint16, compu-method=CM_VcuRxMsg2_Sig0, data-constr=DC_VcuRxMsg2_Sig0, transfer-property=PENDING, to VCU
            signal VcuRxMsg2_Sig1_oVcuRxMsg2_oTC37X_VCU_CAN00: start 16, 16 bit, little-endian, i-signal-type=PRIMITIVE, init-value=0, base-type=sint16, compu-method=CM_VcuRxMsg2_Sig1, data-constr=DC_VcuRxMsg2_Sig1, transfer-property=PENDING, to VCU
            signal VcuRxMsg2_Sig2_oVcuRxMsg2_oTC37X_VCU_CAN00: start 32, 16 bit, little-endian, i-signal-type=PRIMITIVE, init-value=0, base-type=sint16, compu-method=CM_VcuRxMsg2_Sig2, data-constr=DC_VcuRxMsg2_Sig2, transfer-property=PENDING, to VCU
            signal VcuRxMsg2_Sig3_oVcuRxMsg2_oTC37X_VCU_CAN00: start 48, 16 bit, little-endian, i-signal-type=PRIMITIVE, init-value=0, base-type=sint16, compu-method=CM_VcuRxMsg2_Sig3, data-constr=DC_VcuRxMsg2_Sig3, transfer-property=PENDING, to VCU
        frame VcuTxIoMsg1_oTC37X_VCU_CAN00: id 0x104, from VCU, frame-length=8, can-addressing-mode=STANDARD
          pdu VcuTxIoMsg1_oTC37X_VCU_CAN00: length=8, minimum-delay=0, transmission-mode-false-timing=cyclic-timing={time-offset=0, time-period=0.5}, transmission-mode-true-timing=cyclic-timing={time-offset=0, time-period=0.5}, unused-bit-pattern=0
            signal EXT_A_IN1_oVcuTxIoMsg1_oTC37X_VCU_CAN00: start 0, 16 bit, little-endian, i-signal-type=PRIMITIVE, init-value=0, base-type=sint16, compu-method=CM_EXT_A_IN1, data-constr=DC_EXT_A_IN1, unit=U_C, transfer-property=PENDING
            signal EXT1_Valid_oVcuTxIoMsg1_oTC37X_VCU_CAN00: start 16, 16 bit, little-endian, i-signal-type=PRIMITIVE, init-value=0, base-type=uint16, compu-method=CM_EXT1_Valid, data-constr=DC_EXT1_Valid, transfer-property=PENDING
            signal EXT_A_IN2_oVcuTxIoMsg1_oTC37X_VCU_CAN00: start 32, 16 bit, little-endian, i-signal-type=PRIMITIVE, init-value=0, base-type=sint16, compu-method=CM_EXT_A_IN2, data-constr=DC_EXT_A_IN2, unit=U_C, transfer-property=PENDING
            signal EXT2_Valid_oVcuTxIoMsg1_oTC37X_VCU_CAN00: start 48, 16 bit, little-endian, i-signal-type=PRIMITIVE, init-value=0, base-type=uint16, compu-method=CM_EXT2_Valid, data-constr=DC_EXT2_Valid, transfer-property=PENDING
        frame VcuTxIoMsg2_oTC37X_VCU_CAN00: id 0x105, from VCU, frame-length=8, can-addressing-mode=STANDARD
          pdu VcuTxIoMsg2_oTC37X_VCU_CAN00: length=8, minimum-delay=0, transmission-mode-false-timing=cyclic-timing={time-offset=0, time-period=0.5}, transmission-mode-true-timing=cyclic-timing={time-offset=0, time-period=0.5}, unused-bit-pattern=0
            signal EXT_A_IN3_oVcuTxIoMsg2_oTC37X_VCU_CAN00: start 0, 16 bit, little-endian, i-signal-type=PRIMITIVE, init-value=0, base-type=sint16, compu-method=CM_EXT_A_IN3, data-constr=DC_EXT_A_IN3, unit=U_C, transfer-property=PENDING
            signal EXT3_Valid_oVcuTxIoMsg2_oTC37X_VCU_CAN00: start 16, 16 bit, little-endian, i-signal-type=PRIMITIVE, init-value=0, base-type=uint16, compu-method=CM_EXT3_Valid, data-constr=DC_EXT3_Valid, transfer-property=PENDING
            signal EXT_A_IN4_oVcuTxIoMsg2_oTC37X_VCU_CAN00: start 32, 16 bit, little-endian, i-signal-type=PRIMITIVE, init-value=0, base-type=sint16, compu-method=CM_EXT_A_IN4, data-constr=DC_EXT_A_IN4, unit=U_C, transfer-property=PENDING
            signal EXT4_Valid_oVcuTxIoMsg2_oTC37X_VCU_CAN00: start 48, 16 bit, little-endian, i-signal-type=PRIMITIVE, init-value=0, base-type=uint16, compu-method=CM_EXT4_Valid, data-constr=DC_EXT4_Valid, transfer-property=PENDING
        frame VcuTxIoMsg3_oTC37X_VCU_CAN00: id 0x106, from VCU, frame-length=8, can-addressing-mode=STANDARD
          pdu VcuTxIoMsg3_oTC37X_VCU_CAN00: length=8, minimum-delay=0, transmission-mode-false-timing=cyclic-timing={time-offset=0, time-period=0.5}, transmission-mode-true-timing=cyclic-timing={time-offset=0, time-period=0.5}, unused-bit-pattern=0
            signal EXT_A_IN5_oVcuTxIoMsg3_oTC37X_VCU_CAN00: start 0, 16 bit, little-endian, i-signal-type=PRIMITIVE, init-value=0, base-type=sint16, compu-method=CM_EXT_A_IN5, data-constr=DC_EXT_A_IN5, unit=U_C, transfer-property=PENDING
            signal EXT5_Valid_oVcuTxIoMsg3_oTC37X_VCU_CAN00: start 16, 16 bit, little-endian, i-signal-type=PRIMITIVE, init-value=0, base-type=uint16, compu-method=CM_EXT5_Valid, data-constr=DC_EXT5_Valid, transfer-property=PENDING
            signal EXT_A_IN6_oVcuTxIoMsg3_oTC37X_VCU_CAN00: start 32, 16 bit, little-endian, i-signal-type=PRIMITIVE, init-value=0, base-type=sint16, compu-method=CM_EXT_A_IN6, data-constr=DC_EXT_A_IN6, unit=U_C, transfer-property=PENDING
            signal EXT6_Valid_oVcuTxIoMsg3_oTC37X_VCU_CAN00: start 48, 16 bit, little-endian, i-signal-type=PRIMITIVE, init-value=0, base-type=uint16, compu-method=CM_EXT6_Valid, data-constr=DC_EXT6_Valid, transfer-property=PENDING
        frame VcuTxIoMsg4_oTC37X_VCU_CAN00: id 0x107, from VCU, frame-length=8, can-addressing-mode=STANDARD
          pdu VcuTxIoMsg4_oTC37X_VCU_CAN00: length=8, minimum-delay=0, transmission-mode-false-timing=cyclic-timing={time-offset=0, time-period=0.5}, transmission-mode-true-timing=cyclic-timing={time-offset=0, time-period=0.5}, unused-bit-pattern=0
            signal EXT_A_IN7_oVcuTxIoMsg4_oTC37X_VCU_CAN00: start 0, 16 bit, little-endian, i-signal-type=PRIMITIVE, init-value=0, base-type=sint16, compu-method=CM_EXT_A_IN7, data-constr=DC_EXT_A_IN7, unit=U_C, transfer-property=PENDING
            signal EXT7_Valid_oVcuTxIoMsg4_oTC37X_VCU_CAN00: start 16, 16 bit, little-endian, i-signal-type=PRIMITIVE, init-value=0, base-type=uint16, compu-method=CM_EXT7_Valid, data-constr=DC_EXT7_Valid, transfer-property=PENDING
            signal EXT_A_IN8_oVcuTxIoMsg4_oTC37X_VCU_CAN00: start 32, 16 bit, little-endian, i-signal-type=PRIMITIVE, init-value=0, base-type=sint16, compu-method=CM_EXT_A_IN8, data-constr=DC_EXT_A_IN8, unit=U_C, transfer-property=PENDING
            signal EXT8_Valid_oVcuTxIoMsg4_oTC37X_VCU_CAN00: start 48, 16 bit, little-endian, i-signal-type=PRIMITIVE, init-value=0, base-type=uint16, compu-method=CM_EXT8_Valid, data-constr=DC_EXT8_Valid, transfer-property=PENDING
        frame VcuTxIoMsg5_oTC37X_VCU_CAN00: id 0x108, from VCU, frame-length=8, can-addressing-mode=STANDARD
          pdu VcuTxIoMsg5_oTC37X_VCU_CAN00: length=8, minimum-delay=0, transmission-mode-false-timing=cyclic-timing={time-offset=0, time-period=0.5}, transmission-mode-true-timing=cyclic-timing={time-offset=0, time-period=0.5}, unused-bit-pattern=0
            signal EXT_A_IN9_oVcuTxIoMsg5_oTC37X_VCU_CAN00: start 0, 16 bit, little-endian, i-signal-type=PRIMITIVE, init-value=0, base-type=sint16, compu-method=CM_EXT_A_IN9, data-constr=DC_EXT_A_IN9, unit=U_C, transfer-property=PENDING
            signal EXT9_Valid_oVcuTxIoMsg5_oTC37X_VCU_CAN00: start 16, 16 bit, little-endian, i-signal-type=PRIMITIVE, init-value=0, base-type=uint16, compu-method=CM_EXT9_Valid, data-constr=DC_EXT9_Valid, transfer-property=PENDING
            signal EXT_A_IN10_oVcuTxIoMsg5_oTC37X_VCU_CAN00: start 32, 16 bit, little-endian, i-signal-type=PRIMITIVE, init-value=0, base-type=sint16, compu-method=CM_EXT_A_IN10, data-constr=DC_EXT_A_IN10, unit=U_C, transfer-property=PENDING
            signal EXT10_Valid_oVcuTxIoMsg5_oTC37X_VCU_CAN00: start 48, 16 bit, little-endian, i-signal-type=PRIMITIVE, init-value=0, base-type=uint16, compu-method=CM_EXT10_Valid, data-constr=DC_EXT10_Valid, transfer-property=PENDING
        frame VcuTxIoMsg6_oTC37X_VCU_CAN00: id 0x109, from VCU, frame-length=8, can-addressing-mode=STANDARD
          pdu VcuTxIoMsg6_oTC37X_VCU_CAN00: length=8, minimum-delay=0, transmission-mode-false-timing=cyclic-timing={time-offset=0, time-period=0.5}, transmission-mode-true-timing=cyclic-timing={time-offset=0, time-period=0.5}, unused-bit-pattern=0
            signal EXT_A_IN11_oVcuTxIoMsg6_oTC37X_VCU_CAN00: start 0, 16 bit, little-endian, i-signal-type=PRIMITIVE, init-value=0, base-type=sint16, compu-method=CM_EXT_A_IN11, data-constr=DC_EXT_A_IN11, unit=U_C, transfer-property=PENDING
            signal EXT11_Valid_oVcuTxIoMsg6_oTC37X_VCU_CAN00: start 16, 16 bit, little-endian, i-signal-type=PRIMITIVE, init-value=0, base-type=uint16, compu-method=CM_EXT11_Valid, data-constr=DC_EXT11_Valid, transfer-property=PENDING
            signal EXT_A_IN12_oVcuTxIoMsg6_oTC37X_VCU_CAN00: start 32, 16 bit, little-endian, i-signal-type=PRIMITIVE, init-value=0, base-type=sint16, compu-method=CM_EXT_A_IN12, data-constr=DC_EXT_A_IN12, unit=U_C, transfer-property=PENDING
            signal EXT12_Valid_oVcuTxIoMsg6_oTC37X_VCU_CAN00: start 48, 16 bit, little-endian, i-signal-type=PRIMITIVE, init-value=0, base-type=uint16, compu-method=CM_EXT12_Valid, data-constr=DC_EXT12_Valid, transfer-property=PENDING
        frame VcuTxIoMsg7_oTC37X_VCU_CAN00: id 0x10A, from VCU, frame-length=8, can-addressing-mode=STANDARD
          pdu VcuTxIoMsg7_oTC37X_VCU_CAN00: length=8, minimum-delay=0, transmission-mode-false-timing=cyclic-timing={time-offset=0, time-period=0.5}, transmission-mode-true-timing=cyclic-timing={time-offset=0, time-period=0.5}, unused-bit-pattern=0
            signal EXT_A_IN13_oVcuTxIoMsg7_oTC37X_VCU_CAN00: start 0, 16 bit, little-endian, i-signal-type=PRIMITIVE, init-value=0, base-type=sint16, compu-method=CM_EXT_A_IN13, data-constr=DC_EXT_A_IN13, unit=U_C, transfer-property=PENDING
            signal EXT13_Valid_oVcuTxIoMsg7_oTC37X_VCU_CAN00: start 16, 16 bit, little-endian, i-signal-type=PRIMITIVE, init-value=0, base-type=uint16, compu-method=CM_EXT13_Valid, data-constr=DC_EXT13_Valid, transfer-property=PENDING
            signal EXT_A_IN14_oVcuTxIoMsg7_oTC37X_VCU_CAN00: start 32, 16 bit, little-endian, i-signal-type=PRIMITIVE, init-value=0, base-type=sint16, compu-method=CM_EXT_A_IN14, data-constr=DC_EXT_A_IN14, unit=U_C, transfer-property=PENDING
            signal EXT14_Valid_oVcuTxIoMsg7_oTC37X_VCU_CAN00: start 48, 16 bit, little-endian, i-signal-type=PRIMITIVE, init-value=0, base-type=uint16, compu-method=CM_EXT14_Valid, data-constr=DC_EXT14_Valid, transfer-property=PENDING
        frame VcuTxIoMsg8_oTC37X_VCU_CAN00: id 0x10B, from VCU, frame-length=8, can-addressing-mode=STANDARD
          pdu VcuTxIoMsg8_oTC37X_VCU_CAN00: length=8, minimum-delay=0, transmission-mode-false-timing=cyclic-timing={time-offset=0, time-period=0.5}, transmission-mode-true-timing=cyclic-timing={time-offset=0, time-period=0.5}, unused-bit-pattern=0
            signal EXT_A_IN15_oVcuTxIoMsg8_oTC37X_VCU_CAN00: start 0, 16 bit, little-endian, i-signal-type=PRIMITIVE, init-value=0, base-type=sint16, compu-method=CM_EXT_A_IN15, data-constr=DC_EXT_A_IN15, unit=U_C, transfer-property=PENDING
            signal EXT15_Valid_oVcuTxIoMsg8_oTC37X_VCU_CAN00: start 16, 16 bit, little-endian, i-signal-type=PRIMITIVE, init-value=0, base-type=uint16, compu-method=CM_EXT15_Valid, data-constr=DC_EXT15_Valid, transfer-property=PENDING
            signal EXT_A_IN16_oVcuTxIoMsg8_oTC37X_VCU_CAN00: start 32, 16 bit, little-endian, i-signal-type=PRIMITIVE, init-value=0, base-type=sint16, compu-method=CM_EXT_A_IN16, data-constr=DC_EXT_A_IN16, unit=U_C, transfer-property=PENDING
            signal EXT16_Valid_oVcuTxIoMsg8_oTC37X_VCU_CAN00: start 48, 16 bit, little-endian, i-signal-type=PRIMITIVE, init-value=0, base-type=uint16, compu-method=CM_EXT16_Valid, data-constr=DC_EXT16_Valid, transfer-property=PENDING
        frame VcuTxMsg1_oTC37X_VCU_CAN00: id 0x100, from VCU, frame-length=8, can-addressing-mode=STANDARD
          pdu VcuTxMsg1_oTC37X_VCU_CAN00: length=8, minimum-delay=0, transmission-mode-false-timing=cyclic-timing={time-offset=0, time-period=0.5}, transmission-mode-true-timing=cyclic-timing={time-offset=0, time-period=0.5}, unused-bit-pattern=0
            signal VcuTxMsg1_Sig0_oVcuTxMsg1_oTC37X_VCU_CAN00: start 0, 16 bit, little-endian, i-signal-type=PRIMITIVE, init-value=0, base-type=sint16, compu-method=CM_VcuTxMsg1_Sig0, data-constr=DC_VcuTxMsg1_Sig0, transfer-property=PENDING
            signal VcuTxMsg1_Sig1_oVcuTxMsg1_oTC37X_VCU_CAN00: start 16, 16 bit, little-endian, i-signal-type=PRIMITIVE, init-value=0, base-type=sint16, compu-method=CM_VcuTxMsg1_Sig1, data-constr=DC_VcuTxMsg1_Sig1, transfer-property=PENDING
            signal VcuTxMsg1_Sig2_oVcuTxMsg1_oTC37X_VCU_CAN00: start 32, 16 bit, little-endian, i-signal-type=PRIMITIVE, init-value=0, base-type=sint16, compu-method=CM_VcuTxMsg1_Sig2, data-constr=DC_VcuTxMsg1_Sig2, transfer-property=PENDING
            signal VcuTxMsg1_Sig3_oVcuTxMsg1_oTC37X_VCU_CAN00: start 48, 16 bit, little-endian, i-signal-type=PRIMITIVE, init-value=0, base-type=sint16, compu-method=CM_VcuTxMsg1_Sig3, data-constr=DC_VcuTxMsg1_Sig3, transfer-property=PENDING
        frame VcuTxMsg2_oTC37X_VCU_CAN00: id 0x101, from VCU, frame-length=8, can-addressing-mode=STANDARD
          pdu VcuTxMsg2_oTC37X_VCU_CAN00: length=8, minimum-delay=0, transmission-mode-false-timing=cyclic-timing={time-offset=0, time-period=0.5}, transmission-mode-true-timing=cyclic-timing={time-offset=0, time-period=0.5}, unused-bit-pattern=0
            signal VcuTxMsg2_Sig0_oVcuTxMsg2_oTC37X_VCU_CAN00: start 0, 16 bit, little-endian, i-signal-type=PRIMITIVE, init-value=0, base-type=sint16, compu-method=CM_VcuTxMsg2_Sig0, data-constr=DC_VcuTxMsg2_Sig0, transfer-property=PENDING
            signal VcuTxMsg2_Sig1_oVcuTxMsg2_oTC37X_VCU_CAN00: start 16, 16 bit, little-endian, i-signal-type=PRIMITIVE, init-value=0, base-type=sint16, compu-method=CM_VcuTxMsg2_Sig1, data-constr=DC_VcuTxMsg2_Sig1, transfer-property=PENDING
            signal VcuTxMsg2_Sig2_oVcuTxMsg2_oTC37X_VCU_CAN00: start 32, 16 bit, little-endian, i-signal-type=PRIMITIVE, init-value=0, base-type=sint16, compu-method=CM_VcuTxMsg2_Sig2, data-constr=DC_VcuTxMsg2_Sig2, transfer-property=PENDING
            signal VcuTxMsg2_Sig3_oVcuTxMsg2_oTC37X_VCU_CAN00: start 48, 16 bit, little-endian, i-signal-type=PRIMITIVE, init-value=0, base-type=sint16, compu-method=CM_VcuTxMsg2_Sig3, data-constr=DC_VcuTxMsg2_Sig3, transfer-property=PENDING
        frame XCP_Request_oTC37X_VCU_CAN00: id 0x606, to VCU, frame-length=8, can-addressing-mode=STANDARD
          xcp pdu XCP_Request_oTC37X_VCU_CAN00: length=8
        frame XCP_Response_oTC37X_VCU_CAN00: id 0x607, from VCU, frame-length=8, can-addressing-mode=STANDARD
          xcp pdu XCP_Response_oTC37X_VCU_CAN00: length=8
        pdu triggering PT_Vcu_Uds_Func_Request: pdu=Vcu_Uds_Func_Request_oTC37X_VCU_CAN00, to VCU
        pdu triggering PT_Vcu_Uds_Phy_Request: pdu=Vcu_Uds_Phy_Request_oTC37X_VCU_CAN00, to VCU
        pdu triggering PT_Vcu_Uds_Response: pdu=Vcu_Uds_Response_oTC37X_VCU_CAN00, from VCU
    TC37X_VCU_CAN01: baudrate=500000  # VCU_CAN01
      can physical channel CHNL: comm-connectors=CN_TC37X_VCU_CAN01
        frame VCU_Rx_500h_NM_oTC37X_VCU_CAN01: id 0x500, to VCU, frame-length=8, can-addressing-mode=STANDARD
          nm pdu VCU_Rx_500h_NM_oTC37X_VCU_CAN01: length=8, unused-bit-pattern=0
        frame VCU_Tx_51Ch_NM_oTC37X_VCU_CAN01: id 0x51C, from VCU, frame-length=8, can-addressing-mode=STANDARD
          nm pdu VCU_Tx_51Ch_NM_oTC37X_VCU_CAN01: length=8, unused-bit-pattern=0
        frame VcuAdcTxG0Msg0_oTC37X_VCU_CAN01: id 0x102, from VCU, frame-length=8, can-addressing-mode=STANDARD
          pdu VcuAdcTxG0Msg0_oTC37X_VCU_CAN01: length=8, minimum-delay=0, transmission-mode-false-timing=cyclic-timing={time-offset=0, time-period=0.5}, transmission-mode-true-timing=cyclic-timing={time-offset=0, time-period=0.5}, unused-bit-pattern=0
            signal AN0_oVcuAdcTxG0Msg0_oTC37X_VCU_CAN01: start 0, 16 bit, little-endian, i-signal-type=PRIMITIVE, init-value=0, base-type=sint16, compu-method=CM_AN0, data-constr=DC_AN0, unit=U_mV, transfer-property=PENDING
            signal AN1_oVcuAdcTxG0Msg0_oTC37X_VCU_CAN01: start 16, 16 bit, little-endian, i-signal-type=PRIMITIVE, init-value=0, base-type=sint16, compu-method=CM_AN1, data-constr=DC_AN1, unit=U_mV, transfer-property=PENDING
            signal AN2_oVcuAdcTxG0Msg0_oTC37X_VCU_CAN01: start 32, 16 bit, little-endian, i-signal-type=PRIMITIVE, init-value=0, base-type=sint16, compu-method=CM_AN2, data-constr=DC_AN2, unit=U_mV, transfer-property=PENDING
            signal AN3_oVcuAdcTxG0Msg0_oTC37X_VCU_CAN01: start 48, 16 bit, little-endian, i-signal-type=PRIMITIVE, init-value=0, base-type=sint16, compu-method=CM_AN3, data-constr=DC_AN3, unit=U_mV, transfer-property=PENDING
        frame VcuAdcTxG0Msg1_oTC37X_VCU_CAN01: id 0x103, from VCU, frame-length=8, can-addressing-mode=STANDARD
          pdu VcuAdcTxG0Msg1_oTC37X_VCU_CAN01: length=8, minimum-delay=0, transmission-mode-false-timing=cyclic-timing={time-offset=0, time-period=0.5}, transmission-mode-true-timing=cyclic-timing={time-offset=0, time-period=0.5}, unused-bit-pattern=0
            signal AN4_oVcuAdcTxG0Msg1_oTC37X_VCU_CAN01: start 0, 16 bit, little-endian, i-signal-type=PRIMITIVE, init-value=0, base-type=sint16, compu-method=CM_AN4, data-constr=DC_AN4, unit=U_mV, transfer-property=PENDING
            signal AN5_oVcuAdcTxG0Msg1_oTC37X_VCU_CAN01: start 16, 16 bit, little-endian, i-signal-type=PRIMITIVE, init-value=0, base-type=sint16, compu-method=CM_AN5, data-constr=DC_AN5, unit=U_mV, transfer-property=PENDING
            signal AN6_oVcuAdcTxG0Msg1_oTC37X_VCU_CAN01: start 32, 16 bit, little-endian, i-signal-type=PRIMITIVE, init-value=0, base-type=sint16, compu-method=CM_AN6, data-constr=DC_AN6, unit=U_mV, transfer-property=PENDING
            signal AN7_oVcuAdcTxG0Msg1_oTC37X_VCU_CAN01: start 48, 16 bit, little-endian, i-signal-type=PRIMITIVE, init-value=0, base-type=sint16, compu-method=CM_AN7, data-constr=DC_AN7, unit=U_mV, transfer-property=PENDING
        frame VcuAdcTxG1Msg0_oTC37X_VCU_CAN01: id 0x104, from VCU, frame-length=8, can-addressing-mode=STANDARD
          pdu VcuAdcTxG1Msg0_oTC37X_VCU_CAN01: length=8, minimum-delay=0, transmission-mode-false-timing=cyclic-timing={time-offset=0, time-period=0.5}, transmission-mode-true-timing=cyclic-timing={time-offset=0, time-period=0.5}, unused-bit-pattern=0
            signal AN8_oVcuAdcTxG1Msg0_oTC37X_VCU_CAN01: start 0, 16 bit, little-endian, i-signal-type=PRIMITIVE, init-value=0, base-type=sint16, compu-method=CM_AN8, data-constr=DC_AN8, unit=U_mV, transfer-property=PENDING
            signal AN9_oVcuAdcTxG1Msg0_oTC37X_VCU_CAN01: start 16, 16 bit, little-endian, i-signal-type=PRIMITIVE, init-value=0, base-type=sint16, compu-method=CM_AN9, data-constr=DC_AN9, unit=U_mV, transfer-property=PENDING
            signal AN10_oVcuAdcTxG1Msg0_oTC37X_VCU_CAN01: start 32, 16 bit, little-endian, i-signal-type=PRIMITIVE, init-value=0, base-type=sint16, compu-method=CM_AN10, data-constr=DC_AN10, unit=U_mV, transfer-property=PENDING
            signal AN11_oVcuAdcTxG1Msg0_oTC37X_VCU_CAN01: start 48, 16 bit, little-endian, i-signal-type=PRIMITIVE, init-value=0, base-type=sint16, compu-method=CM_AN11, data-constr=DC_AN11, unit=U_mV, transfer-property=PENDING
        frame VcuAdcTxG1Msg1_oTC37X_VCU_CAN01: id 0x105, from VCU, frame-length=8, can-addressing-mode=STANDARD
          pdu VcuAdcTxG1Msg1_oTC37X_VCU_CAN01: length=8, minimum-delay=0, transmission-mode-false-timing=cyclic-timing={time-offset=0, time-period=0.5}, transmission-mode-true-timing=cyclic-timing={time-offset=0, time-period=0.5}, unused-bit-pattern=0
            signal AN12_oVcuAdcTxG1Msg1_oTC37X_VCU_CAN01: start 0, 16 bit, little-endian, i-signal-type=PRIMITIVE, init-value=0, base-type=sint16, compu-method=CM_AN12, data-constr=DC_AN12, unit=U_mV, transfer-property=PENDING
            signal AN13_oVcuAdcTxG1Msg1_oTC37X_VCU_CAN01: start 16, 16 bit, little-endian, i-signal-type=PRIMITIVE, init-value=0, base-type=sint16, compu-method=CM_AN13, data-constr=DC_AN13, unit=U_mV, transfer-property=PENDING
            signal AN14_oVcuAdcTxG1Msg1_oTC37X_VCU_CAN01: start 32, 16 bit, little-endian, i-signal-type=PRIMITIVE, init-value=0, base-type=sint16, compu-method=CM_AN14, data-constr=DC_AN14, unit=U_mV, transfer-property=PENDING
            signal AN15_oVcuAdcTxG1Msg1_oTC37X_VCU_CAN01: start 48, 16 bit, little-endian, i-signal-type=PRIMITIVE, init-value=0, base-type=sint16, compu-method=CM_AN15, data-constr=DC_AN15, unit=U_mV, transfer-property=PENDING
        frame VcuAdcTxG2Msg0_oTC37X_VCU_CAN01: id 0x106, from VCU, frame-length=8, can-addressing-mode=STANDARD
          pdu VcuAdcTxG2Msg0_oTC37X_VCU_CAN01: length=8, minimum-delay=0, transmission-mode-false-timing=cyclic-timing={time-offset=0, time-period=0.5}, transmission-mode-true-timing=cyclic-timing={time-offset=0, time-period=0.5}, unused-bit-pattern=0
            signal AN16_oVcuAdcTxG2Msg0_oTC37X_VCU_CAN01: start 0, 16 bit, little-endian, i-signal-type=PRIMITIVE, init-value=0, base-type=sint16, compu-method=CM_AN16, data-constr=DC_AN16, unit=U_mV, transfer-property=PENDING
            signal AN17_oVcuAdcTxG2Msg0_oTC37X_VCU_CAN01: start 16, 16 bit, little-endian, i-signal-type=PRIMITIVE, init-value=0, base-type=sint16, compu-method=CM_AN17, data-constr=DC_AN17, unit=U_mV, transfer-property=PENDING
            signal AN18_oVcuAdcTxG2Msg0_oTC37X_VCU_CAN01: start 32, 16 bit, little-endian, i-signal-type=PRIMITIVE, init-value=0, base-type=sint16, compu-method=CM_AN18, data-constr=DC_AN18, unit=U_mV, transfer-property=PENDING
            signal AN19_oVcuAdcTxG2Msg0_oTC37X_VCU_CAN01: start 48, 16 bit, little-endian, i-signal-type=PRIMITIVE, init-value=0, base-type=sint16, compu-method=CM_AN19, data-constr=DC_AN19, unit=U_mV, transfer-property=PENDING
        frame VcuAdcTxG2Msg1_oTC37X_VCU_CAN01: id 0x107, from VCU, frame-length=8, can-addressing-mode=STANDARD
          pdu VcuAdcTxG2Msg1_oTC37X_VCU_CAN01: length=8, minimum-delay=0, transmission-mode-false-timing=cyclic-timing={time-offset=0, time-period=0.5}, transmission-mode-true-timing=cyclic-timing={time-offset=0, time-period=0.5}, unused-bit-pattern=0
            signal AN20_oVcuAdcTxG2Msg1_oTC37X_VCU_CAN01: start 0, 16 bit, little-endian, i-signal-type=PRIMITIVE, init-value=0, base-type=sint16, compu-method=CM_AN20, data-constr=DC_AN20, unit=U_mV, transfer-property=PENDING
            signal AN21_oVcuAdcTxG2Msg1_oTC37X_VCU_CAN01: start 16, 16 bit, little-endian, i-signal-type=PRIMITIVE, init-value=0, base-type=sint16, compu-method=CM_AN21, data-constr=DC_AN21, unit=U_mV, transfer-property=PENDING
            signal AN22_oVcuAdcTxG2Msg1_oTC37X_VCU_CAN01: start 32, 16 bit, little-endian, i-signal-type=PRIMITIVE, init-value=0, base-type=sint16, compu-method=CM_AN22, data-constr=DC_AN22, unit=U_mV, transfer-property=PENDING
            signal AN23_oVcuAdcTxG2Msg1_oTC37X_VCU_CAN01: start 48, 16 bit, little-endian, i-signal-type=PRIMITIVE, init-value=0, base-type=sint16, compu-method=CM_AN23, data-constr=DC_AN23, unit=U_mV, transfer-property=PENDING
        frame VcuAdcTxG3Msg0_oTC37X_VCU_CAN01: id 0x108, from VCU, frame-length=8, can-addressing-mode=STANDARD
          pdu VcuAdcTxG3Msg0_oTC37X_VCU_CAN01: length=8, minimum-delay=0, transmission-mode-false-timing=cyclic-timing={time-offset=0, time-period=0.5}, transmission-mode-true-timing=cyclic-timing={time-offset=0, time-period=0.5}, unused-bit-pattern=0
            signal AN24_oVcuAdcTxG3Msg0_oTC37X_VCU_CAN01: start 0, 16 bit, little-endian, i-signal-type=PRIMITIVE, init-value=0, base-type=sint16, compu-method=CM_AN24, data-constr=DC_AN24, unit=U_mV, transfer-property=PENDING
            signal AN25_oVcuAdcTxG3Msg0_oTC37X_VCU_CAN01: start 16, 16 bit, little-endian, i-signal-type=PRIMITIVE, init-value=0, base-type=sint16, compu-method=CM_AN25, data-constr=DC_AN25, unit=U_mV, transfer-property=PENDING
            signal AN26_oVcuAdcTxG3Msg0_oTC37X_VCU_CAN01: start 32, 16 bit, little-endian, i-signal-type=PRIMITIVE, init-value=0, base-type=sint16, compu-method=CM_AN26, data-constr=DC_AN26, unit=U_mV, transfer-property=PENDING
            signal AN27_oVcuAdcTxG3Msg0_oTC37X_VCU_CAN01: start 48, 16 bit, little-endian, i-signal-type=PRIMITIVE, init-value=0, base-type=sint16, compu-method=CM_AN27, data-constr=DC_AN27, unit=U_mV, transfer-property=PENDING
        frame VcuAdcTxG3Msg1_oTC37X_VCU_CAN01: id 0x109, from VCU, frame-length=8, can-addressing-mode=STANDARD
          pdu VcuAdcTxG3Msg1_oTC37X_VCU_CAN01: length=8, minimum-delay=0, transmission-mode-false-timing=cyclic-timing={time-offset=0, time-period=0.5}, transmission-mode-true-timing=cyclic-timing={time-offset=0, time-period=0.5}, unused-bit-pattern=0
            signal AN28_oVcuAdcTxG3Msg1_oTC37X_VCU_CAN01: start 0, 16 bit, little-endian, i-signal-type=PRIMITIVE, init-value=0, base-type=sint16, compu-method=CM_AN28, data-constr=DC_AN28, unit=U_mV, transfer-property=PENDING
            signal AN29_oVcuAdcTxG3Msg1_oTC37X_VCU_CAN01: start 16, 16 bit, little-endian, i-signal-type=PRIMITIVE, init-value=0, base-type=sint16, compu-method=CM_AN29, data-constr=DC_AN29, unit=U_mV, transfer-property=PENDING
            signal AN30_oVcuAdcTxG3Msg1_oTC37X_VCU_CAN01: start 32, 16 bit, little-endian, i-signal-type=PRIMITIVE, init-value=0, base-type=sint16, compu-method=CM_AN30, data-constr=DC_AN30, unit=U_mV, transfer-property=PENDING
            signal AN31_oVcuAdcTxG3Msg1_oTC37X_VCU_CAN01: start 48, 16 bit, little-endian, i-signal-type=PRIMITIVE, init-value=0, base-type=sint16, compu-method=CM_AN31, data-constr=DC_AN31, unit=U_mV, transfer-property=PENDING
        frame VcuAdcTxG8Msg0_oTC37X_VCU_CAN01: id 0x10A, from VCU, frame-length=8, can-addressing-mode=STANDARD
          pdu VcuAdcTxG8Msg0_oTC37X_VCU_CAN01: length=8, minimum-delay=0, transmission-mode-false-timing=cyclic-timing={time-offset=0, time-period=0.5}, transmission-mode-true-timing=cyclic-timing={time-offset=0, time-period=0.5}, unused-bit-pattern=0
            signal AN32_oVcuAdcTxG8Msg0_oTC37X_VCU_CAN01: start 0, 16 bit, little-endian, i-signal-type=PRIMITIVE, init-value=0, base-type=sint16, compu-method=CM_AN32, data-constr=DC_AN32, unit=U_mV, transfer-property=PENDING
            signal AN33_oVcuAdcTxG8Msg0_oTC37X_VCU_CAN01: start 16, 16 bit, little-endian, i-signal-type=PRIMITIVE, init-value=0, base-type=sint16, compu-method=CM_AN33, data-constr=DC_AN33, unit=U_mV, transfer-property=PENDING
            signal AN34_oVcuAdcTxG8Msg0_oTC37X_VCU_CAN01: start 32, 16 bit, little-endian, i-signal-type=PRIMITIVE, init-value=0, base-type=sint16, compu-method=CM_AN34, data-constr=DC_AN34, unit=U_mV, transfer-property=PENDING
            signal AN35_oVcuAdcTxG8Msg0_oTC37X_VCU_CAN01: start 48, 16 bit, little-endian, i-signal-type=PRIMITIVE, init-value=0, base-type=sint16, compu-method=CM_AN35, data-constr=DC_AN35, unit=U_mV, transfer-property=PENDING
        frame VcuAdcTxG8Msg1_oTC37X_VCU_CAN01: id 0x10B, from VCU, frame-length=8, can-addressing-mode=STANDARD
          pdu VcuAdcTxG8Msg1_oTC37X_VCU_CAN01: length=8, minimum-delay=0, transmission-mode-false-timing=cyclic-timing={time-offset=0, time-period=0.5}, transmission-mode-true-timing=cyclic-timing={time-offset=0, time-period=0.5}, unused-bit-pattern=0
            signal AN36_oVcuAdcTxG8Msg1_oTC37X_VCU_CAN01: start 0, 16 bit, little-endian, i-signal-type=PRIMITIVE, init-value=0, base-type=sint16, compu-method=CM_AN36, data-constr=DC_AN36, unit=U_mV, transfer-property=PENDING
            signal AN37_oVcuAdcTxG8Msg1_oTC37X_VCU_CAN01: start 16, 16 bit, little-endian, i-signal-type=PRIMITIVE, init-value=0, base-type=sint16, compu-method=CM_AN37, data-constr=DC_AN37, unit=U_mV, transfer-property=PENDING
            signal AN38_oVcuAdcTxG8Msg1_oTC37X_VCU_CAN01: start 32, 16 bit, little-endian, i-signal-type=PRIMITIVE, init-value=0, base-type=sint16, compu-method=CM_AN38, data-constr=DC_AN38, unit=U_mV, transfer-property=PENDING
            signal AN39_oVcuAdcTxG8Msg1_oTC37X_VCU_CAN01: start 48, 16 bit, little-endian, i-signal-type=PRIMITIVE, init-value=0, base-type=sint16, compu-method=CM_AN39, data-constr=DC_AN39, unit=U_mV, transfer-property=PENDING
        frame VcuAdcTxG8Msg2_oTC37X_VCU_CAN01: id 0x10C, from VCU, frame-length=8, can-addressing-mode=STANDARD
          pdu VcuAdcTxG8Msg2_oTC37X_VCU_CAN01: length=8, minimum-delay=0, transmission-mode-false-timing=cyclic-timing={time-offset=0, time-period=0.5}, transmission-mode-true-timing=cyclic-timing={time-offset=0, time-period=0.5}, unused-bit-pattern=0
            signal AN40_oVcuAdcTxG8Msg2_oTC37X_VCU_CAN01: start 0, 16 bit, little-endian, i-signal-type=PRIMITIVE, init-value=0, base-type=sint16, compu-method=CM_AN40, data-constr=DC_AN40, unit=U_mV, transfer-property=PENDING
            signal AN41_oVcuAdcTxG8Msg2_oTC37X_VCU_CAN01: start 16, 16 bit, little-endian, i-signal-type=PRIMITIVE, init-value=0, base-type=sint16, compu-method=CM_AN41, data-constr=DC_AN41, unit=U_mV, transfer-property=PENDING
            signal AN42_oVcuAdcTxG8Msg2_oTC37X_VCU_CAN01: start 32, 16 bit, little-endian, i-signal-type=PRIMITIVE, init-value=0, base-type=sint16, compu-method=CM_AN42, data-constr=DC_AN42, unit=U_mV, transfer-property=PENDING
            signal AN43_oVcuAdcTxG8Msg2_oTC37X_VCU_CAN01: start 48, 16 bit, little-endian, i-signal-type=PRIMITIVE, init-value=0, base-type=sint16, compu-method=CM_AN43, data-constr=DC_AN43, unit=U_mV, transfer-property=PENDING
        frame VcuAdcTxG8Msg3_oTC37X_VCU_CAN01: id 0x10D, from VCU, frame-length=8, can-addressing-mode=STANDARD
          pdu VcuAdcTxG8Msg3_oTC37X_VCU_CAN01: length=8, minimum-delay=0, transmission-mode-false-timing=cyclic-timing={time-offset=0, time-period=0.5}, transmission-mode-true-timing=cyclic-timing={time-offset=0, time-period=0.5}, unused-bit-pattern=0
            signal AN44_oVcuAdcTxG8Msg3_oTC37X_VCU_CAN01: start 0, 16 bit, little-endian, i-signal-type=PRIMITIVE, init-value=0, base-type=sint16, compu-method=CM_AN44, data-constr=DC_AN44, unit=U_mV, transfer-property=PENDING
            signal AN45_oVcuAdcTxG8Msg3_oTC37X_VCU_CAN01: start 16, 16 bit, little-endian, i-signal-type=PRIMITIVE, init-value=0, base-type=sint16, compu-method=CM_AN45, data-constr=DC_AN45, unit=U_mV, transfer-property=PENDING
            signal AN46_oVcuAdcTxG8Msg3_oTC37X_VCU_CAN01: start 32, 16 bit, little-endian, i-signal-type=PRIMITIVE, init-value=0, base-type=sint16, compu-method=CM_AN46, data-constr=DC_AN46, unit=U_mV, transfer-property=PENDING
            signal AN47_oVcuAdcTxG8Msg3_oTC37X_VCU_CAN01: start 48, 16 bit, little-endian, i-signal-type=PRIMITIVE, init-value=0, base-type=sint16, compu-method=CM_AN47, data-constr=DC_AN47, unit=U_mV, transfer-property=PENDING
        frame VcuRxMsg3_oTC37X_VCU_CAN01: id 0x202, to VCU, frame-length=8, can-addressing-mode=STANDARD
          pdu VcuRxMsg3_oTC37X_VCU_CAN01: length=8, minimum-delay=0, transmission-mode-false-timing=cyclic-timing={time-offset=0, time-period=0.5}, transmission-mode-true-timing=cyclic-timing={time-offset=0, time-period=0.5}, unused-bit-pattern=0
            signal VcuRxMsg3_Sig0_oVcuRxMsg3_oTC37X_VCU_CAN01: start 0, 16 bit, little-endian, i-signal-type=PRIMITIVE, init-value=0, base-type=sint16, compu-method=CM_VcuRxMsg3_Sig0, data-constr=DC_VcuRxMsg3_Sig0, transfer-property=PENDING, to VCU
            signal VcuRxMsg3_Sig1_oVcuRxMsg3_oTC37X_VCU_CAN01: start 16, 16 bit, little-endian, i-signal-type=PRIMITIVE, init-value=0, base-type=sint16, compu-method=CM_VcuRxMsg3_Sig1, data-constr=DC_VcuRxMsg3_Sig1, transfer-property=PENDING, to VCU
            signal VcuRxMsg3_Sig2_oVcuRxMsg3_oTC37X_VCU_CAN01: start 32, 16 bit, little-endian, i-signal-type=PRIMITIVE, init-value=0, base-type=sint16, compu-method=CM_VcuRxMsg3_Sig2, data-constr=DC_VcuRxMsg3_Sig2, transfer-property=PENDING, to VCU
            signal VcuRxMsg3_Sig3_oVcuRxMsg3_oTC37X_VCU_CAN01: start 48, 16 bit, little-endian, i-signal-type=PRIMITIVE, init-value=0, base-type=sint16, compu-method=CM_VcuRxMsg3_Sig3, data-constr=DC_VcuRxMsg3_Sig3, transfer-property=PENDING, to VCU
        frame VcuRxMsg4_oTC37X_VCU_CAN01: id 0x203, to VCU, frame-length=8, can-addressing-mode=STANDARD
          pdu VcuRxMsg4_oTC37X_VCU_CAN01: length=8, minimum-delay=0, transmission-mode-false-timing=cyclic-timing={time-offset=0, time-period=0.5}, transmission-mode-true-timing=cyclic-timing={time-offset=0, time-period=0.5}, unused-bit-pattern=0
            signal VcuRxMsg4_Sig0_oVcuRxMsg4_oTC37X_VCU_CAN01: start 0, 16 bit, little-endian, i-signal-type=PRIMITIVE, init-value=0, base-type=sint16, compu-method=CM_VcuRxMsg4_Sig0, data-constr=DC_VcuRxMsg4_Sig0, transfer-property=PENDING, to VCU
            signal VcuRxMsg4_Sig1_oVcuRxMsg4_oTC37X_VCU_CAN01: start 16, 16 bit, little-endian, i-signal-type=PRIMITIVE, init-value=0, base-type=sint16, compu-method=CM_VcuRxMsg4_Sig1, data-constr=DC_VcuRxMsg4_Sig1, transfer-property=PENDING, to VCU
            signal VcuRxMsg4_Sig2_oVcuRxMsg4_oTC37X_VCU_CAN01: start 32, 16 bit, little-endian, i-signal-type=PRIMITIVE, init-value=0, base-type=sint16, compu-method=CM_VcuRxMsg4_Sig2, data-constr=DC_VcuRxMsg4_Sig2, transfer-property=PENDING, to VCU
            signal VcuRxMsg4_Sig3_oVcuRxMsg4_oTC37X_VCU_CAN01: start 48, 16 bit, little-endian, i-signal-type=PRIMITIVE, init-value=0, base-type=sint16, compu-method=CM_VcuRxMsg4_Sig3, data-constr=DC_VcuRxMsg4_Sig3, transfer-property=PENDING, to VCU
    TC37X_VCU_CAN03: baudrate=500000  # VCU_CAN03
      can physical channel CHNL: comm-connectors=CN_TC37X_VCU_CAN03
        frame VCU_Rx_500h_NM_oTC37X_VCU_CAN03: id 0x500, to VCU, frame-length=8, can-addressing-mode=STANDARD
          nm pdu VCU_Rx_500h_NM_oTC37X_VCU_CAN03: length=8, unused-bit-pattern=0
        frame VCU_Tx_51Ch_NM_oTC37X_VCU_CAN03: id 0x51C, from VCU, frame-length=8, can-addressing-mode=STANDARD
          nm pdu VCU_Tx_51Ch_NM_oTC37X_VCU_CAN03: length=8, unused-bit-pattern=0
        frame VcuCan03RxMsg1_oTC37X_VCU_CAN03: id 0x212, to VCU, frame-length=8, can-addressing-mode=STANDARD
          pdu VcuCan03RxMsg1_oTC37X_VCU_CAN03: length=8, minimum-delay=0, transmission-mode-false-timing=cyclic-timing={time-offset=0, time-period=0.5}, transmission-mode-true-timing=cyclic-timing={time-offset=0, time-period=0.5}, unused-bit-pattern=0
            signal VcuRxMsg3_Sig0_oVcuCan03RxMsg1_oTC37X_VCU_CAN03: start 0, 16 bit, little-endian, i-signal-type=PRIMITIVE, init-value=0, base-type=sint16, compu-method=CM_VcuRxMsg3_Sig0, data-constr=DC_VcuRxMsg3_Sig0, transfer-property=PENDING, to VCU
            signal VcuRxMsg3_Sig1_oVcuCan03RxMsg1_oTC37X_VCU_CAN03: start 16, 16 bit, little-endian, i-signal-type=PRIMITIVE, init-value=0, base-type=sint16, compu-method=CM_VcuRxMsg3_Sig1, data-constr=DC_VcuRxMsg3_Sig1, transfer-property=PENDING, to VCU
            signal VcuRxMsg3_Sig2_oVcuCan03RxMsg1_oTC37X_VCU_CAN03: start 32, 16 bit, little-endian, i-signal-type=PRIMITIVE, init-value=0, base-type=sint16, compu-method=CM_VcuRxMsg3_Sig2, data-constr=DC_VcuRxMsg3_Sig2, transfer-property=PENDING, to VCU
            signal VcuRxMsg3_Sig3_oVcuCan03RxMsg1_oTC37X_VCU_CAN03: start 48, 16 bit, little-endian, i-signal-type=PRIMITIVE, init-value=0, base-type=sint16, compu-method=CM_VcuRxMsg3_Sig3, data-constr=DC_VcuRxMsg3_Sig3, transfer-property=PENDING, to VCU
        frame VcuCan03RxMsg2_oTC37X_VCU_CAN03: id 0x213, to VCU, frame-length=8, can-addressing-mode=STANDARD
          pdu VcuCan03RxMsg2_oTC37X_VCU_CAN03: length=8, minimum-delay=0, transmission-mode-false-timing=cyclic-timing={time-offset=0, time-period=0.5}, transmission-mode-true-timing=cyclic-timing={time-offset=0, time-period=0.5}, unused-bit-pattern=0
            signal VcuRxMsg4_Sig0_oVcuCan03RxMsg2_oTC37X_VCU_CAN03: start 0, 16 bit, little-endian, i-signal-type=PRIMITIVE, init-value=0, base-type=sint16, compu-method=CM_VcuRxMsg4_Sig0, data-constr=DC_VcuRxMsg4_Sig0, transfer-property=PENDING, to VCU
            signal VcuRxMsg4_Sig1_oVcuCan03RxMsg2_oTC37X_VCU_CAN03: start 16, 16 bit, little-endian, i-signal-type=PRIMITIVE, init-value=0, base-type=sint16, compu-method=CM_VcuRxMsg4_Sig1, data-constr=DC_VcuRxMsg4_Sig1, transfer-property=PENDING, to VCU
            signal VcuRxMsg4_Sig2_oVcuCan03RxMsg2_oTC37X_VCU_CAN03: start 32, 16 bit, little-endian, i-signal-type=PRIMITIVE, init-value=0, base-type=sint16, compu-method=CM_VcuRxMsg4_Sig2, data-constr=DC_VcuRxMsg4_Sig2, transfer-property=PENDING, to VCU
            signal VcuRxMsg4_Sig3_oVcuCan03RxMsg2_oTC37X_VCU_CAN03: start 48, 16 bit, little-endian, i-signal-type=PRIMITIVE, init-value=0, base-type=sint16, compu-method=CM_VcuRxMsg4_Sig3, data-constr=DC_VcuRxMsg4_Sig3, transfer-property=PENDING, to VCU
        frame VcuCan03TxMsg1_oTC37X_VCU_CAN03: id 0x112, from VCU, frame-length=8, can-addressing-mode=STANDARD
          pdu VcuCan03TxMsg1_oTC37X_VCU_CAN03: length=8, minimum-delay=0, transmission-mode-false-timing=cyclic-timing={time-offset=0, time-period=0.5}, transmission-mode-true-timing=cyclic-timing={time-offset=0, time-period=0.5}, unused-bit-pattern=0
            signal VcuAdcTxMsg1_Sig0_oVcuCan03TxMsg1_oTC37X_VCU_CAN03: start 0, 16 bit, little-endian, i-signal-type=PRIMITIVE, init-value=0, base-type=sint16, compu-method=CM_VcuAdcTxMsg1_Sig0, data-constr=DC_VcuAdcTxMsg1_Sig0, transfer-property=PENDING
            signal VcuAdcTxMsg1_Sig1_oVcuCan03TxMsg1_oTC37X_VCU_CAN03: start 16, 16 bit, little-endian, i-signal-type=PRIMITIVE, init-value=0, base-type=sint16, compu-method=CM_VcuAdcTxMsg1_Sig1, data-constr=DC_VcuAdcTxMsg1_Sig1, transfer-property=PENDING
            signal VcuAdcTxMsg1_Sig2_oVcuCan03TxMsg1_oTC37X_VCU_CAN03: start 32, 16 bit, little-endian, i-signal-type=PRIMITIVE, init-value=0, base-type=sint16, compu-method=CM_VcuAdcTxMsg1_Sig2, data-constr=DC_VcuAdcTxMsg1_Sig2, transfer-property=PENDING
            signal VcuAdcTxMsg1_Sig3_oVcuCan03TxMsg1_oTC37X_VCU_CAN03: start 48, 16 bit, little-endian, i-signal-type=PRIMITIVE, init-value=0, base-type=sint16, compu-method=CM_VcuAdcTxMsg1_Sig3, data-constr=DC_VcuAdcTxMsg1_Sig3, transfer-property=PENDING
        frame VcuCan03TxMsg2_oTC37X_VCU_CAN03: id 0x113, from VCU, frame-length=8, can-addressing-mode=STANDARD
          pdu VcuCan03TxMsg2_oTC37X_VCU_CAN03: length=8, minimum-delay=0, transmission-mode-false-timing=cyclic-timing={time-offset=0, time-period=0.5}, transmission-mode-true-timing=cyclic-timing={time-offset=0, time-period=0.5}, unused-bit-pattern=0
            signal VcuAdcTxMsg2_Sig0_oVcuCan03TxMsg2_oTC37X_VCU_CAN03: start 0, 16 bit, little-endian, i-signal-type=PRIMITIVE, init-value=0, base-type=sint16, compu-method=CM_VcuAdcTxMsg2_Sig0, data-constr=DC_VcuAdcTxMsg2_Sig0, transfer-property=PENDING
            signal VcuAdcTxMsg2_Sig1_oVcuCan03TxMsg2_oTC37X_VCU_CAN03: start 16, 16 bit, little-endian, i-signal-type=PRIMITIVE, init-value=0, base-type=sint16, compu-method=CM_VcuAdcTxMsg2_Sig1, data-constr=DC_VcuAdcTxMsg2_Sig1, transfer-property=PENDING
            signal VcuAdcTxMsg2_Sig2_oVcuCan03TxMsg2_oTC37X_VCU_CAN03: start 32, 16 bit, little-endian, i-signal-type=PRIMITIVE, init-value=0, base-type=sint16, compu-method=CM_VcuAdcTxMsg2_Sig2, data-constr=DC_VcuAdcTxMsg2_Sig2, transfer-property=PENDING
            signal VcuAdcTxMsg2_Sig3_oVcuCan03TxMsg2_oTC37X_VCU_CAN03: start 48, 16 bit, little-endian, i-signal-type=PRIMITIVE, init-value=0, base-type=sint16, compu-method=CM_VcuAdcTxMsg2_Sig3, data-constr=DC_VcuAdcTxMsg2_Sig3, transfer-property=PENDING
    TC37X_VCU_CAN12: baudrate=500000  # VCU_CAN12
      can physical channel CHNL: comm-connectors=CN_TC37X_VCU_CAN12
        frame VCU_Rx_500h_NM_oTC37X_VCU_CAN12: id 0x500, to VCU, frame-length=8, can-addressing-mode=STANDARD
          nm pdu VCU_Rx_500h_NM_oTC37X_VCU_CAN12: length=8, unused-bit-pattern=0
        frame VCU_Tx_51Ch_NM_oTC37X_VCU_CAN12: id 0x51C, from VCU, frame-length=8, can-addressing-mode=STANDARD
          nm pdu VCU_Tx_51Ch_NM_oTC37X_VCU_CAN12: length=8, unused-bit-pattern=0
        frame VcuCan12RxMsg3_oTC37X_VCU_CAN12: id 0x33, to VCU, frame-length=8, can-addressing-mode=STANDARD
          pdu VcuCan12RxMsg3_oTC37X_VCU_CAN12: length=8, minimum-delay=0, transmission-mode-false-timing=cyclic-timing={time-offset=0, time-period=0.5}, transmission-mode-true-timing=cyclic-timing={time-offset=0, time-period=0.5}, unused-bit-pattern=0
            signal VcuCan12RxMsg3_Sig0_oVcuCan12RxMsg3_oTC37X_VCU_CAN12: start 0, 16 bit, little-endian, i-signal-type=PRIMITIVE, init-value=0, base-type=sint16, compu-method=CM_VcuCan12RxMsg3_Sig0, data-constr=DC_VcuCan12RxMsg3_Sig0, transfer-property=PENDING, to VCU
            signal VcuCan12RxMsg3_Sig1_oVcuCan12RxMsg3_oTC37X_VCU_CAN12: start 16, 16 bit, little-endian, i-signal-type=PRIMITIVE, init-value=0, base-type=sint16, compu-method=CM_VcuCan12RxMsg3_Sig1, data-constr=DC_VcuCan12RxMsg3_Sig1, transfer-property=PENDING, to VCU
            signal VcuCan12RxMsg3_Sig2_oVcuCan12RxMsg3_oTC37X_VCU_CAN12: start 32, 16 bit, little-endian, i-signal-type=PRIMITIVE, init-value=0, base-type=sint16, compu-method=CM_VcuCan12RxMsg3_Sig2, data-constr=DC_VcuCan12RxMsg3_Sig2, transfer-property=PENDING, to VCU
            signal VcuCan12RxMsg3_Sig3_oVcuCan12RxMsg3_oTC37X_VCU_CAN12: start 48, 16 bit, little-endian, i-signal-type=PRIMITIVE, init-value=0, base-type=sint16, compu-method=CM_VcuCan12RxMsg3_Sig3, data-constr=DC_VcuCan12RxMsg3_Sig3, transfer-property=PENDING, to VCU
        frame VcuCan12RxMsg4_oTC37X_VCU_CAN12: id 0x32, to VCU, frame-length=8, can-addressing-mode=STANDARD
          pdu VcuCan12RxMsg4_oTC37X_VCU_CAN12: length=8, minimum-delay=0, transmission-mode-false-timing=cyclic-timing={time-offset=0, time-period=0.5}, transmission-mode-true-timing=cyclic-timing={time-offset=0, time-period=0.5}, unused-bit-pattern=0
            signal VcuCan12RxMsg4_Sig0_oVcuCan12RxMsg4_oTC37X_VCU_CAN12: start 0, 16 bit, little-endian, i-signal-type=PRIMITIVE, init-value=0, base-type=sint16, compu-method=CM_VcuCan12RxMsg4_Sig0, data-constr=DC_VcuCan12RxMsg4_Sig0, transfer-property=PENDING, to VCU
            signal VcuCan12RxMsg4_Sig1_oVcuCan12RxMsg4_oTC37X_VCU_CAN12: start 16, 16 bit, little-endian, i-signal-type=PRIMITIVE, init-value=0, base-type=sint16, compu-method=CM_VcuCan12RxMsg4_Sig1, data-constr=DC_VcuCan12RxMsg4_Sig1, transfer-property=PENDING, to VCU
            signal VcuCan12RxMsg4_Sig2_oVcuCan12RxMsg4_oTC37X_VCU_CAN12: start 32, 16 bit, little-endian, i-signal-type=PRIMITIVE, init-value=0, base-type=sint16, compu-method=CM_VcuCan12RxMsg4_Sig2, data-constr=DC_VcuCan12RxMsg4_Sig2, transfer-property=PENDING, to VCU
            signal VcuCan12RxMsg4_Sig3_oVcuCan12RxMsg4_oTC37X_VCU_CAN12: start 48, 16 bit, little-endian, i-signal-type=PRIMITIVE, init-value=0, base-type=sint16, compu-method=CM_VcuCan12RxMsg4_Sig3, data-constr=DC_VcuCan12RxMsg4_Sig3, transfer-property=PENDING, to VCU
        frame VcuCan12TxMsg1_oTC37X_VCU_CAN12: id 0x35, from VCU, frame-length=8, can-addressing-mode=STANDARD
          pdu VcuCan12TxMsg1_oTC37X_VCU_CAN12: length=8, minimum-delay=0, transmission-mode-false-timing=cyclic-timing={time-offset=0, time-period=0.5}, transmission-mode-true-timing=cyclic-timing={time-offset=0, time-period=0.5}, unused-bit-pattern=0
            signal VcuCan12TxMsg1_Sig0_oVcuCan12TxMsg1_oTC37X_VCU_CAN12: start 0, 16 bit, little-endian, i-signal-type=PRIMITIVE, init-value=0, base-type=sint16, compu-method=CM_VcuCan12TxMsg1_Sig0, data-constr=DC_VcuCan12TxMsg1_Sig0, transfer-property=PENDING
            signal VcuCan12TxMsg1_Sig1_oVcuCan12TxMsg1_oTC37X_VCU_CAN12: start 16, 16 bit, little-endian, i-signal-type=PRIMITIVE, init-value=0, base-type=sint16, compu-method=CM_VcuCan12TxMsg1_Sig1, data-constr=DC_VcuCan12TxMsg1_Sig1, transfer-property=PENDING
            signal VcuCan12TxMsg1_Sig2_oVcuCan12TxMsg1_oTC37X_VCU_CAN12: start 32, 16 bit, little-endian, i-signal-type=PRIMITIVE, init-value=0, base-type=sint16, compu-method=CM_VcuCan12TxMsg1_Sig2, data-constr=DC_VcuCan12TxMsg1_Sig2, transfer-property=PENDING
            signal VcuCan12TxMsg1_Sig3_oVcuCan12TxMsg1_oTC37X_VCU_CAN12: start 48, 16 bit, little-endian, i-signal-type=PRIMITIVE, init-value=0, base-type=sint16, compu-method=CM_VcuCan12TxMsg1_Sig3, data-constr=DC_VcuCan12TxMsg1_Sig3, transfer-property=PENDING
        frame VcuCan12TxMsg2_oTC37X_VCU_CAN12: id 0x34, from VCU, frame-length=8, can-addressing-mode=STANDARD
          pdu VcuCan12TxMsg2_oTC37X_VCU_CAN12: length=8, minimum-delay=0, transmission-mode-false-timing=cyclic-timing={time-offset=0, time-period=0.5}, transmission-mode-true-timing=cyclic-timing={time-offset=0, time-period=0.5}, unused-bit-pattern=0
            signal VcuCan12TxMsg2_Sig0_oVcuCan12TxMsg2_oTC37X_VCU_CAN12: start 0, 16 bit, little-endian, i-signal-type=PRIMITIVE, init-value=0, base-type=sint16, compu-method=CM_VcuCan12TxMsg2_Sig0, data-constr=DC_VcuCan12TxMsg2_Sig0, transfer-property=PENDING
            signal VcuCan12TxMsg2_Sig1_oVcuCan12TxMsg2_oTC37X_VCU_CAN12: start 16, 16 bit, little-endian, i-signal-type=PRIMITIVE, init-value=0, base-type=sint16, compu-method=CM_VcuCan12TxMsg2_Sig1, data-constr=DC_VcuCan12TxMsg2_Sig1, transfer-property=PENDING
            signal VcuCan12TxMsg2_Sig2_oVcuCan12TxMsg2_oTC37X_VCU_CAN12: start 32, 16 bit, little-endian, i-signal-type=PRIMITIVE, init-value=0, base-type=sint16, compu-method=CM_VcuCan12TxMsg2_Sig2, data-constr=DC_VcuCan12TxMsg2_Sig2, transfer-property=PENDING
            signal VcuCan12TxMsg2_Sig3_oVcuCan12TxMsg2_oTC37X_VCU_CAN12: start 48, 16 bit, little-endian, i-signal-type=PRIMITIVE, init-value=0, base-type=sint16, compu-method=CM_VcuCan12TxMsg2_Sig3, data-constr=DC_VcuCan12TxMsg2_Sig3, transfer-property=PENDING
  lin cluster LIN00: baudrate=19200, protocol-name=LIN, protocol-version=LIN21  # /*************************************************************************************/ // // Description: // Created: // Author: // Version: // Vehicle Project: // /*************************************************************************************/
    lin physical channel CHNL: comm-connectors=CN_LIN00
      frame EDCU_EXV2_oLIN00: id 0x22, from VCU, frame-length=8, lin-checksum=ENHANCED
        pdu EDCU_EXV2_oLIN00: length=8, unused-bit-pattern=255
          signal EDCU_EXV2_Cmd_Set_Rq_oEDCU_EXV2_oLIN00: start 0, 16 bit, little-endian, i-signal-type=PRIMITIVE, init-value=0, base-type=uint16, compu-method=CM_EDCU_EXV2_Cmd_Set_Rq, data-constr=DC_EDCU_EXV2_Cmd_Set_Rq
          signal EDCU_EXV2_Cmd_Move_Enbl_oEDCU_EXV2_oLIN00: start 16, 1 bit, little-endian, i-signal-type=PRIMITIVE, init-value=0, base-type=boolean, compu-method=CM_EDCU_EXV2_Cmd_Move_Enbl, data-constr=DC_EDCU_EXV2_Cmd_Move_Enbl
          signal EDCU_EXV2_Cmd_Init_Rq_oEDCU_EXV2_oLIN00: start 24, 3 bit, little-endian, i-signal-type=PRIMITIVE, init-value=0, base-type=uint8, compu-method=CM_EDCU_EXV2_Cmd_Init_Rq, data-constr=DC_EDCU_EXV2_Cmd_Init_Rq
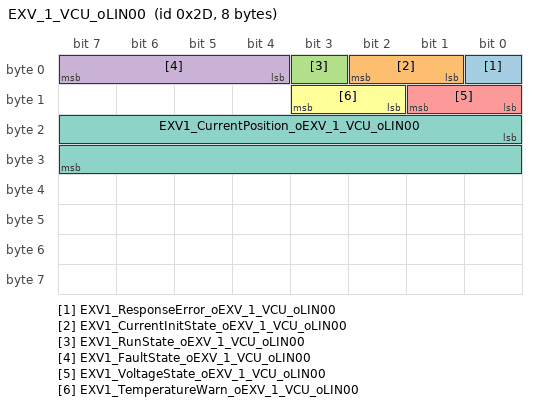
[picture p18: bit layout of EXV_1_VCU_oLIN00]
      frame EXV_1_VCU_oLIN00: id 0x2D, to VCU, frame-length=8, lin-checksum=ENHANCED
        pdu EXV_1_VCU_oLIN00: length=8, unused-bit-pattern=255
          signal EXV1_ResponseError_oEXV_1_VCU_oLIN00: start 0, 1 bit, little-endian, i-signal-type=PRIMITIVE, init-value=0, base-type=boolean, compu-method=CM_EXV1_ResponseError, data-constr=DC_EXV1_ResponseError, to VCU
          signal EXV1_CurrentInitState_oEXV_1_VCU_oLIN00: start 1, 2 bit, little-endian, i-signal-type=PRIMITIVE, init-value=0, base-type=uint8, compu-method=CM_EXV1_CurrentInitState, data-constr=DC_EXV1_CurrentInitState, to VCU
          signal EXV1_RunState_oEXV_1_VCU_oLIN00: start 3, 1 bit, little-endian, i-signal-type=PRIMITIVE, init-value=0, base-type=boolean, compu-method=CM_EXV1_RunState, data-constr=DC_EXV1_RunState, to VCU
          signal EXV1_FaultState_oEXV_1_VCU_oLIN00: start 4, 4 bit, little-endian, i-signal-type=PRIMITIVE, init-value=0, base-type=uint8, compu-method=CM_EXV1_FaultState, data-constr=DC_EXV1_FaultState, to VCU
          signal EXV1_VoltageState_oEXV_1_VCU_oLIN00: start 8, 2 bit, little-endian, i-signal-type=PRIMITIVE, init-value=0, base-type=uint8, compu-method=CM_EXV1_VoltageState, data-constr=DC_EXV1_VoltageState, to VCU
          signal EXV1_TemperatureWarn_oEXV_1_VCU_oLIN00: start 10, 2 bit, little-endian, i-signal-type=PRIMITIVE, init-value=0, base-type=uint8, compu-method=CM_EXV1_TemperatureWarn, data-constr=DC_EXV1_TemperatureWarn, to VCU
          signal EXV1_CurrentPosition_oEXV_1_VCU_oLIN00: start 16, 16 bit, little-endian, i-signal-type=PRIMITIVE, init-value=0, base-type=uint16, compu-method=CM_EXV1_CurrentPosition, data-constr=DC_EXV1_CurrentPosition, to VCU
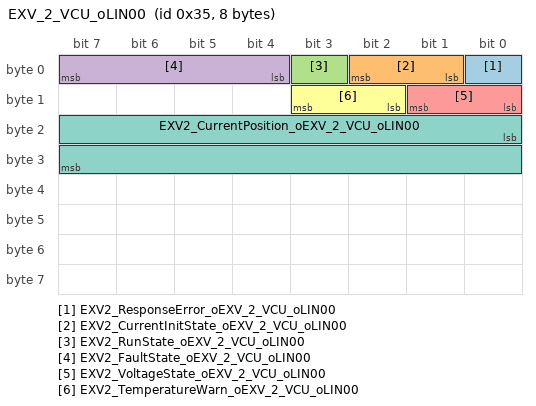
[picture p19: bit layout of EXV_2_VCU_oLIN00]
      frame EXV_2_VCU_oLIN00: id 0x35, to VCU, frame-length=8, lin-checksum=ENHANCED
        pdu EXV_2_VCU_oLIN00: length=8, unused-bit-pattern=255
          signal EXV2_ResponseError_oEXV_2_VCU_oLIN00: start 0, 1 bit, little-endian, i-signal-type=PRIMITIVE, init-value=0, base-type=boolean, compu-method=CM_EXV2_ResponseError, data-constr=DC_EXV2_ResponseError, to VCU
          signal EXV2_CurrentInitState_oEXV_2_VCU_oLIN00: start 1, 2 bit, little-endian, i-signal-type=PRIMITIVE, init-value=0, base-type=uint8, compu-method=CM_EXV2_CurrentInitState, data-constr=DC_EXV2_CurrentInitState, to VCU
          signal EXV2_RunState_oEXV_2_VCU_oLIN00: start 3, 1 bit, little-endian, i-signal-type=PRIMITIVE, init-value=0, base-type=boolean, compu-method=CM_EXV2_RunState, data-constr=DC_EXV2_RunState, to VCU
          signal EXV2_FaultState_oEXV_2_VCU_oLIN00: start 4, 4 bit, little-endian, i-signal-type=PRIMITIVE, init-value=0, base-type=uint8, compu-method=CM_EXV2_FaultState, data-constr=DC_EXV2_FaultState, to VCU
          signal EXV2_VoltageState_oEXV_2_VCU_oLIN00: start 8, 2 bit, little-endian, i-signal-type=PRIMITIVE, init-value=0, base-type=uint8, compu-method=CM_EXV2_VoltageState, data-constr=DC_EXV2_VoltageState, to VCU
          signal EXV2_TemperatureWarn_oEXV_2_VCU_oLIN00: start 10, 2 bit, little-endian, i-signal-type=PRIMITIVE, init-value=0, base-type=uint8, compu-method=CM_EXV2_TemperatureWarn, data-constr=DC_EXV2_TemperatureWarn, to VCU
          signal EXV2_CurrentPosition_oEXV_2_VCU_oLIN00: start 16, 16 bit, little-endian, i-signal-type=PRIMITIVE, init-value=0, base-type=uint16, compu-method=CM_EXV2_CurrentPosition, data-constr=DC_EXV2_CurrentPosition, to VCU
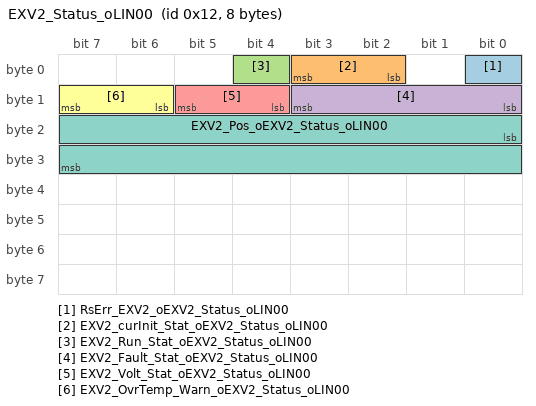
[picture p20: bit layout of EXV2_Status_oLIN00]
      frame EXV2_Status_oLIN00: id 0x12, to VCU, frame-length=8, lin-checksum=ENHANCED
        pdu EXV2_Status_oLIN00: length=8, unused-bit-pattern=255
          signal RsErr_EXV2_oEXV2_Status_oLIN00: start 0, 1 bit, little-endian, i-signal-type=PRIMITIVE, init-value=0, base-type=boolean, compu-method=CM_RsErr_EXV2, data-constr=DC_RsErr_EXV2, to VCU
          signal EXV2_curInit_Stat_oEXV2_Status_oLIN00: start 2, 2 bit, little-endian, i-signal-type=PRIMITIVE, init-value=0, base-type=uint8, compu-method=CM_EXV2_curInit_Stat, data-constr=DC_EXV2_curInit_Stat, to VCU
          signal EXV2_Run_Stat_oEXV2_Status_oLIN00: start 4, 1 bit, little-endian, i-signal-type=PRIMITIVE, init-value=0, base-type=boolean, compu-method=CM_EXV2_Run_Stat, data-constr=DC_EXV2_Run_Stat, to VCU
          signal EXV2_Fault_Stat_oEXV2_Status_oLIN00: start 8, 4 bit, little-endian, i-signal-type=PRIMITIVE, init-value=0, base-type=uint8, compu-method=CM_EXV2_Fault_Stat, data-constr=DC_EXV2_Fault_Stat, to VCU
          signal EXV2_Volt_Stat_oEXV2_Status_oLIN00: start 12, 2 bit, little-endian, i-signal-type=PRIMITIVE, init-value=0, base-type=uint8, compu-method=CM_EXV2_Volt_Stat, data-constr=DC_EXV2_Volt_Stat, to VCU
          signal EXV2_OvrTemp_Warn_oEXV2_Status_oLIN00: start 14, 2 bit, little-endian, i-signal-type=PRIMITIVE, init-value=0, base-type=uint8, compu-method=CM_EXV2_OvrTemp_Warn, data-constr=DC_EXV2_OvrTemp_Warn, to VCU
          signal EXV2_Pos_oEXV2_Status_oLIN00: start 16, 16 bit, little-endian, i-signal-type=PRIMITIVE, init-value=0, base-type=uint16, compu-method=CM_EXV2_Pos, data-constr=DC_EXV2_Pos, to VCU
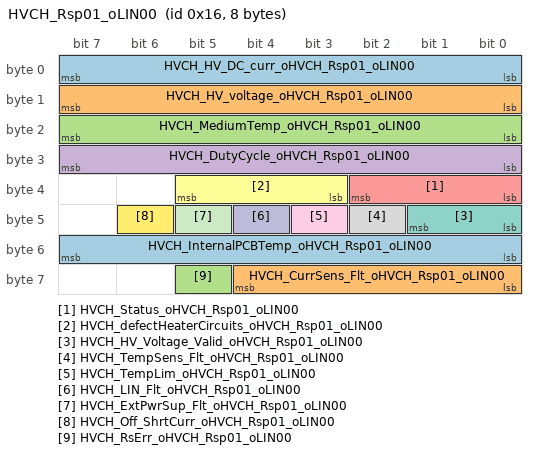
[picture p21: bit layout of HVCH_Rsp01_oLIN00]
      frame HVCH_Rsp01_oLIN00: id 0x16, to VCU, frame-length=8, lin-checksum=ENHANCED
        pdu HVCH_Rsp01_oLIN00: length=8, unused-bit-pattern=255
          signal HVCH_HV_DC_curr_oHVCH_Rsp01_oLIN00: start 0, 8 bit, little-endian, i-signal-type=PRIMITIVE, init-value=0, base-type=uint8, compu-method=CM_HVCH_HV_DC_curr, data-constr=DC_HVCH_HV_DC_curr, unit=U_A, to VCU
          signal HVCH_HV_voltage_oHVCH_Rsp01_oLIN00: start 8, 8 bit, little-endian, i-signal-type=PRIMITIVE, init-value=0, base-type=uint8, compu-method=CM_HVCH_HV_voltage, data-constr=DC_HVCH_HV_voltage, unit=U_V, to VCU
          signal HVCH_MediumTemp_oHVCH_Rsp01_oLIN00: start 16, 8 bit, little-endian, i-signal-type=PRIMITIVE, init-value=0, base-type=uint8, compu-method=CM_HVCH_MediumTemp, data-constr=DC_HVCH_MediumTemp, unit=U_celsius, to VCU
          signal HVCH_DutyCycle_oHVCH_Rsp01_oLIN00: start 24, 8 bit, little-endian, i-signal-type=PRIMITIVE, init-value=50, base-type=uint8, compu-method=CM_HVCH_DutyCycle, data-constr=DC_HVCH_DutyCycle, unit=U_percent, to VCU
          signal HVCH_Status_oHVCH_Rsp01_oLIN00: start 32, 3 bit, little-endian, i-signal-type=PRIMITIVE, init-value=0, base-type=uint8, compu-method=CM_HVCH_Status, data-constr=DC_HVCH_Status, to VCU
          signal HVCH_defectHeaterCircuits_oHVCH_Rsp01_oLIN00: start 35, 3 bit, little-endian, i-signal-type=PRIMITIVE, init-value=0, base-type=uint8, compu-method=CM_HVCH_defectHeaterCircuits, data-constr=DC_HVCH_defectHeaterCircuits, to VCU
          signal HVCH_HV_Voltage_Valid_oHVCH_Rsp01_oLIN00: start 40, 2 bit, little-endian, i-signal-type=PRIMITIVE, init-value=0, base-type=uint8, compu-method=CM_HVCH_HV_Voltage_Valid, data-constr=DC_HVCH_HV_Voltage_Valid, to VCU
          signal HVCH_TempSens_Flt_oHVCH_Rsp01_oLIN00: start 42, 1 bit, little-endian, i-signal-type=PRIMITIVE, init-value=0, base-type=boolean, compu-method=CM_HVCH_TempSens_Flt, data-constr=DC_HVCH_TempSens_Flt, to VCU
          signal HVCH_TempLim_oHVCH_Rsp01_oLIN00: start 43, 1 bit, little-endian, i-signal-type=PRIMITIVE, init-value=0, base-type=boolean, compu-method=CM_HVCH_TempLim, data-constr=DC_HVCH_TempLim, to VCU
          signal HVCH_LIN_Flt_oHVCH_Rsp01_oLIN00: start 44, 1 bit, little-endian, i-signal-type=PRIMITIVE, init-value=0, base-type=boolean, compu-method=CM_HVCH_LIN_Flt, data-constr=DC_HVCH_LIN_Flt, to VCU
          signal HVCH_ExtPwrSup_Flt_oHVCH_Rsp01_oLIN00: start 45, 1 bit, little-endian, i-signal-type=PRIMITIVE, init-value=0, base-type=boolean, compu-method=CM_HVCH_ExtPwrSup_Flt, data-constr=DC_HVCH_ExtPwrSup_Flt, to VCU
          signal HVCH_Off_ShrtCurr_oHVCH_Rsp01_oLIN00: start 46, 1 bit, little-endian, i-signal-type=PRIMITIVE, init-value=0, base-type=boolean, compu-method=CM_HVCH_Off_ShrtCurr, data-constr=DC_HVCH_Off_ShrtCurr, to VCU
          signal HVCH_InternalPCBTemp_oHVCH_Rsp01_oLIN00: start 48, 8 bit, little-endian, i-signal-type=PRIMITIVE, init-value=0, base-type=uint8, compu-method=CM_HVCH_InternalPCBTemp, data-constr=DC_HVCH_InternalPCBTemp, to VCU
          signal HVCH_CurrSens_Flt_oHVCH_Rsp01_oLIN00: start 56, 5 bit, little-endian, i-signal-type=PRIMITIVE, init-value=0, base-type=uint8, compu-method=CM_HVCH_CurrSens_Flt, data-constr=DC_HVCH_CurrSens_Flt, to VCU
          signal HVCH_RsErr_oHVCH_Rsp01_oLIN00: start 61, 1 bit, little-endian, i-signal-type=PRIMITIVE, init-value=0, base-type=boolean, compu-method=CM_HVCH_RsErr, data-constr=DC_HVCH_RsErr, to VCU
      frame HVCH_Rsp02_oLIN00: id 0x17, to VCU, frame-length=8, lin-checksum=ENHANCED
        pdu HVCH_Rsp02_oLIN00: length=8, unused-bit-pattern=255
          signal HVCH_IntelTemp_oHVCH_Rsp02_oLIN00: start 0, 8 bit, little-endian, i-signal-type=PRIMITIVE, init-value=0, base-type=uint8, compu-method=CM_HVCH_IntelTemp, data-constr=DC_HVCH_IntelTemp, unit=U_celsius, to VCU
      frame MasterReq_oLIN00: id 0x3C, from VCU, frame-length=8, lin-checksum=CLASSIC
        n pdu MasterReq_Tp_oLIN00: length=8
      frame PMP_Cmd_oLIN00: id 0x24, from VCU, frame-length=8, lin-checksum=ENHANCED
        pdu PMP_Cmd_oLIN00: length=8, unused-bit-pattern=255
          signal ECC_PMP2_SpdSet_oPMP_Cmd_oLIN00: start 8, 8 bit, little-endian, i-signal-type=PRIMITIVE, init-value=0, base-type=uint8, compu-method=CM_ECC_PMP2_SpdSet, data-constr=DC_ECC_PMP2_SpdSet, unit=U_p
          signal ECC_PMP3_SpdSet_oPMP_Cmd_oLIN00: start 16, 8 bit, little-endian, i-signal-type=PRIMITIVE, init-value=0, base-type=uint8, compu-method=CM_ECC_PMP3_SpdSet, data-constr=DC_ECC_PMP3_SpdSet, unit=U_p
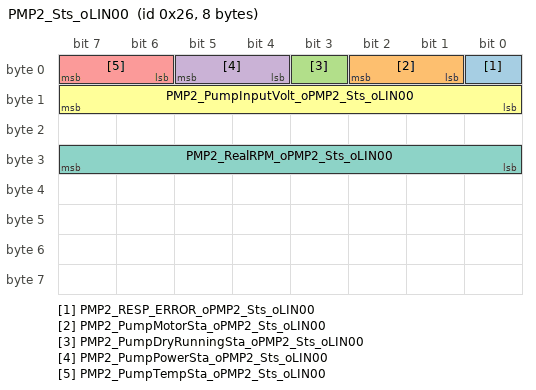
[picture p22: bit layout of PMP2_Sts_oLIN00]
      frame PMP2_Sts_oLIN00: id 0x26, to VCU, frame-length=8, lin-checksum=ENHANCED
        pdu PMP2_Sts_oLIN00: length=8, unused-bit-pattern=255
          signal PMP2_RESP_ERROR_oPMP2_Sts_oLIN00: start 0, 1 bit, little-endian, i-signal-type=PRIMITIVE, init-value=0, base-type=boolean, compu-method=CM_PMP2_RESP_ERROR, data-constr=DC_PMP2_RESP_ERROR, to VCU
          signal PMP2_PumpMotorSta_oPMP2_Sts_oLIN00: start 1, 2 bit, little-endian, i-signal-type=PRIMITIVE, init-value=0, base-type=uint8, compu-method=CM_PMP2_PumpMotorSta, data-constr=DC_PMP2_PumpMotorSta, to VCU
          signal PMP2_PumpDryRunningSta_oPMP2_Sts_oLIN00: start 3, 1 bit, little-endian, i-signal-type=PRIMITIVE, init-value=0, base-type=boolean, compu-method=CM_PMP2_PumpDryRunningSta, data-constr=DC_PMP2_PumpDryRunningSta, to VCU
          signal PMP2_PumpPowerSta_oPMP2_Sts_oLIN00: start 4, 2 bit, little-endian, i-signal-type=PRIMITIVE, init-value=0, base-type=uint8, compu-method=CM_PMP2_PumpPowerSta, data-constr=DC_PMP2_PumpPowerSta, to VCU
          signal PMP2_PumpTempSta_oPMP2_Sts_oLIN00: start 6, 2 bit, little-endian, i-signal-type=PRIMITIVE, init-value=0, base-type=uint8, compu-method=CM_PMP2_PumpTempSta, data-constr=DC_PMP2_PumpTempSta, to VCU
          signal PMP2_PumpInputVolt_oPMP2_Sts_oLIN00: start 8, 8 bit, little-endian, i-signal-type=PRIMITIVE, init-value=0, base-type=uint8, compu-method=CM_PMP2_PumpInputVolt, data-constr=DC_PMP2_PumpInputVolt, unit=U_V, to VCU
          signal PMP2_RealRPM_oPMP2_Sts_oLIN00: start 24, 8 bit, little-endian, i-signal-type=PRIMITIVE, init-value=0, base-type=uint8, compu-method=CM_PMP2_RealRPM, data-constr=DC_PMP2_RealRPM, unit=U_p, to VCU
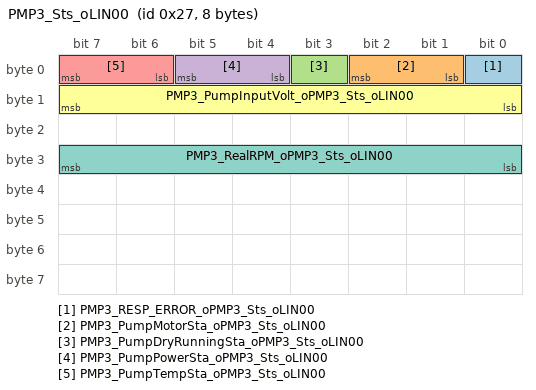
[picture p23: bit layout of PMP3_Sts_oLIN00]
      frame PMP3_Sts_oLIN00: id 0x27, to VCU, frame-length=8, lin-checksum=ENHANCED
        pdu PMP3_Sts_oLIN00: length=8, unused-bit-pattern=255
          signal PMP3_RESP_ERROR_oPMP3_Sts_oLIN00: start 0, 1 bit, little-endian, i-signal-type=PRIMITIVE, init-value=0, base-type=boolean, compu-method=CM_PMP3_RESP_ERROR, data-constr=DC_PMP3_RESP_ERROR, to VCU
          signal PMP3_PumpMotorSta_oPMP3_Sts_oLIN00: start 1, 2 bit, little-endian, i-signal-type=PRIMITIVE, init-value=0, base-type=uint8, compu-method=CM_PMP3_PumpMotorSta, data-constr=DC_PMP3_PumpMotorSta, to VCU
          signal PMP3_PumpDryRunningSta_oPMP3_Sts_oLIN00: start 3, 1 bit, little-endian, i-signal-type=PRIMITIVE, init-value=0, base-type=boolean, compu-method=CM_PMP3_PumpDryRunningSta, data-constr=DC_PMP3_PumpDryRunningSta, to VCU
          signal PMP3_PumpPowerSta_oPMP3_Sts_oLIN00: start 4, 2 bit, little-endian, i-signal-type=PRIMITIVE, init-value=0, base-type=uint8, compu-method=CM_PMP3_PumpPowerSta, data-constr=DC_PMP3_PumpPowerSta, to VCU
          signal PMP3_PumpTempSta_oPMP3_Sts_oLIN00: start 6, 2 bit, little-endian, i-signal-type=PRIMITIVE, init-value=0, base-type=uint8, compu-method=CM_PMP3_PumpTempSta, data-constr=DC_PMP3_PumpTempSta, to VCU
          signal PMP3_PumpInputVolt_oPMP3_Sts_oLIN00: start 8, 8 bit, little-endian, i-signal-type=PRIMITIVE, init-value=0, base-type=uint8, compu-method=CM_PMP3_PumpInputVolt, data-constr=DC_PMP3_PumpInputVolt, unit=U_V, to VCU
          signal PMP3_RealRPM_oPMP3_Sts_oLIN00: start 24, 8 bit, little-endian, i-signal-type=PRIMITIVE, init-value=0, base-type=uint8, compu-method=CM_PMP3_RealRPM, data-constr=DC_PMP3_RealRPM, unit=U_p, to VCU
      frame SlaveResp_oLIN00: id 0x3D, to VCU, frame-length=8, lin-checksum=CLASSIC
        n pdu SlaveResp_Tp_oLIN00: length=8
      frame SVA_VCU_STD_oLIN00: id 0x11, to VCU, frame-length=8, lin-checksum=ENHANCED
        pdu SVA_VCU_STD_oLIN00: length=8, unused-bit-pattern=255
          signal Calibration_sta_oSVA_VCU_STD_oLIN00: start 0, 2 bit, little-endian, i-signal-type=PRIMITIVE, init-value=0, base-type=uint8, compu-method=CM_Calibration_sta, data-constr=DC_Calibration_sta, to VCU
          signal Blockage_Fault_STA_oSVA_VCU_STD_oLIN00: start 2, 1 bit, little-endian, i-signal-type=PRIMITIVE, init-value=0, base-type=boolean, compu-method=CM_Blockage_Fault_STA, data-constr=DC_Blockage_Fault_STA, to VCU
          signal Breakage_Fault_STA_oSVA_VCU_STD_oLIN00: start 3, 1 bit, little-endian, i-signal-type=PRIMITIVE, init-value=0, base-type=boolean, compu-method=CM_Breakage_Fault_STA, data-constr=DC_Breakage_Fault_STA, to VCU
          signal Act_Pos_sta_oSVA_VCU_STD_oLIN00: start 8, 12 bit, little-endian, i-signal-type=PRIMITIVE, init-value=0, base-type=uint16, compu-method=CM_Act_Pos_sta, data-constr=DC_Act_Pos_sta, unit=U_Degree, to VCU
          signal LIN_Resp_Error_sta_oSVA_VCU_STD_oLIN00: start 32, 1 bit, little-endian, i-signal-type=PRIMITIVE, init-value=0, base-type=boolean, compu-method=CM_LIN_Resp_Error_sta, data-constr=DC_LIN_Resp_Error_sta, to VCU
      frame TCU_HVCH_Cmd_oLIN00: id 0x15, from VCU, frame-length=4, lin-checksum=ENHANCED
        pdu TCU_HVCH_Cmd_oLIN00: length=4, unused-bit-pattern=255
          signal TCU_HVCH_heating_rq_oTCU_HVCH_Cmd_oLIN00: start 0, 7 bit, little-endian, i-signal-type=PRIMITIVE, init-value=0, base-type=uint8, compu-method=CM_TCU_HVCH_heating_rq, data-constr=DC_TCU_HVCH_heating_rq, unit=U_percent
          signal TCU_HVCH_On_Rq_oTCU_HVCH_Cmd_oLIN00: start 8, 2 bit, little-endian, i-signal-type=PRIMITIVE, init-value=0, base-type=uint8, invalid-value=3, compu-method=CM_TCU_HVCH_On_Rq, data-constr=DC_TCU_HVCH_On_Rq
          signal TCU_HVCHMaxPowerLimit_oTCU_HVCH_Cmd_oLIN00: start 16, 8 bit, little-endian, i-signal-type=PRIMITIVE, init-value=0, base-type=uint8, compu-method=CM_TCU_HVCHMaxPowerLimit, data-constr=DC_TCU_HVCHMaxPowerLimit, unit=U_KW
          signal TCU_HVCH_TmaxLim_output_oTCU_HVCH_Cmd_oLIN00: start 24, 8 bit, little-endian, i-signal-type=PRIMITIVE, init-value=0, base-type=uint8, compu-method=CM_TCU_HVCH_TmaxLim_output, data-constr=DC_TCU_HVCH_TmaxLim_output, unit=U_celsius
      frame VCU_EXV_1_oLIN00: id 0x1F, from VCU, frame-length=8, lin-checksum=ENHANCED
        pdu VCU_EXV_1_oLIN00: length=8, unused-bit-pattern=255
          signal TMM_EXV1_PositionRequest_oVCU_EXV_1_oLIN00: start 0, 16 bit, little-endian, i-signal-type=PRIMITIVE, init-value=0, base-type=uint16, compu-method=CM_TMM_EXV1_PositionRequest, data-constr=DC_TMM_EXV1_PositionRequest
          signal TMM_EXV1_EnableRequest_oVCU_EXV_1_oLIN00: start 16, 1 bit, little-endian, i-signal-type=PRIMITIVE, init-value=0, base-type=boolean, compu-method=CM_TMM_EXV1_EnableRequest, data-constr=DC_TMM_EXV1_EnableRequest
          signal TMM_EXV1_initRequest_oVCU_EXV_1_oLIN00: start 24, 3 bit, little-endian, i-signal-type=PRIMITIVE, init-value=0, base-type=uint8, compu-method=CM_TMM_EXV1_initRequest, data-constr=DC_TMM_EXV1_initRequest
      frame VCU_EXV_2_oLIN00: id 0x34, from VCU, frame-length=8, lin-checksum=ENHANCED
        pdu VCU_EXV_2_oLIN00: length=8, unused-bit-pattern=255
          signal TMM_EXV2_PositionRequest_oVCU_EXV_2_oLIN00: start 0, 16 bit, little-endian, i-signal-type=PRIMITIVE, init-value=0, base-type=uint16, compu-method=CM_TMM_EXV2_PositionRequest, data-constr=DC_TMM_EXV2_PositionRequest
          signal TMM_EXV2_EnableRequest_oVCU_EXV_2_oLIN00: start 16, 1 bit, little-endian, i-signal-type=PRIMITIVE, init-value=0, base-type=boolean, compu-method=CM_TMM_EXV2_EnableRequest, data-constr=DC_TMM_EXV2_EnableRequest
          signal TMM_EXV2_initRequest_oVCU_EXV_2_oLIN00: start 24, 3 bit, little-endian, i-signal-type=PRIMITIVE, init-value=0, base-type=uint8, compu-method=CM_TMM_EXV2_initRequest, data-constr=DC_TMM_EXV2_initRequest
      frame VCU_SVA_CMD_oLIN00: id 0x10, from VCU, frame-length=8, lin-checksum=ENHANCED
        pdu VCU_SVA_CMD_oLIN00: length=8, unused-bit-pattern=255
          signal Calibration_cmd_oVCU_SVA_CMD_oLIN00: start 8, 1 bit, little-endian, i-signal-type=PRIMITIVE, init-value=0, base-type=boolean, compu-method=CM_Calibration_cmd, data-constr=DC_Calibration_cmd
          signal Target_Pos_cmd_oVCU_SVA_CMD_oLIN00: start 16, 12 bit, little-endian, i-signal-type=PRIMITIVE, init-value=0, base-type=uint16, compu-method=CM_Target_Pos_cmd, data-constr=DC_Target_Pos_cmd, unit=U_Degree
      pdu triggering PT_MasterReq: pdu=MasterReq_oLIN00, from VCU
      pdu triggering PT_MasterReq_ERV: pdu=MasterReq_ERV_oLIN00, from VCU
      pdu triggering PT_MasterReq_EXV_1: pdu=MasterReq_EXV_1_oLIN00, from VCU
      pdu triggering PT_MasterReq_EXV_2: pdu=MasterReq_EXV_2_oLIN00, from VCU
      pdu triggering PT_MasterReq_HVCH: pdu=MasterReq_HVCH_oLIN00, from VCU
      pdu triggering PT_MasterReq_PMP_1: pdu=MasterReq_PMP_1_oLIN00, from VCU
      pdu triggering PT_MasterReq_PMP_2: pdu=MasterReq_PMP_2_oLIN00, from VCU
      pdu triggering PT_MasterReq_SVA: pdu=MasterReq_SVA_oLIN00, from VCU
      pdu triggering PT_SlaveResp_ERV: pdu=SlaveResp_ERV_oLIN00, to VCU
      pdu triggering PT_SlaveResp_EXV_1: pdu=SlaveResp_EXV_1_oLIN00, to VCU
      pdu triggering PT_SlaveResp_EXV_2: pdu=SlaveResp_EXV_2_oLIN00, to VCU
      pdu triggering PT_SlaveResp_HVCH: pdu=SlaveResp_HVCH_oLIN00, to VCU
      pdu triggering PT_SlaveResp_PMP_1: pdu=SlaveResp_PMP_1_oLIN00, to VCU
      pdu triggering PT_SlaveResp_PMP_2: pdu=SlaveResp_PMP_2_oLIN00, to VCU
      pdu triggering PT_SlaveResp_SVA: pdu=SlaveResp_SVA_oLIN00, to VCU
      lin schedule table TCU_LIN_Schedule: run-mode=RUN-CONTINUOUS
        table-entrys:
          delay=0.01, position-in-table=0, frame-triggering=FT_EDCU_EXV2
          delay=0.01, position-in-table=1, frame-triggering=FT_EXV2_Status
          delay=0.1, position-in-table=2, frame-triggering=FT_VCU_EXV_1
          delay=0.1, position-in-table=3, frame-triggering=FT_EXV_1_VCU
          delay=0.1, position-in-table=4, frame-triggering=FT_VCU_EXV_2
          delay=0.1, position-in-table=5, frame-triggering=FT_EXV_2_VCU
          delay=0.01, position-in-table=6, frame-triggering=FT_PMP_Cmd
          delay=0.01, position-in-table=7, frame-triggering=FT_PMP2_Sts
          delay=0.01, position-in-table=8, frame-triggering=FT_PMP3_Sts
          delay=0.015, position-in-table=9, frame-triggering=FT_VCU_SVA_CMD
          delay=0.015, position-in-table=10, frame-triggering=FT_SVA_VCU_STD
          delay=0.02, position-in-table=11, frame-triggering=FT_TCU_HVCH_Cmd
          delay=0.02, position-in-table=12, frame-triggering=FT_HVCH_Rsp01
          delay=0.02, position-in-table=13, frame-triggering=FT_HVCH_Rsp02
  lin cluster LIN01: baudrate=19200, protocol-name=LIN, protocol-version=LIN21  # LIN4 | /*************************************************************************************/ // // Description: // Created: // Author: // Version: // Vehicle Project: // /*************************************************************************************/
    lin physical channel CHNL: comm-connectors=CN_LIN01
      frame MasterReq_oLIN01: id 0x3C, from VCU, frame-length=8, lin-checksum=CLASSIC
        n pdu MasterReq_Tp_oLIN01: length=8
      frame SlaveResp_oLIN01: id 0x3D, to VCU, frame-length=8, lin-checksum=CLASSIC
        n pdu SlaveResp_Tp_oLIN01: length=8
      frame Vcu_Lin0_RxMsg1_oLIN01: id 0x20, to VCU, frame-length=8, lin-checksum=ENHANCED
        pdu Vcu_Lin0_RxMsg1_oLIN01: length=8, unused-bit-pattern=255
          signal Vcu_Lin0_RxMsg1_Sig1_oVcu_Lin0_RxMsg1_oLIN01: start 0, 8 bit, little-endian, i-signal-type=PRIMITIVE, init-value=0, base-type=uint8, compu-method=CM_Vcu_Lin0_RxMsg1_Sig1, data-constr=DC_Vcu_Lin0_RxMsg1_Sig1, to VCU
          signal Vcu_Lin0_RxMsg1_Sig0_oVcu_Lin0_RxMsg1_oLIN01: start 8, 8 bit, little-endian, i-signal-type=PRIMITIVE, init-value=0, base-type=uint8, compu-method=CM_Vcu_Lin0_RxMsg1_Sig0, data-constr=DC_Vcu_Lin0_RxMsg1_Sig0, to VCU
          signal Vcu_Lin0_RxMsg2_Sig2_oVcu_Lin0_RxMsg1_oLIN01: start 16, 8 bit, little-endian, i-signal-type=PRIMITIVE, init-value=0, base-type=uint8, compu-method=CM_Vcu_Lin0_RxMsg2_Sig2, data-constr=DC_Vcu_Lin0_RxMsg2_Sig2, to VCU
          signal Vcu_Lin0_RxMsg2_Sig3_oVcu_Lin0_RxMsg1_oLIN01: start 24, 8 bit, little-endian, i-signal-type=PRIMITIVE, init-value=0, base-type=uint8, compu-method=CM_Vcu_Lin0_RxMsg2_Sig3, data-constr=DC_Vcu_Lin0_RxMsg2_Sig3, to VCU
      frame Vcu_Lin0_RxMsg2_oLIN01: id 0x21, to VCU, frame-length=8, lin-checksum=ENHANCED
        pdu Vcu_Lin0_RxMsg2_oLIN01: length=8, unused-bit-pattern=255
          signal Vcu_Lin0_RxMsg2_Sig0_oVcu_Lin0_RxMsg2_oLIN01: start 0, 8 bit, little-endian, i-signal-type=PRIMITIVE, init-value=0, base-type=uint8, compu-method=CM_Vcu_Lin0_RxMsg2_Sig0, data-constr=DC_Vcu_Lin0_RxMsg2_Sig0, to VCU
          signal Vcu_Lin0_RxMsg2_Sig1_oVcu_Lin0_RxMsg2_oLIN01: start 8, 8 bit, little-endian, i-signal-type=PRIMITIVE, init-value=0, base-type=uint8, compu-method=CM_Vcu_Lin0_RxMsg2_Sig1, data-constr=DC_Vcu_Lin0_RxMsg2_Sig1, to VCU
          signal Vcu_Lin0_RxMsg2_Sig2_oVcu_Lin0_RxMsg2_oLIN01: start 16, 8 bit, little-endian, i-signal-type=PRIMITIVE, init-value=0, base-type=uint8, compu-method=CM_Vcu_Lin0_RxMsg2_Sig2, data-constr=DC_Vcu_Lin0_RxMsg2_Sig2, to VCU
          signal Vcu_Lin0_RxMsg2_Sig3_oVcu_Lin0_RxMsg2_oLIN01: start 32, 8 bit, little-endian, i-signal-type=PRIMITIVE, init-value=0, base-type=uint8, compu-method=CM_Vcu_Lin0_RxMsg2_Sig3, data-constr=DC_Vcu_Lin0_RxMsg2_Sig3, to VCU
      frame Vcu_Lin0_TxMsg1_oLIN01: id 0x1E, from VCU, frame-length=8, lin-checksum=ENHANCED
        pdu Vcu_Lin0_TxMsg1_oLIN01: length=8, unused-bit-pattern=255
          signal Vcu_Lin0_TxMsg1_Sig0_oVcu_Lin0_TxMsg1_oLIN01: start 0, 8 bit, little-endian, i-signal-type=PRIMITIVE, init-value=0, base-type=uint8, compu-method=CM_Vcu_Lin0_TxMsg1_Sig0, data-constr=DC_Vcu_Lin0_TxMsg1_Sig0
          signal Vcu_Lin0_TxMsg1_Sig1_oVcu_Lin0_TxMsg1_oLIN01: start 8, 8 bit, little-endian, i-signal-type=PRIMITIVE, init-value=0, base-type=uint8, compu-method=CM_Vcu_Lin0_TxMsg1_Sig1, data-constr=DC_Vcu_Lin0_TxMsg1_Sig1
          signal Vcu_Lin0_TxMsg1_Sig2_oVcu_Lin0_TxMsg1_oLIN01: start 16, 8 bit, little-endian, i-signal-type=PRIMITIVE, init-value=0, base-type=uint8, compu-method=CM_Vcu_Lin0_TxMsg1_Sig2, data-constr=DC_Vcu_Lin0_TxMsg1_Sig2
          signal Vcu_Lin0_TxMsg1_Sig3_oVcu_Lin0_TxMsg1_oLIN01: start 24, 8 bit, little-endian, i-signal-type=PRIMITIVE, init-value=0, base-type=uint8, compu-method=CM_Vcu_Lin0_TxMsg1_Sig3, data-constr=DC_Vcu_Lin0_TxMsg1_Sig3
      frame Vcu_Lin0_TxMsg2_oLIN01: id 0x1F, from VCU, frame-length=8, lin-checksum=ENHANCED
        pdu Vcu_Lin0_TxMsg2_oLIN01: length=8, unused-bit-pattern=255
          signal Vcu_Lin0_TxMsg2_Sig0_oVcu_Lin0_TxMsg2_oLIN01: start 0, 8 bit, little-endian, i-signal-type=PRIMITIVE, init-value=0, base-type=uint8, compu-method=CM_Vcu_Lin0_TxMsg2_Sig0, data-constr=DC_Vcu_Lin0_TxMsg2_Sig0
          signal Vcu_Lin0_TxMsg2_Sig1_oVcu_Lin0_TxMsg2_oLIN01: start 8, 8 bit, little-endian, i-signal-type=PRIMITIVE, init-value=0, base-type=uint8, compu-method=CM_Vcu_Lin0_TxMsg2_Sig1, data-constr=DC_Vcu_Lin0_TxMsg2_Sig1
          signal Vcu_Lin0_TxMsg2_Sig2_oVcu_Lin0_TxMsg2_oLIN01: start 16, 8 bit, little-endian, i-signal-type=PRIMITIVE, init-value=0, base-type=uint8, compu-method=CM_Vcu_Lin0_TxMsg2_Sig2, data-constr=DC_Vcu_Lin0_TxMsg2_Sig2
          signal Vcu_Lin0_TxMsg2_Sig3_oVcu_Lin0_TxMsg2_oLIN01: start 24, 8 bit, little-endian, i-signal-type=PRIMITIVE, init-value=0, base-type=uint8, compu-method=CM_Vcu_Lin0_TxMsg2_Sig3, data-constr=DC_Vcu_Lin0_TxMsg2_Sig3
      pdu triggering PT_MasterReq: pdu=MasterReq_oLIN01, from VCU
      pdu triggering PT_MasterReq_GWM: pdu=MasterReq_GWM_oLIN01, from VCU
      pdu triggering PT_SlaveResp_GWM: pdu=SlaveResp_GWM_oLIN01, to VCU
      lin schedule table Vcu_Lin0_Schedule: run-mode=RUN-CONTINUOUS
        table-entrys:
          delay=0.02, position-in-table=0, frame-triggering=FT_Vcu_Lin0_TxMsg1
          delay=0.02, position-in-table=1, frame-triggering=FT_Vcu_Lin0_TxMsg2
          delay=0.02, position-in-table=2, frame-triggering=FT_Vcu_Lin0_RxMsg1
          delay=0.02, position-in-table=3, frame-triggering=FT_Vcu_Lin0_RxMsg2
